VERSION ""

NS_ :

BS_:

BU_: TCM HCM IPMA_ADAS PSCM ABS_ESC TCCM TCM_DSL PCM_HEV PCM ECM_HEVDSL ECM_HEV ECM_Diesel ECM SIMA_DLCS BCMD_IPDB VDM CMR_DSMC SOBDMC_HPCM_FD1 CHCM GWM _delete AWD_DLCM GENERIC TSTR

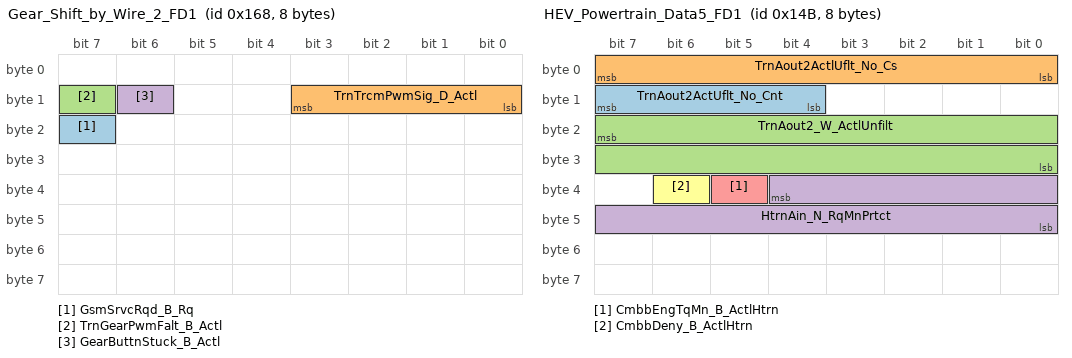
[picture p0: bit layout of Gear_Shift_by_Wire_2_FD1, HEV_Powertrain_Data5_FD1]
BO_ 360 Gear_Shift_by_Wire_2_FD1: 8 GWM
 SG_ GsmSrvcRqd_B_Rq : 23|1@0+ (1,0) [0|1] "SED"  TCM,SOBDMC_HPCM_FD1,TCM_DSL
 SG_ TrnTrcmPwmSig_D_Actl : 11|4@0+ (1,0) [0|15] "SED"  TCM,SOBDMC_HPCM_FD1,ECM_HEV,PCM,PCM_HEV,TCM_DSL
 SG_ TrnGearPwmFalt_B_Actl : 15|1@0+ (1,0) [0|1] "SED"  TCM,SOBDMC_HPCM_FD1,ECM_HEV,PCM,PCM_HEV,TCM_DSL
 SG_ GearButtnStuck_B_Actl : 14|1@0+ (1,0) [0|1] "SED"  TCM,SOBDMC_HPCM_FD1,ECM_HEV,PCM,PCM_HEV,TCM_DSL

BO_ 331 HEV_Powertrain_Data5_FD1: 8 GWM
 SG_ TrnAout2ActUflt_No_Cnt : 15|4@0+ (1,0) [0|15] "Unitless"  GWM,ECM_HEV
 SG_ TrnAout2ActlUflt_No_Cs : 7|8@0+ (1,0) [0|255] "Unitless"  GWM,ECM_HEV
 SG_ TrnAout2_W_ActlUnfilt : 23|16@0+ (0.1,-3276.5) [-3276.5|3276.8] "rad/s"  GWM,ABS_ESC,ECM_HEV
 SG_ HtrnAin_N_RqMnPrtct : 36|13@0+ (2,0) [0|16382] "RPM"  GWM,ECM_HEV
 SG_ CmbbEngTqMn_B_ActlHtrn : 37|1@0+ (1,0) [0|1] "SED"  GWM,ECM_HEV
 SG_ CmbbDeny_B_ActlHtrn : 38|1@0+ (1,0) [0|1] "SED"  GWM,ECM_HEV

BO_ 140 CruiseCtrl_StrgData2_FD1: 8 GWM
 SG_ CcAslButtnIndxIncPress2 : 18|1@0+ (1,0) [0|1] "SED"  ECM,ECM_HEVDSL,PCM
 SG_ SteWhlSwtchMde_D_Stat : 23|2@0+ (1,0) [0|3] "SED"  GENERIC
 SG_ CcAslButtnIndxDecPress2 : 19|1@0+ (1,0) [0|1] "SED"  ECM,ECM_HEVDSL,PCM
 SG_ CcAslButtnResIncPress3 : 29|1@0+ (1,0) [0|1] "SED"  PCM,ECM_HEVDSL,ECM
 SG_ CcButtnOnPress3 : 37|1@0+ (1,0) [0|1] "SED"  PCM,ECM_HEVDSL,ECM
 SG_ CcButtnOnOffPress3 : 38|1@0+ (1,0) [0|1] "SED"  PCM,ECM_HEVDSL,ECM
 SG_ CcButtnOnOffCnclPress3 : 39|1@0+ (1,0) [0|1] "SED"  PCM,ECM_HEVDSL,ECM
 SG_ CcButtnOffPress3 : 24|1@0+ (1,0) [0|1] "SED"  PCM,ECM_HEVDSL,ECM
 SG_ CcAsllButtnResPress3 : 25|1@0+ (1,0) [0|1] "SED"  PCM,ECM_HEVDSL,ECM
 SG_ CcAslButtnSetPress3 : 26|1@0+ (1,0) [0|1] "SED"  PCM,ECM_HEVDSL,ECM
 SG_ CcAslButtnSetIncPress3 : 27|1@0+ (1,0) [0|1] "SED"  PCM,ECM_HEVDSL,ECM
 SG_ CcAslButtnSetDecPress3 : 28|1@0+ (1,0) [0|1] "SED"  PCM,ECM_HEVDSL,ECM
 SG_ CcAslButtnResDecPress3 : 30|1@0+ (1,0) [0|1] "SED"  PCM,ECM_HEVDSL,ECM
 SG_ CcAslButtnOnPress3 : 31|1@0+ (1,0) [0|1] "SED"  PCM,ECM_HEVDSL,ECM
 SG_ CcAslButtnOnOffCncl3 : 16|1@0+ (1,0) [0|1] "SED"  PCM,ECM_HEVDSL,ECM
 SG_ CcAslButtnDeny_B_Actl3 : 20|1@0+ (1,0) [0|1] "SED"  PCM,ECM_HEVDSL,ECM
 SG_ CcAslButtnCnclPress3 : 8|1@0+ (1,0) [0|1] "SED"  PCM,ECM_HEVDSL,ECM
 SG_ AslButtnOnOffPress3 : 9|1@0+ (1,0) [0|1] "SED"  PCM,ECM_HEVDSL,ECM
 SG_ AslButtnOnOffCnclPress2 : 10|1@0+ (1,0) [0|1] "SED"  PCM,ECM_HEVDSL,ECM
 SG_ CcAslButtnOffCnclPress2 : 17|1@0+ (1,0) [0|1] "SED"  ECM_HEVDSL,PCM,ECM
 SG_ CcAslButtnCnclResPress2 : 21|1@0+ (1,0) [0|1] "SED"  ECM,ECM_HEVDSL,PCM

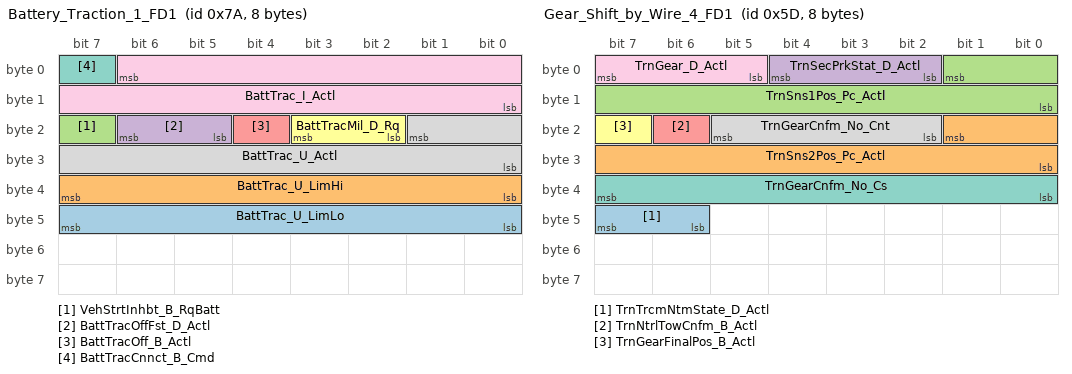
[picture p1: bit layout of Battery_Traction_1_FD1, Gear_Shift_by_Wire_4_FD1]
BO_ 122 Battery_Traction_1_FD1: 8 GWM
 SG_ BattTrac_U_LimLo : 47|8@0+ (2,0) [0|510] "volt"  SOBDMC_HPCM_FD1,PCM_HEV
 SG_ BattTrac_U_LimHi : 39|8@0+ (2,0) [0|510] "volt"  SOBDMC_HPCM_FD1,PCM_HEV
 SG_ VehStrtInhbt_B_RqBatt : 23|1@0+ (1,0) [0|1] "SED"  SOBDMC_HPCM_FD1,PCM_HEV,ECM_HEVDSL
 SG_ BattTracOffFst_D_Actl : 22|2@0+ (1,0) [0|3] "SED"  SOBDMC_HPCM_FD1,ECM_HEV,ECM_HEVDSL,PCM_HEV
 SG_ BattTracOff_B_Actl : 20|1@0+ (1,0) [0|1] "SED"  SOBDMC_HPCM_FD1,PCM_HEV
 SG_ BattTracMil_D_Rq : 19|2@0+ (1,0) [0|3] "SED"  PCM_HEV,ECM_HEV
 SG_ BattTracCnnct_B_Cmd : 7|1@0+ (1,0) [0|1] "SED"  SOBDMC_HPCM_FD1,ECM_HEV,ECM_HEVDSL,PCM_HEV
 SG_ BattTrac_U_Actl : 17|10@0+ (0.5,0) [0|510.5] "Volts"  SOBDMC_HPCM_FD1,ECM_HEV,ECM_HEVDSL,PCM_HEV
 SG_ BattTrac_I_Actl : 6|15@0+ (0.05,-750) [-750|888.25] "Amps"  SOBDMC_HPCM_FD1,ECM_HEV,ECM_HEVDSL,PCM_HEV

BO_ 93 Gear_Shift_by_Wire_4_FD1: 8 GWM
 SG_ TrnTrcmNtmState_D_Actl : 47|2@0+ (1,0) [0|3] "SED"  TCM,ECM_HEV,PCM,PCM_HEV,TCM_DSL
 SG_ TrnSns2Pos_Pc_Actl : 17|10@0+ (0.1,0) [0|102.2] "percent duty cycle"  ECM_HEV,PCM,PCM_HEV
 SG_ TrnSns1Pos_Pc_Actl : 1|10@0+ (0.1,0) [0|102.2] "percent duty cycle"  ECM_HEV,PCM,PCM_HEV
 SG_ TrnSecPrkStat_D_Actl : 4|3@0+ (1,0) [0|7] "SED"  ECM_HEV,PCM,PCM_HEV
 SG_ TrnNtrlTowCnfm_B_Actl : 22|1@0+ (1,0) [0|1] "SED"  ECM_HEV,PCM,PCM_HEV
 SG_ TrnGearFinalPos_B_Actl : 23|1@0+ (1,0) [0|1] "SED"  ECM_HEV,PCM,PCM_HEV
 SG_ TrnGearCnfm_No_Cs : 39|8@0+ (1,0) [0|255] "Unitless"  ECM_HEV,PCM,PCM_HEV
 SG_ TrnGearCnfm_No_Cnt : 21|4@0+ (1,0) [0|15] "Unitless"  ECM_HEV,PCM,PCM_HEV
 SG_ TrnGear_D_Actl : 7|3@0+ (1,0) [0|7] "SED"  ECM_HEV,PCM,PCM_HEV

BO_ 90 Gear_Shift_by_Wire_FD1: 8 GWM
 SG_ TrnGsmNtmState_D_Actl : 55|2@0+ (1,0) [0|3] "SED"  TCM,SOBDMC_HPCM_FD1,ABS_ESC,ECM_HEV,PCM,PCM_HEV,TCM_DSL
 SG_ DrQltyDrv_D_StatGsm : 42|3@0+ (1,0) [0|7] "SED"  TCM,SOBDMC_HPCM_FD1,ABS_ESC,ECM,ECM_HEV,ECM_HEVDSL,PCM,PCM_HEV,TCM_DSL,IPMA_ADAS
 SG_ TrnBtsiOvrrd_B_Stat : 43|1@0+ (1,0) [0|1] "SED"  ABS_ESC,TCM,SOBDMC_HPCM_FD1,ECM,ECM_HEV,ECM_HEVDSL,PCM,PCM_HEV,TCM_DSL
 SG_ GsmGearMsgTxt_D_Rq : 63|2@0+ (1,0) [0|3] "SED"  SOBDMC_HPCM_FD1,GENERIC
 SG_ TrnRng_D_RqGsm : 51|4@0+ (1,0) [0|15] "SED"  TCM,SOBDMC_HPCM_FD1,ECM,ECM_HEV,ECM_HEVDSL,PCM,TCM_DSL
 SG_ PrkBrkActv_D_RqGsmGear : 53|2@0+ (1,0) [0|3] "SED"  SOBDMC_HPCM_FD1,ABS_ESC
 SG_ TrnValidGearRq_D_Stat : 25|2@0+ (1,0) [0|3] "SED"  ABS_ESC,TCM,SOBDMC_HPCM_FD1,ECM_HEV,PCM,PCM_HEV,TCM_DSL
 SG_ TrnGearRqCnt_B_Actl : 26|1@0+ (1,0) [0|1] "unitless"  ABS_ESC,TCM,SOBDMC_HPCM_FD1,ECM_HEV,PCM,PCM_HEV,TCM_DSL
 SG_ TrnGearButtn_U_Actl : 23|8@0+ (0.05,0) [0|12.7] "VOLT"  TCM,SOBDMC_HPCM_FD1,ECM_HEV,PCM,PCM_HEV,TCM_DSL
 SG_ TrnGearButtn_B_ActlR2 : 8|1@0+ (1,0) [0|1] "SED"  TCM,SOBDMC_HPCM_FD1,ECM_HEV,PCM,PCM_HEV,TCM_DSL
 SG_ TrnGearButtn_B_ActlR1 : 9|1@0+ (1,0) [0|1] "SED"  TCM,SOBDMC_HPCM_FD1,ECM_HEV,PCM,PCM_HEV,TCM_DSL
 SG_ TrnGearButtn_B_ActlR0 : 10|1@0+ (1,0) [0|1] "SED"  TCM,SOBDMC_HPCM_FD1,ECM_HEV,PCM,PCM_HEV,TCM_DSL
 SG_ TrnGearButtn_B_ActlP2 : 11|1@0+ (1,0) [0|1] "SED"  TCM,SOBDMC_HPCM_FD1,TCM_DSL,ECM_HEV,PCM,PCM_HEV
 SG_ TrnGearButtn_B_ActlP1 : 12|1@0+ (1,0) [0|1] "SED"  TCM,SOBDMC_HPCM_FD1,ECM_HEV,PCM,PCM_HEV,TCM_DSL
 SG_ TrnGearButtn_B_ActlP0 : 13|1@0+ (1,0) [0|1] "SED"  TCM,SOBDMC_HPCM_FD1,ECM_HEV,PCM,PCM_HEV,TCM_DSL
 SG_ TrnGearButtn_B_ActlN2 : 14|1@0+ (1,0) [0|1] "SED"  TCM,SOBDMC_HPCM_FD1,ECM_HEV,PCM,PCM_HEV,TCM_DSL
 SG_ TrnGearButtn_B_ActlN1 : 15|1@0+ (1,0) [0|1] "SED"  TCM,SOBDMC_HPCM_FD1,ECM_HEV,PCM,PCM_HEV,TCM_DSL
 SG_ TrnGearButtn_B_ActlN0 : 0|1@0+ (1,0) [0|1] "SED"  TCM,SOBDMC_HPCM_FD1,ECM_HEV,PCM,PCM_HEV,TCM_DSL
 SG_ TrnGearButtn_B_ActlM2 : 1|1@0+ (1,0) [0|1] "SED"  TCM,SOBDMC_HPCM_FD1,ECM_HEV,PCM,PCM_HEV,TCM_DSL
 SG_ TrnGearButtn_B_ActlM1 : 2|1@0+ (1,0) [0|1] "SED"  TCM,SOBDMC_HPCM_FD1,ECM_HEV,PCM,PCM_HEV,TCM_DSL
 SG_ TrnGearButtn_B_ActlM0 : 3|1@0+ (1,0) [0|1] "SED"  TCM,SOBDMC_HPCM_FD1,ECM_HEV,PCM,PCM_HEV,TCM_DSL
 SG_ TrnGearButtn_B_ActlD2 : 4|1@0+ (1,0) [0|1] "SED"  TCM,SOBDMC_HPCM_FD1,ECM_HEV,PCM,PCM_HEV,TCM_DSL
 SG_ TrnGearButtn_B_ActlD1 : 5|1@0+ (1,0) [0|1] "SED"  TCM,SOBDMC_HPCM_FD1,ECM_HEV,PCM,PCM_HEV,TCM_DSL
 SG_ TrnGearButtn_B_ActlD0 : 6|1@0+ (1,0) [0|1] "SED"  TCM,SOBDMC_HPCM_FD1,ECM_HEV,PCM,PCM_HEV,TCM_DSL
 SG_ TrnGear_No_Cs : 39|8@0+ (1,0) [0|255] "Unitless"  ABS_ESC,TCM,SOBDMC_HPCM_FD1,ECM_HEV,PCM,PCM_HEV,TCM_DSL
 SG_ TrnGear_No_Cnt : 47|4@0+ (1,0) [0|15] "Unitless"  ABS_ESC,TCM,SOBDMC_HPCM_FD1,ECM_HEV,PCM,PCM_HEV,TCM_DSL
 SG_ TrnGear_D_RqDrv : 31|5@0+ (1,0) [0|31] "SED"  ABS_ESC,TCM,SOBDMC_HPCM_FD1,ECM_HEV,PCM,PCM_HEV,TCM_DSL
 SG_ BrkSwtchPos_B_ActlGsm : 7|1@0+ (1,0) [0|1] "SED"  ABS_ESC,TCM,SOBDMC_HPCM_FD1,ECM_HEV,PCM,PCM_HEV,TCM_DSL

BO_ 1114 TrailerAid_Data_FD1: 8 GWM
 SG_ TrailCtlSwtch_B_Stat2 : 16|1@0+ (1,0) [0|1] "SED"  ABS_ESC
 SG_ TrlBrkInitOut_D_Rq : 60|2@0+ (1,0) [0|3] "SED"  GENERIC

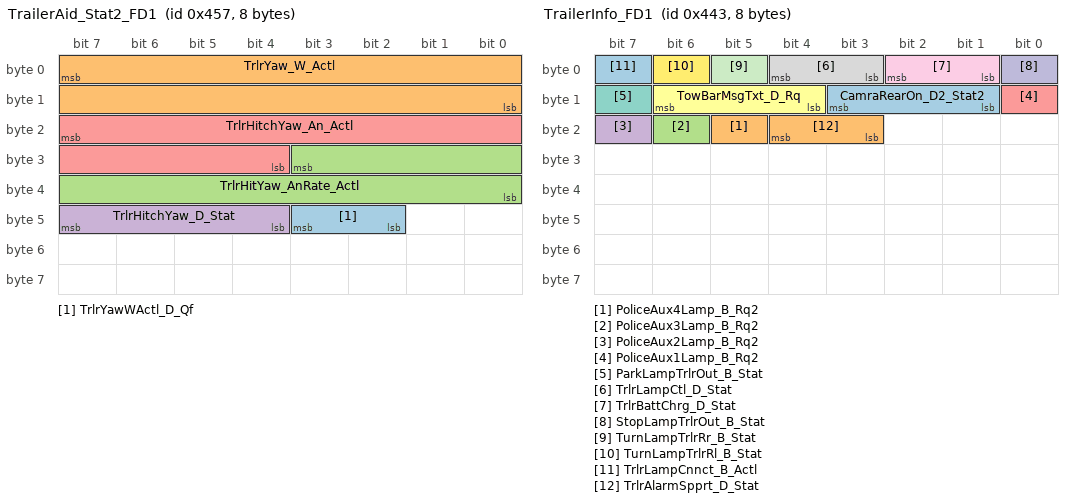
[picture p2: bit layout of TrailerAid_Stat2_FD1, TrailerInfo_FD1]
BO_ 1111 TrailerAid_Stat2_FD1: 8 GWM
 SG_ TrlrYawWActl_D_Qf : 43|2@0+ (1,0) [0|3] "SED"  IPMA_ADAS,PSCM
 SG_ TrlrYaw_W_Actl : 7|16@0+ (0.0002,-6.5) [-6.5|6.6066] "radians/second"  IPMA_ADAS,PSCM
 SG_ TrlrHitYaw_AnRate_Actl : 27|12@0+ (0.1,-50) [-50|359.3] "degrees/second"  IPMA_ADAS,PSCM
 SG_ TrlrHitchYaw_D_Stat : 47|4@0+ (1,0) [0|15] "SED"  IPMA_ADAS,PSCM
 SG_ TrlrHitchYaw_An_Actl : 23|12@0+ (0.1,-90) [-90|319.3] "degrees"  IPMA_ADAS,PSCM

BO_ 1106 TrailerAid_Stat1_FD1: 8 GWM
 SG_ TrlrSnsId_No_Actl : 7|48@0+ (1,0) [0|281474976710653] "unitless"  PSCM,IPMA_ADAS

BO_ 1091 TrailerInfo_FD1: 8 GWM
 SG_ CamraRearOn_D2_Stat2 : 11|3@0+ (1,0) [0|7] "SED"  GENERIC
 SG_ PoliceAux4Lamp_B_Rq2 : 21|1@0+ (1,0) [0|1] "SED"  GENERIC
 SG_ PoliceAux3Lamp_B_Rq2 : 22|1@0+ (1,0) [0|1] "SED"  GENERIC
 SG_ PoliceAux2Lamp_B_Rq2 : 23|1@0+ (1,0) [0|1] "SED"  GENERIC
 SG_ PoliceAux1Lamp_B_Rq2 : 8|1@0+ (1,0) [0|1] "SED"  GENERIC
 SG_ TowBarMsgTxt_D_Rq : 14|3@0+ (1,0) [0|7] "SED"  GENERIC
 SG_ ParkLampTrlrOut_B_Stat : 15|1@0+ (1,0) [0|1] "SED"  GENERIC
 SG_ TrlrLampCtl_D_Stat : 4|2@0+ (1,0) [0|3] "SED"  GENERIC
 SG_ TrlrBattChrg_D_Stat : 2|2@0+ (1,0) [0|3] "SED"  GENERIC
 SG_ StopLampTrlrOut_B_Stat : 0|1@0+ (1,0) [0|1] "SED"  GENERIC
 SG_ TurnLampTrlrRr_B_Stat : 5|1@0+ (1,0) [0|1] "SED"  GENERIC
 SG_ TurnLampTrlrRl_B_Stat : 6|1@0+ (1,0) [0|1] "SED"  GENERIC
 SG_ TrlrLampCnnct_B_Actl : 7|1@0+ (1,0) [0|1] "SED"  TCM,VDM,ECM,ECM_Diesel,ECM_HEV,ECM_HEVDSL,PCM,PCM_HEV,TCM_DSL,ABS_ESC,IPMA_ADAS,PSCM,AWD_DLCM
 SG_ TrlrAlarmSpprt_D_Stat : 20|2@0+ (1,0) [0|3] "SED"  GENERIC

BO_ 138 ActiveFrontStrg_Stat2_FD1: 8 GWM
 SG_ SteWhlRelCalib_T_Actl : 7|8@0+ (1,0) [0|255] "ms"  ABS_ESC
 SG_ SteWhlRelCalib_An_Sns : 15|15@0+ (0.1,-1600) [-1600|1676.5] "deg"  CMR_DSMC,ABS_ESC,PSCM,TCCM

BO_ 131 Steering_Data_FD1: 8 GWM
 SG_ HeadLghtHiCtrl_D_RqAhb : 43|3@0+ (1,0) [0|7] "SED"  HCM,GENERIC
 SG_ AhbStat_B_Dsply : 33|1@0+ (1,0) [0|1] "SED"  GENERIC
 SG_ WiprFrontSwtch_D_Stat : 47|4@0+ (1,0) [0|15] "SED"  GENERIC
 SG_ HeadLghtHiOn_B_StatAhb : 34|1@0+ (1,0) [0|1] "SED"  IPMA_ADAS
 SG_ HeadLghtHiFlash_D_Actl : 36|2@0+ (1,0) [0|3] "SED"  HCM,IPMA_ADAS
 SG_ TjaButtnOnOffPress : 40|1@0+ (1,0) [0|1] "SED"  ECM,ECM_Diesel,ECM_HEVDSL,IPMA_ADAS,PCM,PCM_HEV
 SG_ AccButtnGapTogglePress : 32|1@0+ (1,0) [0|1] "SED"  IPMA_ADAS
 SG_ WiprFront_D_Stat : 3|4@0+ (1,0) [0|15] "SED"  HCM,ABS_ESC,ECM,ECM_Diesel,ECM_HEV,ECM_HEVDSL,IPMA_ADAS,PCM,PCM_HEV,AWD_DLCM
 SG_ TurnLghtSwtch_D_Stat : 5|2@0+ (1,0) [0|3] "SED"  HCM,IPMA_ADAS,PSCM
 SG_ LghtAmb_D_Sns : 15|3@0+ (1,0) [0|7] "SED"  HCM,IPMA_ADAS
 SG_ AccButtnGapIncPress : 11|1@0+ (1,0) [0|1] "SED"  IPMA_ADAS
 SG_ AccButtnGapDecPress : 12|1@0+ (1,0) [0|1] "SED"  IPMA_ADAS
 SG_ AslButtnOnOffPress : 9|1@0+ (1,0) [0|1] "SED"  ECM,ECM_Diesel,ECM_HEV,ECM_HEVDSL,PCM,PCM_HEV
 SG_ AslButtnOnOffCnclPress : 10|1@0+ (1,0) [0|1] "SED"  ECM,ECM_Diesel,ECM_HEV,ECM_HEVDSL,PCM,PCM_HEV
 SG_ CcButtnOnPress : 37|1@0+ (1,0) [0|1] "SED"  ECM,ECM_Diesel,ECM_HEV,ECM_HEVDSL,IPMA_ADAS,PCM,PCM_HEV
 SG_ CcButtnOnOffPress : 38|1@0+ (1,0) [0|1] "SED"  ECM,ECM_Diesel,ECM_HEV,ECM_HEVDSL,IPMA_ADAS,PCM,PCM_HEV
 SG_ CcButtnOnOffCnclPress : 39|1@0+ (1,0) [0|1] "SED"  ECM,ECM_Diesel,ECM_HEV,ECM_HEVDSL,IPMA_ADAS,PCM,PCM_HEV
 SG_ CcButtnOffPress : 24|1@0+ (1,0) [0|1] "SED"  ECM,ECM_Diesel,ECM_HEV,ECM_HEVDSL,IPMA_ADAS,PCM,PCM_HEV
 SG_ CcAsllButtnResPress : 25|1@0+ (1,0) [0|1] "SED"  ECM,ECM_Diesel,ECM_HEV,ECM_HEVDSL,IPMA_ADAS,PCM,PCM_HEV
 SG_ CcAslButtnSetPress : 26|1@0+ (1,0) [0|1] "SED"  ECM,ECM_Diesel,ECM_HEV,ECM_HEVDSL,PCM,PCM_HEV
 SG_ CcAslButtnSetIncPress : 27|1@0+ (1,0) [0|1] "SED"  ABS_ESC,ECM,ECM_Diesel,ECM_HEV,ECM_HEVDSL,IPMA_ADAS,PCM,PCM_HEV
 SG_ CcAslButtnSetDecPress : 28|1@0+ (1,0) [0|1] "SED"  ABS_ESC,ECM,ECM_Diesel,ECM_HEV,ECM_HEVDSL,IPMA_ADAS,PCM,PCM_HEV
 SG_ CcAslButtnResIncPress : 29|1@0+ (1,0) [0|1] "SED"  ABS_ESC,ECM,ECM_Diesel,ECM_HEV,ECM_HEVDSL,IPMA_ADAS,PCM,PCM_HEV
 SG_ CcAslButtnResDecPress : 30|1@0+ (1,0) [0|1] "SED"  ECM,ECM_Diesel,ECM_HEV,ECM_HEVDSL,PCM,PCM_HEV
 SG_ CcAslButtnOnPress : 31|1@0+ (1,0) [0|1] "SED"  ECM,ECM_Diesel,ECM_HEV,ECM_HEVDSL,IPMA_ADAS,PCM,PCM_HEV
 SG_ CcAslButtnOnOffCncl : 16|1@0+ (1,0) [0|1] "SED"  ECM,ECM_Diesel,ECM_HEV,ECM_HEVDSL,PCM,PCM_HEV
 SG_ CcAslButtnOffCnclPress : 17|1@0+ (1,0) [0|1] "SED"  ECM,ECM_Diesel,ECM_HEV,ECM_HEVDSL,PCM,PCM_HEV
 SG_ CcAslButtnIndxIncPress : 18|1@0+ (1,0) [0|1] "SED"  ECM,ECM_Diesel,ECM_HEV,ECM_HEVDSL,PCM,PCM_HEV
 SG_ CcAslButtnIndxDecPress : 19|1@0+ (1,0) [0|1] "SED"  ECM,ECM_Diesel,ECM_HEV,ECM_HEVDSL,PCM,PCM_HEV
 SG_ CcAslButtnDeny_B_Actl : 20|1@0+ (1,0) [0|1] "SED"  ECM,ECM_Diesel,ECM_HEV,ECM_HEVDSL,IPMA_ADAS,PCM,PCM_HEV
 SG_ CcAslButtnCnclResPress : 21|1@0+ (1,0) [0|1] "SED"  ECM,ECM_Diesel,ECM_HEV,ECM_HEVDSL,IPMA_ADAS,PCM,PCM_HEV
 SG_ CcAslButtnCnclPress : 8|1@0+ (1,0) [0|1] "SED"  ECM,ECM_Diesel,ECM_HEV,ECM_HEVDSL,IPMA_ADAS,PCM,PCM_HEV
 SG_ LaSwtchPos_D_Stat : 23|2@0+ (1,0) [0|3] "SED"  IPMA_ADAS
 SG_ HeadLghtHiFlash_D_Stat : 7|2@0+ (1,0) [0|3] "SED"  HCM,GENERIC

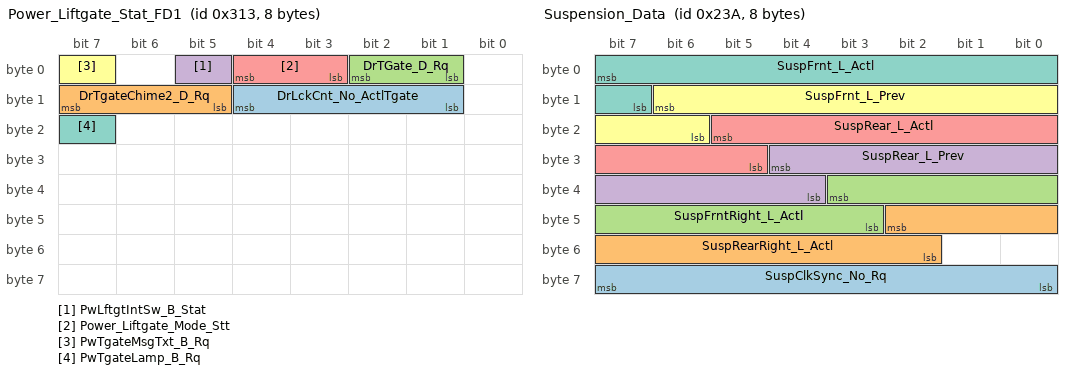
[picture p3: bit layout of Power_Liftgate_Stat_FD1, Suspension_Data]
BO_ 787 Power_Liftgate_Stat_FD1: 8 GWM
 SG_ DrLckCnt_No_ActlTgate : 12|4@0+ (1,0) [0|15] "unitless"  GENERIC
 SG_ DrTgateChime2_D_Rq : 15|3@0+ (1,0) [0|7] "SED"  GENERIC
 SG_ DrTGate_D_Rq : 2|2@0+ (1,0) [0|3] "SED"  ECM,ECM_Diesel,ECM_HEVDSL,PCM,PCM_HEV
 SG_ PwLftgtIntSw_B_Stat : 5|1@0+ (1,0) [0|1] "SED"  GENERIC
 SG_ Power_Liftgate_Mode_Stt : 4|2@0+ (1,0) [0|3] "SED"  GENERIC
 SG_ PwTgateMsgTxt_B_Rq : 7|1@0+ (1,0) [0|1] "SED"  GENERIC
 SG_ PwTgateLamp_B_Rq : 23|1@0+ (1,0) [0|1] "SED"  GENERIC

BO_ 570 Suspension_Data: 8 VDM
 SG_ SuspClkSync_No_Rq : 63|8@0+ (1,0) [0|253] "unitless"  GWM,IPMA_ADAS
 SG_ SuspRearRight_L_Actl : 42|9@0+ (0.782779,-200) [-200|199.21729] "millimeter"  HCM,GWM,ABS_ESC,PSCM,IPMA_ADAS
 SG_ SuspFrntRight_L_Actl : 35|9@0+ (0.782779,-200) [-200|199.21729] "millimeter"  HCM,ABS_ESC,PSCM,GWM,IPMA_ADAS
 SG_ SuspRear_L_Prev : 28|9@0+ (0.782779,-200) [-200|199.21729] "millimeter"  HCM,ABS_ESC,GWM
 SG_ SuspRear_L_Actl : 21|9@0+ (0.782779,-200) [-200|199.21729] "millimeter"  HCM,ABS_ESC,PSCM,GWM,IPMA_ADAS
 SG_ SuspFrnt_L_Prev : 14|9@0+ (0.782779,-200) [-200|199.21729] "millimeter"  HCM,ABS_ESC,GWM
 SG_ SuspFrnt_L_Actl : 7|9@0+ (0.782779,-200) [-200|199.21729] "millimeter"  HCM,PSCM,ABS_ESC,GWM,IPMA_ADAS

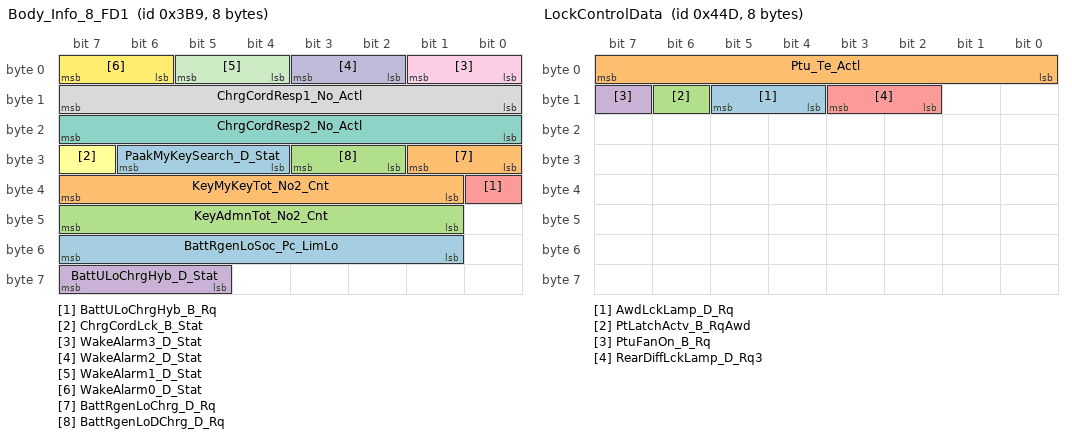
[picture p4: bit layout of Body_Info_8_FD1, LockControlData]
BO_ 953 Body_Info_8_FD1: 8 GWM
 SG_ PaakMyKeySearch_D_Stat : 30|3@0+ (1,0) [0|7] "SED"  GENERIC
 SG_ KeyMyKeyTot_No2_Cnt : 39|7@0+ (1,0) [0|127] "unitless"  GENERIC
 SG_ KeyAdmnTot_No2_Cnt : 47|7@0+ (1,0) [0|127] "unitless"  GENERIC
 SG_ BattULoChrgHyb_D_Stat : 63|3@0+ (1,0) [0|7] "SED"  GENERIC
 SG_ BattULoChrgHyb_B_Rq : 32|1@0+ (1,0) [0|1] "SED"  SOBDMC_HPCM_FD1
 SG_ ChrgCordLck_B_Stat : 31|1@0+ (1,0) [0|1] "SED"  GENERIC
 SG_ ChrgCordResp2_No_Actl : 23|8@0+ (1,0) [0|255] "unitless"  GENERIC
 SG_ ChrgCordResp1_No_Actl : 15|8@0+ (1,0) [0|255] "unitless"  GENERIC
 SG_ WakeAlarm3_D_Stat : 1|2@0+ (1,0) [0|3] "SED"  GENERIC
 SG_ WakeAlarm2_D_Stat : 3|2@0+ (1,0) [0|3] "SED"  GENERIC
 SG_ WakeAlarm1_D_Stat : 5|2@0+ (1,0) [0|3] "SED"  ECM_Diesel,ECM_HEV,ECM_HEVDSL,PCM,PCM_HEV,ECM
 SG_ WakeAlarm0_D_Stat : 7|2@0+ (1,0) [0|3] "SED"  SOBDMC_HPCM_FD1,GENERIC
 SG_ BattRgenLoSoc_Pc_LimLo : 55|7@0+ (1,0) [0|100] "percent"  GENERIC
 SG_ BattRgenLoChrg_D_Rq : 25|2@0+ (1,0) [0|3] "SED"  PCM,PCM_HEV
 SG_ BattRgenLoDChrg_D_Rq : 27|2@0+ (1,0) [0|3] "SED"  PCM,PCM_HEV

BO_ 1101 LockControlData: 8 AWD_DLCM
 SG_ AwdLckLamp_D_Rq : 13|2@0+ (1,0) [0|3] "SED"  GWM
 SG_ Ptu_Te_Actl : 7|8@0+ (1,-50) [-50|205] "degC"  ECM,ECM_Diesel,ECM_HEVDSL,PCM,GWM
 SG_ PtLatchActv_B_RqAwd : 14|1@0+ (1,0) [0|1] "SED"  ECM,ECM_Diesel,ECM_HEV,ECM_HEVDSL,PCM,PCM_HEV,GWM
 SG_ PtuFanOn_B_Rq : 15|1@0+ (1,0) [0|1] "SED"  ECM,ECM_Diesel,ECM_HEV,ECM_HEVDSL,PCM,PCM_HEV,GWM
 SG_ RearDiffLckLamp_D_Rq3 : 11|2@0+ (1,0) [0|3] "SED"  GWM

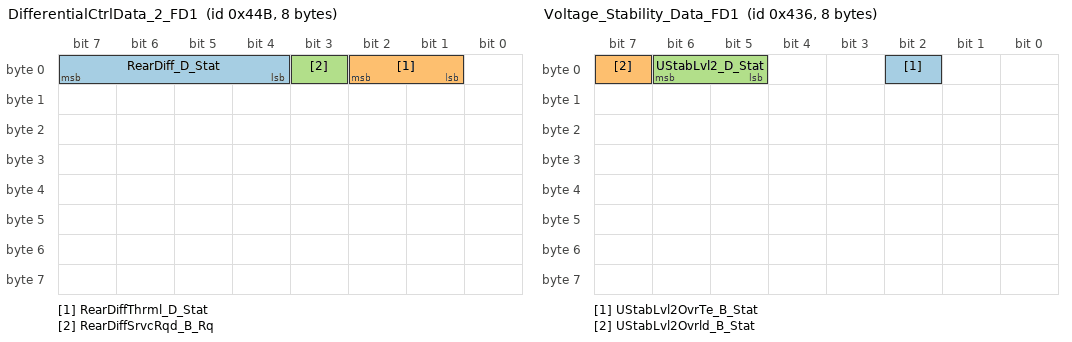
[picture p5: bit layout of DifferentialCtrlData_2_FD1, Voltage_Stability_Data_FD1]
BO_ 1099 DifferentialCtrlData_2_FD1: 8 GWM
 SG_ RearDiff_D_Stat : 7|4@0+ (1,0) [0|15] "SED"  ABS_ESC,PCM
 SG_ RearDiffThrml_D_Stat : 2|2@0+ (1,0) [0|3] "SED"  ECM,ABS_ESC,PCM
 SG_ RearDiffSrvcRqd_B_Rq : 3|1@0+ (1,0) [0|1] "SED"  ABS_ESC

BO_ 1078 Voltage_Stability_Data_FD1: 8 GWM
 SG_ UStabLvl2OvrTe_B_Stat : 2|1@0+ (1,0) [0|1] "SED"  ECM,ECM_Diesel,ECM_HEVDSL,PCM,PCM_HEV
 SG_ UStabLvl2Ovrld_B_Stat : 7|1@0+ (1,0) [0|1] "SED"  ECM,ECM_Diesel,ECM_HEVDSL,PCM,PCM_HEV
 SG_ UStabLvl2_D_Stat : 6|2@0+ (1,0) [0|3] "SED"  ECM,ECM_Diesel,ECM_HEVDSL,PCM,PCM_HEV

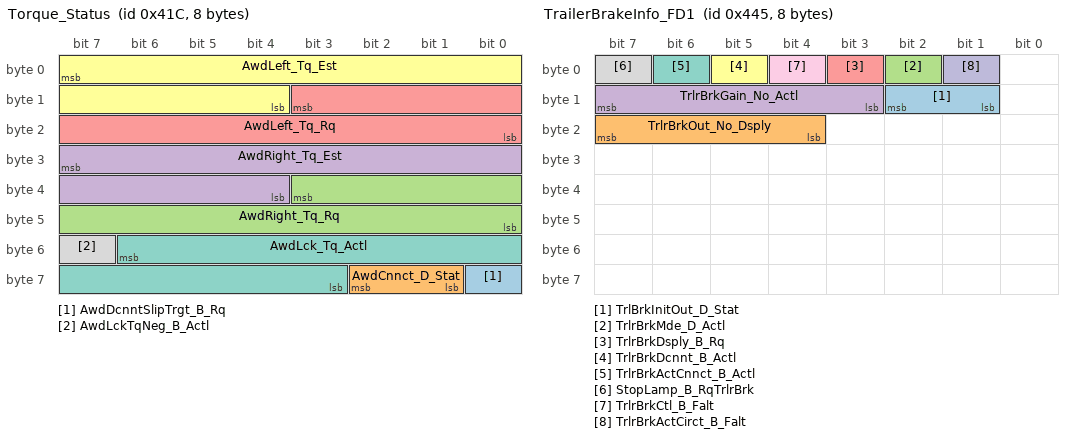
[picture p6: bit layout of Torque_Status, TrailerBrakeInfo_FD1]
BO_ 1052 Torque_Status: 8 AWD_DLCM
 SG_ AwdDcnntSlipTrgt_B_Rq : 56|1@0+ (1,0) [0|1] "SED"  ABS_ESC,GWM
 SG_ AwdCnnct_D_Stat : 58|2@0+ (1,0) [0|3] "SED"  ABS_ESC,GWM
 SG_ AwdRight_Tq_Rq : 35|12@0+ (1,0) [0|4093] "Nm"  ABS_ESC,GWM
 SG_ AwdRight_Tq_Est : 31|12@0+ (1,0) [0|4093] "Nm"  ABS_ESC,PCM,PCM_HEV,GWM
 SG_ AwdLeft_Tq_Rq : 11|12@0+ (1,0) [0|4093] "Nm"  ABS_ESC,GWM
 SG_ AwdLeft_Tq_Est : 7|12@0+ (1,0) [0|4093] "Nm"  ABS_ESC,PCM,PCM_HEV,GWM
 SG_ AwdLck_Tq_Actl : 54|12@0+ (1,0) [0|4093] "Nm"  SOBDMC_HPCM_FD1,ABS_ESC,PCM,PCM_HEV,PSCM,TCM,TCM_DSL,GWM
 SG_ AwdLckTqNeg_B_Actl : 55|1@0+ (1,0) [0|1] "SED"  ABS_ESC,PSCM,GWM,TCM,TCM_DSL

BO_ 1093 TrailerBrakeInfo_FD1: 8 GWM
 SG_ TrlBrkInitOut_D_Stat : 10|2@0+ (1,0) [0|3] "SED"  GENERIC
 SG_ TrlrBrkOut_No_Dsply : 23|4@0+ (1,0) [0|15] "unitless"  GENERIC
 SG_ TrlrBrkMde_D_Actl : 2|1@0+ (1,0) [0|1] "SED"  TCCM
 SG_ TrlrBrkGain_No_Actl : 15|5@0+ (0.5,0) [0|15.5] "unitless"  GENERIC
 SG_ TrlrBrkDsply_B_Rq : 3|1@0+ (1,0) [0|1] "SED"  GENERIC
 SG_ TrlrBrkDcnnt_B_Actl : 5|1@0+ (1,0) [0|1] "SED"  VDM,GENERIC
 SG_ TrlrBrkActCnnct_B_Actl : 6|1@0+ (1,0) [0|1] "SED"  TCM,VDM,ECM,ECM_Diesel,ECM_HEV,ECM_HEVDSL,PCM,PCM_HEV,TCM_DSL,ABS_ESC,PSCM,TCCM,IPMA_ADAS
 SG_ StopLamp_B_RqTrlrBrk : 7|1@0+ (1,0) [0|1] "SED"  GENERIC
 SG_ TrlrBrkCtl_B_Falt : 4|1@0+ (1,0) [0|1] "SED"  IPMA_ADAS
 SG_ TrlrBrkActCirct_B_Falt : 1|1@0+ (1,0) [0|1] "SED"  IPMA_ADAS

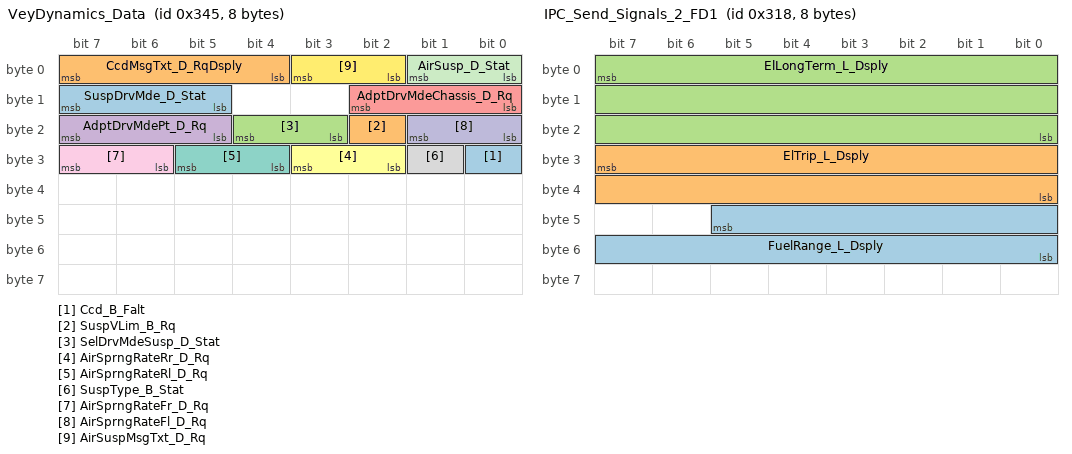
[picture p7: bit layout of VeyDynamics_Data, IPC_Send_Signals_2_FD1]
BO_ 837 VeyDynamics_Data: 8 VDM
 SG_ Ccd_B_Falt : 24|1@0+ (1,0) [0|1] "SED"  GWM,GENERIC
 SG_ SuspVLim_B_Rq : 18|1@0+ (1,0) [0|1] "SED"  GWM,ECM
 SG_ SelDrvMdeSusp_D_Stat : 20|2@0+ (1,0) [0|3] "SED"  GWM,ABS_ESC
 SG_ AdptDrvMdePt_D_Rq : 23|3@0+ (1,0) [0|7] "SED"  GWM,ABS_ESC
 SG_ AdptDrvMdeChassis_D_Rq : 10|3@0+ (1,0) [0|7] "SED"  GWM,ABS_ESC
 SG_ AirSprngRateRr_D_Rq : 27|2@0+ (1,0) [0|3] "SED"  GWM,GENERIC
 SG_ AirSprngRateRl_D_Rq : 29|2@0+ (1,0) [0|3] "SED"  GWM,GENERIC
 SG_ SuspType_B_Stat : 25|1@0+ (1,0) [0|1] "SED"  GWM,ECM,PCM
 SG_ AirSprngRateFr_D_Rq : 31|2@0+ (1,0) [0|3] "SED"  GWM,GENERIC
 SG_ AirSprngRateFl_D_Rq : 17|2@0+ (1,0) [0|3] "SED"  GWM,GENERIC
 SG_ AirSusp_D_Stat : 1|2@0+ (1,0) [0|3] "SED"  GWM,GENERIC
 SG_ AirSuspMsgTxt_D_Rq : 3|2@0+ (1,0) [0|3] "SED"  GWM,GENERIC
 SG_ SuspDrvMde_D_Stat : 15|3@0+ (1,0) [0|7] "SED"  GWM,ABS_ESC
 SG_ CcdMsgTxt_D_RqDsply : 7|4@0+ (1,0) [0|15] "SED"  GWM,ECM,ECM_Diesel,ECM_HEVDSL,PCM,PCM_HEV,ABS_ESC,PSCM,AWD_DLCM

BO_ 792 IPC_Send_Signals_2_FD1: 8 GWM
 SG_ FuelRange_L_Dsply : 45|14@0+ (0.1,0) [0|1638.3] "km"  ECM_Diesel,ECM_HEVDSL,ECM
 SG_ ElTrip_L_Dsply : 31|16@0+ (0.1,0) [0|6553.3] "unitless"  GENERIC
 SG_ ElLongTerm_L_Dsply : 7|24@0+ (0.1,0) [0|1677721.3] "unitless"  GENERIC

BO_ 968 Cluster_Lighting_Rq_FD1: 8 GWM
 SG_ RvltnMatchAllw_D_Rq : 58|2@0+ (1,0) [0|3] "SED"  ECM,PCM
 SG_ BrkDrvMde_D_Rq : 18|3@0+ (1,0) [0|7] "SED"  ABS_ESC
 SG_ LnchCtl_N_Rq : 55|8@0+ (50,0) [0|12750] "rpm"  ABS_ESC,PCM,PCM_HEV
 SG_ LnchCtl_D_Rq : 63|2@0+ (1,0) [0|3] "SED"  ABS_ESC,PCM,PCM_HEV
 SG_ CurrentColor_CmdGage : 43|4@0+ (1,0) [0|15] "SED"  GENERIC
 SG_ BlendedColor_CmdGage : 25|2@0+ (1,0) [0|3] "SED"  GENERIC
 SG_ BlendColorRed_CmdGage : 47|4@0+ (1,0) [0|15] "SED"  GENERIC
 SG_ BlendColorGrn_CmdGage : 35|4@0+ (1,0) [0|15] "SED"  GENERIC
 SG_ BlendColorBlue_CmdGage : 39|4@0+ (1,0) [0|15] "SED"  GENERIC
 SG_ Dimming_Level_Cmd : 1|2@0+ (1,0) [0|3] "SED"  GENERIC
 SG_ Current_Color_Cmd : 23|4@0+ (1,0) [0|15] "SED"  GENERIC
 SG_ BlendedColorRed_Cmd : 11|4@0+ (1,0) [0|15] "SED"  GENERIC
 SG_ BlendedColorGreen_Cmd : 15|4@0+ (1,0) [0|15] "SED"  GENERIC
 SG_ BlendedColorBlue_Cmd : 5|4@0+ (1,0) [0|15] "SED"  GENERIC
 SG_ BlendedColor_Cmd : 7|2@0+ (1,0) [0|3] "SED"  GENERIC
 SG_ SuspDrvMde_D_Rq : 61|3@0+ (1,0) [0|7] "SED"  VDM,GENERIC
 SG_ SlMde_D_Rq : 27|2@0+ (1,0) [0|3] "SED"  ECM_HEV,ECM,ECM_Diesel,ECM_HEVDSL,PCM,PCM_HEV
 SG_ IsaOffst_D_Rq : 31|4@0+ (1,0) [0|15] "SED"  ECM_HEV,ECM,ECM_Diesel,ECM_HEVDSL,PCM,PCM_HEV

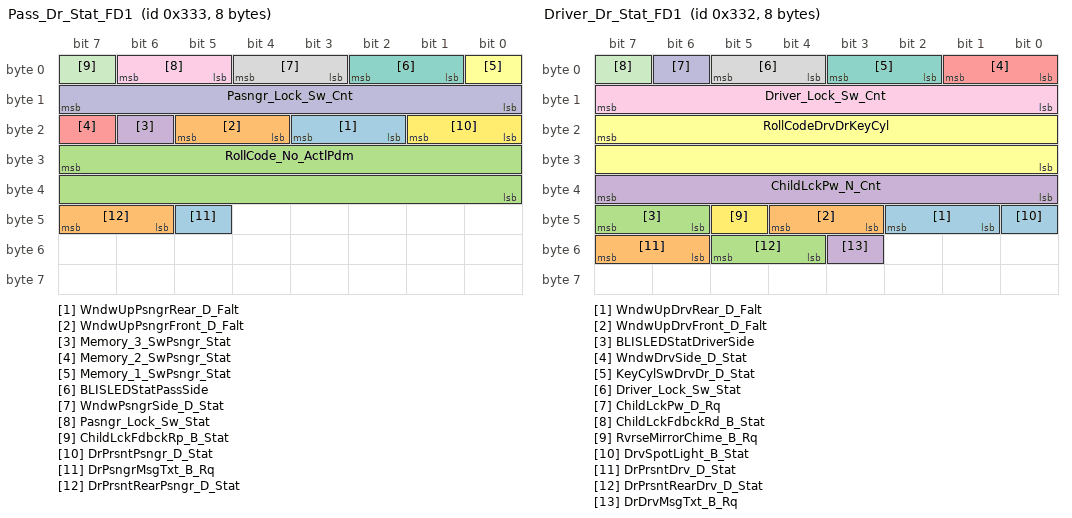
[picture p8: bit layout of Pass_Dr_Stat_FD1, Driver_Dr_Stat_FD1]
BO_ 819 Pass_Dr_Stat_FD1: 8 GWM
 SG_ WndwUpPsngrRear_D_Falt : 19|2@0+ (1,0) [0|3] "SED"  IPMA_ADAS
 SG_ WndwUpPsngrFront_D_Falt : 21|2@0+ (1,0) [0|3] "SED"  IPMA_ADAS
 SG_ RollCode_No_ActlPdm : 31|16@0+ (1,0) [0|65535] "Unitless"  GENERIC
 SG_ Memory_3_SwPsngr_Stat : 22|1@0+ (1,0) [0|1] "SED"  GENERIC
 SG_ Memory_2_SwPsngr_Stat : 23|1@0+ (1,0) [0|1] "SED"  GENERIC
 SG_ Memory_1_SwPsngr_Stat : 0|1@0+ (1,0) [0|1] "SED"  GENERIC
 SG_ BLISLEDStatPassSide : 2|2@0+ (1,0) [0|3] "SED"  IPMA_ADAS
 SG_ WndwPsngrSide_D_Stat : 4|2@0+ (1,0) [0|3] "SED"  ECM,ECM_Diesel,ECM_HEV,ECM_HEVDSL,PCM
 SG_ Pasngr_Lock_Sw_Stat : 6|2@0+ (1,0) [0|3] "SED"  GENERIC
 SG_ Pasngr_Lock_Sw_Cnt : 15|8@0+ (1,0) [0|255] "Cnt"  GENERIC
 SG_ ChildLckFdbckRp_B_Stat : 7|1@0+ (1,0) [0|1] "SED"  GENERIC
 SG_ DrPrsntPsngr_D_Stat : 17|2@0+ (1,0) [0|3] "SED"  GENERIC
 SG_ DrPsngrMsgTxt_B_Rq : 45|1@0+ (1,0) [0|1] "SED"  GENERIC
 SG_ DrPrsntRearPsngr_D_Stat : 47|2@0+ (1,0) [0|3] "SED"  GENERIC

BO_ 818 Driver_Dr_Stat_FD1: 8 GWM
 SG_ WndwUpDrvRear_D_Falt : 42|2@0+ (1,0) [0|3] "SED"  IPMA_ADAS
 SG_ WndwUpDrvFront_D_Falt : 44|2@0+ (1,0) [0|3] "SED"  IPMA_ADAS
 SG_ BLISLEDStatDriverSide : 47|2@0+ (1,0) [0|3] "SED"  IPMA_ADAS
 SG_ ChildLckPw_N_Cnt : 39|8@0+ (1,0) [0|255] "unitless"  GENERIC
 SG_ WndwDrvSide_D_Stat : 1|2@0+ (1,0) [0|3] "SED"  ECM,ECM_Diesel,ECM_HEVDSL,PCM
 SG_ RollCodeDrvDrKeyCyl : 23|16@0+ (1,0) [0|65535] "Unitless"  GENERIC
 SG_ KeyCylSwDrvDr_D_Stat : 3|2@0+ (1,0) [0|3] "SED"  GENERIC
 SG_ Driver_Lock_Sw_Stat : 5|2@0+ (1,0) [0|3] "SED"  GENERIC
 SG_ Driver_Lock_Sw_Cnt : 15|8@0+ (1,0) [0|255] "Cnt"  GENERIC
 SG_ ChildLckPw_D_Rq : 6|1@0+ (1,0) [0|1] "SED"  GENERIC
 SG_ ChildLckFdbckRd_B_Stat : 7|1@0+ (1,0) [0|1] "SED"  GENERIC
 SG_ RvrseMirrorChime_B_Rq : 45|1@0+ (1,0) [0|1] "SED"  GENERIC
 SG_ DrvSpotLight_B_Stat : 40|1@0+ (1,0) [0|1] "SED"  GENERIC
 SG_ DrPrsntDrv_D_Stat : 55|2@0+ (1,0) [0|3] "SED"  PCM,PCM_HEV,ABS_ESC
 SG_ DrPrsntRearDrv_D_Stat : 53|2@0+ (1,0) [0|3] "SED"  GENERIC
 SG_ DrDrvMsgTxt_B_Rq : 51|1@0+ (1,0) [0|1] "SED"  GENERIC

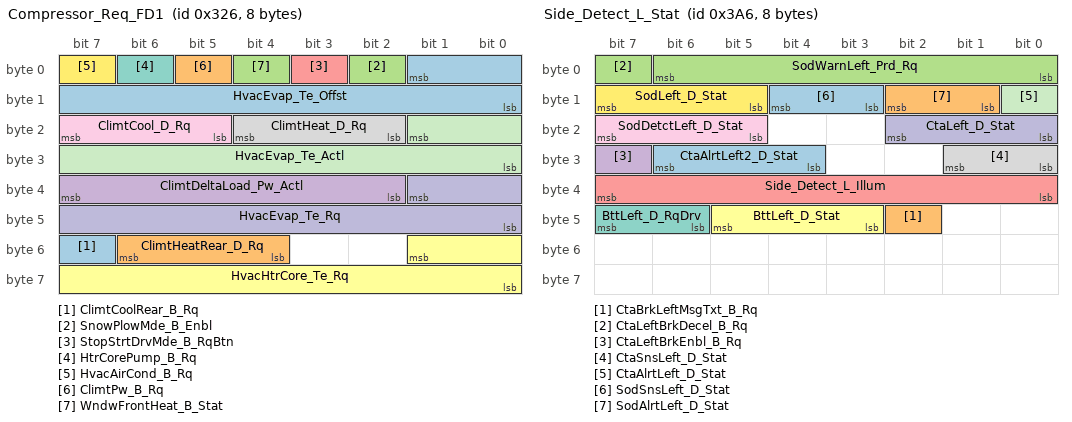
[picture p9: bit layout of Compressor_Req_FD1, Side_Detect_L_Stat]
BO_ 806 Compressor_Req_FD1: 8 GWM
 SG_ ClimtCoolRear_B_Rq : 55|1@0+ (1,0) [0|1] "SED"  SOBDMC_HPCM_FD1,GENERIC
 SG_ ClimtHeatRear_D_Rq : 54|3@0+ (1,0) [0|7] "SED"  SOBDMC_HPCM_FD1,GENERIC
 SG_ SnowPlowMde_B_Enbl : 2|1@0+ (1,0) [0|1] "SED"  GENERIC
 SG_ ClimtDeltaLoad_Pw_Actl : 39|6@0+ (50,-1600) [-1600|1450] "watts"  ECM,ECM_Diesel,ECM_HEV,ECM_HEVDSL,PCM,PCM_HEV
 SG_ StopStrtDrvMde_B_RqBtn : 3|1@0+ (1,0) [0|1] "SED"  ECM,ECM_Diesel,ECM_HEVDSL,PCM,PCM_HEV
 SG_ HvacHtrCore_Te_Rq : 49|10@0+ (0.25,-50) [-50|205.75] "degC"  SOBDMC_HPCM_FD1,ECM,ECM_Diesel,ECM_HEV,ECM_HEVDSL,PCM_HEV
 SG_ HtrCorePump_B_Rq : 6|1@0+ (1,0) [0|1] "SED"  ECM,ECM_Diesel,ECM_HEV,ECM_HEVDSL,PCM,PCM_HEV
 SG_ ClimtHeat_D_Rq : 20|3@0+ (1,0) [0|7] "SED"  SOBDMC_HPCM_FD1,ECM,ECM_Diesel,ECM_HEV,ECM_HEVDSL,PCM,PCM_HEV
 SG_ ClimtCool_D_Rq : 23|3@0+ (1,0) [0|7] "SED"  SOBDMC_HPCM_FD1,ECM,ECM_Diesel,ECM_HEV,ECM_HEVDSL,PCM,PCM_HEV
 SG_ HvacEvap_Te_Rq : 33|10@0+ (0.125,-50) [-50|77.875] "Degrees C"  SOBDMC_HPCM_FD1,ECM,ECM_Diesel,ECM_HEVDSL,PCM,PCM_HEV
 SG_ HvacEvap_Te_Actl : 17|10@0+ (0.125,-50) [-50|77.75] "Degrees C"  SOBDMC_HPCM_FD1,ECM,ECM_Diesel,ECM_HEVDSL,PCM,PCM_HEV
 SG_ HvacAirCond_B_Rq : 7|1@0+ (1,0) [0|1] "SED"  ECM,ECM_Diesel,ECM_HEVDSL,PCM,PCM_HEV
 SG_ HvacEvap_Te_Offst : 1|10@0+ (0.125,-50) [-50|77.875] "Degrees C"  ECM,ECM_Diesel,ECM_HEVDSL,PCM,PCM_HEV
 SG_ ClimtPw_B_Rq : 5|1@0+ (1,0) [0|1] "SED"  ECM,ECM_Diesel,ECM_HEVDSL,PCM,PCM_HEV
 SG_ WndwFrontHeat_B_Stat : 4|1@0+ (1,0) [0|1] "SED"  GENERIC

BO_ 765 Mc_Send_Signals_2_FD1: 8 GWM
 SG_ BalrSwtch_D_Stat : 57|2@0+ (1,0) [0|3] "SED"  IPMA_ADAS
 SG_ BalrMde_D_Rq : 59|2@0+ (1,0) [0|3] "SED"  IPMA_ADAS
 SG_ RstrnOnPsngr_D_RqMnu : 63|4@0+ (1,0) [0|15] "SED"  GENERIC
 SG_ WaitToStartLamp_D_Falt : 50|2@0+ (1,0) [0|3] "SED"  ECM,ECM_Diesel,ECM_HEVDSL
 SG_ EsaOn_B_Rq : 15|1@0+ (1,0) [0|1] "SED"  PSCM
 SG_ BttOn_B_Rq : 26|1@0+ (1,0) [0|1] "SED"  IPMA_ADAS
 SG_ Btt_L_Actl : 39|7@0+ (0.1,0) [0|12.5] "meter"  IPMA_ADAS
 SG_ RearDiffLck_D_RqArb : 25|2@0+ (1,0) [0|3] "SED"  TCCM
 SG_ AwdMde_D_RqArb : 47|3@0+ (1,0) [0|7] "SED"  TCCM
 SG_ SelDrvMdeTxtReset_B_Rq : 40|1@0+ (1,0) [0|1] "SED"  ABS_ESC
 SG_ AutoTowAllw_D_RqMnu : 52|2@0+ (1,0) [0|3] "SED"  PCM_HEV,ECM,ECM_Diesel,ECM_HEVDSL,PCM
 SG_ DrvInputRequired_B_Rq : 32|1@0+ (1,0) [0|1] "SED"  GENERIC
 SG_ SelDrvMdeDsply_B_Avail : 41|1@0+ (1,0) [0|1] "SED"  ABS_ESC
 SG_ EngExhMdeQuiet_D_Rq : 17|2@0+ (1,0) [0|3] "SED"  GENERIC
 SG_ AirSusp_D_RqDrv : 31|2@0+ (1,0) [0|3] "SED"  VDM,GENERIC
 SG_ Mc_VehUntTrpCoUsrSel_St : 23|1@0+ (1,0) [0|1] "SED"  GENERIC
 SG_ Mc_VehUnitTempUsrSel_St : 22|1@0+ (1,0) [0|1] "SED"  GENERIC
 SG_ Mc_VehDayNightUsrSel_St : 14|3@0+ (1,0) [0|7] "SED"  GENERIC
 SG_ Mc_VehTimeFrmtUsrSel_St : 1|2@0+ (1,0) [0|3] "SED"  GENERIC
 SG_ Mc_VehThemeUsrSel_St : 11|4@0+ (1,0) [0|15] "SED"  GENERIC
 SG_ Mc_VehLangUsrSel_St : 7|6@0+ (1,0) [0|63] "SED"  GENERIC
 SG_ AwdRnge_D_ActlIpc : 29|3@0+ (1,0) [0|7] "SED"  TCM,ABS_ESC,ECM,ECM_Diesel,ECM_HEVDSL,PCM,PCM_HEV,TCCM,TCM_DSL
 SG_ AwdDrvMde_D_Rq : 44|3@0+ (1,0) [0|7] "SED"  TCCM
 SG_ EngExhMdeQuiet_D2_Rq : 55|3@0+ (1,0) [0|7] "SED"  ECM
 SG_ BrkLineLck_D_Rq : 19|2@0+ (1,0) [0|3] "SED"  ABS_ESC
 SG_ EdmSailMde_B_RqDrv : 48|1@0+ (1,0) [0|1] "SED"  ECM,ECM_Diesel,ECM_HEV,ECM_HEVDSL,PCM,PCM_HEV
 SG_ Running_Board_Cmd : 21|2@0+ (1,0) [0|3] "SED"  GENERIC

BO_ 518 DifferentialCtrlData_1_FD1: 8 GWM
 SG_ RearDiffLck_Tq_Actl2 : 7|14@0+ (1,0) [0|16381] "Nm"  TCCM,ABS_ESC,ECM,ECM_HEVDSL,PCM

BO_ 559 ElecHorizon_Data2_FD1: 8 GWM
 SG_ EhData2_No_Actl : 7|64@0+ (1,0) [0|1.84467440737096E+019] "unitless"  IPMA_ADAS,ECM,ECM_Diesel,ECM_HEV,ECM_HEVDSL,PCM,PCM_HEV,HCM

BO_ 558 ElecHorizon_Data1_FD1: 8 GWM
 SG_ EhData1_No_Actl : 7|64@0+ (1,0) [0|1.84467440737096E+019] "unitless"  IPMA_ADAS,ECM,ECM_Diesel,ECM_HEV,ECM_HEVDSL,PCM,PCM_HEV,HCM

BO_ 934 Side_Detect_L_Stat: 8 IPMA_ADAS
 SG_ CtaAlrtLeft2_D_Stat : 30|3@0+ (1,0) [0|7] "SED"  GENERIC
 SG_ CtaBrkLeftMsgTxt_B_Rq : 42|1@0+ (1,0) [0|1] "SED"  GENERIC
 SG_ CtaLeftBrkDecel_B_Rq : 7|1@0+ (1,0) [0|1] "SED"  ABS_ESC
 SG_ CtaLeftBrkEnbl_B_Rq : 31|1@0+ (1,0) [0|1] "SED"  ABS_ESC
 SG_ Side_Detect_L_Illum : 39|8@0+ (1,0) [0|255] "Percent"  GENERIC
 SG_ BttLeft_D_Stat : 45|3@0+ (1,0) [0|7] "SED"  GENERIC
 SG_ BttLeft_D_RqDrv : 47|2@0+ (1,0) [0|3] "SED"  GENERIC
 SG_ CtaSnsLeft_D_Stat : 25|2@0+ (1,0) [0|3] "SED"  GENERIC
 SG_ SodDetctLeft_D_Stat : 23|3@0+ (1,0) [0|7] "SED"  GENERIC
 SG_ CtaLeft_D_Stat : 18|3@0+ (1,0) [0|7] "SED"  GENERIC
 SG_ CtaAlrtLeft_D_Stat : 8|1@0+ (1,0) [0|1] "SED"  GENERIC
 SG_ SodLeft_D_Stat : 15|3@0+ (1,0) [0|7] "SED"  GENERIC
 SG_ SodSnsLeft_D_Stat : 12|2@0+ (1,0) [0|3] "SED"  GENERIC
 SG_ SodAlrtLeft_D_Stat : 10|2@0+ (1,0) [0|3] "SED"  GENERIC
 SG_ SodWarnLeft_Prd_Rq : 6|7@0+ (1,0) [0|127] "millisecond"  GENERIC

BO_ 825 Front_Distance_Req_FD1: 8 GWM
 SG_ WndwFrontHeat_B_Rq : 43|1@0+ (1,0) [0|1] "SED"  GENERIC
 SG_ FdsmTrgRight_B_Actl : 5|1@0+ (1,0) [0|1] "SED"  GENERIC
 SG_ FdsmTrgLeft_B_Actl : 6|1@0+ (1,0) [0|1] "SED"  GENERIC
 SG_ FdsmTrgDist_L_Actl : 1|10@0+ (0.0156,0) [0|15.9588] "meter"  GENERIC
 SG_ FdsmTrgCntr_B_Actl : 7|1@0+ (1,0) [0|1] "SED"  GENERIC
 SG_ LscmbbSrvcRqd_B_Rq : 44|1@0+ (1,0) [0|1] "SED"  GENERIC
 SG_ LscmbbPostEvnt_B_Dsply : 45|1@0+ (1,0) [0|1] "SED"  GENERIC
 SG_ LscmbbEngTqMn_B_Rq : 47|1@0+ (1,0) [0|1] "SED"  SOBDMC_HPCM_FD1,ABS_ESC,ECM,ECM_Diesel,ECM_HEVDSL,PCM,PCM_HEV
 SG_ LscmbbMsgTxt_D_Rq : 46|1@0+ (1,0) [0|1] "SED"  GENERIC
 SG_ LscmbbDeny_B_Actl : 24|1@0+ (1,0) [0|1] "SED"  ABS_ESC
 SG_ LscmbbBrkPrchg_D_Rq : 26|2@0+ (1,0) [0|3] "SED"  ABS_ESC
 SG_ LscmbbBrkDecel_No_Cs : 39|8@0+ (1,0) [0|255] "Unitless"  ABS_ESC
 SG_ LscmbbBrkDecel_No_Cnt : 30|4@0+ (1,0) [0|15] "Unitless"  ABS_ESC
 SG_ LscmbbBrkDecel_B_Enbl : 31|1@0+ (1,0) [0|1] "SED"  ABS_ESC
 SG_ LscmbbBrkDecel_A_Rq : 23|8@0+ (0.05,-12.75) [-12.75|12.75] "m/s^2"  ABS_ESC
 SG_ LscmbbBlck_B_Actl : 2|1@0+ (1,0) [0|1] "SED"  GENERIC
 SG_ LscmbbBaSens_D_Rq : 4|2@0+ (1,0) [0|3] "SED"  ABS_ESC

BO_ 1072 Cluster_Info1_FD1: 8 GWM
 SG_ PtDrvMde_D_Rq : 61|4@0+ (1,0) [0|15] "SED"  ECM,ECM_Diesel,ECM_HEVDSL,PCM,PCM_HEV
 SG_ DrvSlipCtlMde_D_Rq : 33|2@0+ (1,0) [0|3] "SED"  ABS_ESC
 SG_ EngIdlShutDown_B_RqDrv : 3|1@0+ (1,0) [0|1] "SED"  ECM,ECM_Diesel,ECM_HEV,ECM_HEVDSL,PCM,PCM_HEV
 SG_ DrvPerfMde_D_Rq : 49|2@0+ (1,0) [0|3] "SED"  PCM,PCM_HEV,ECM_HEV
 SG_ HsaMde_D_Rq : 54|2@0+ (1,0) [0|3] "SED"  ABS_ESC
 SG_ StopStrtDrvMde_D_RqMnu : 47|2@0+ (1,0) [0|3] "SED"  ECM,ECM_Diesel,ECM_HEVDSL,PCM,PCM_HEV
 SG_ NtrlTowMdeEnbl_B_RqDrv : 1|1@0+ (1,0) [0|1] "SED"  TCM,SOBDMC_HPCM_FD1,TCCM,TCM_DSL,PCM_HEV,PCM,ECM_HEV,AWD_DLCM
 SG_ LscmbbStat_B_Actl : 2|1@0+ (1,0) [0|1] "SED"  GENERIC
 SG_ BulbChkActv_B_Stat : 55|1@0+ (1,0) [0|1] "SED"  GENERIC
 SG_ ParkDetect_Stat : 52|1@0+ (1,0) [0|1] "SED"  TCM_DSL,TCM,PCM_HEV,PCM
 SG_ ReducedGuard_D_Rq : 51|2@0+ (1,0) [0|3] "SED"  GENERIC
 SG_ FrostWarn_D_Stat : 45|2@0+ (1,0) [0|3] "SED"  ECM,ECM_Diesel,ECM_HEV,ECM_HEVDSL,PCM,PCM_HEV
 SG_ TrlrBrkMde_D_Rq : 57|1@0+ (1,0) [0|1] "SED"  GENERIC
 SG_ TRLR_SWAY_CONFIG_CMD : 56|1@0+ (1,0) [0|1] "SED"  ABS_ESC
 SG_ TRAILER_BRAKE_CONFIG : 37|1@0+ (1,0) [0|1] "SED"  GENERIC
 SG_ Power_Liftgate_Mode_Cmd : 39|1@0+ (1,0) [0|1] "SED"  GENERIC
 SG_ AccEnbl_B_RqDrv : 35|1@0+ (1,0) [0|1] "SED"  IPMA_ADAS
 SG_ OdometerMasterValue : 15|24@0+ (1,0) [0|16777214] "km"  CMR_DSMC,TCM,SOBDMC_HPCM_FD1,ABS_ESC,ECM,ECM_Diesel,ECM_HEV,ECM_HEVDSL,IPMA_ADAS,PCM,PCM_HEV,PSCM,TCM_DSL,VDM,TCCM,AWD_DLCM
 SG_ EngOilLife_B_RqReset : 43|1@0+ (1,0) [0|1] "SED"  ECM,ECM_Diesel,ECM_HEV,ECM_HEVDSL,PCM,PCM_HEV
 SG_ MetricActvTe_B_Actl : 38|1@0+ (1,0) [0|1] "SED"  GENERIC
 SG_ AccDeny_B_RqIpc : 7|1@0+ (1,0) [0|1] "SED"  IPMA_ADAS
 SG_ ePRNDL_MODE : 0|1@0+ (1,0) [0|1] "SED"  SOBDMC_HPCM_FD1,TCM,ECM,ECM_Diesel,ECM_HEV,ECM_HEVDSL,PCM,PCM_HEV,TCM_DSL
 SG_ PrkLckCtlEnbl_D_RqIpc : 63|2@0+ (1,0) [0|3] "SED"  GENERIC
 SG_ DrvSlipCtlMde_B_Rq2 : 34|1@0+ (1,0) [0|1] "SED"  ABS_ESC
 SG_ MetricActv_B_Actl : 6|1@0+ (1,0) [0|1] "SED"  ECM,ECM_Diesel,ECM_HEV,ECM_HEVDSL,IPMA_ADAS,PCM,PCM_HEV
 SG_ KeyTypeChngMykey_D_Rq : 41|2@0+ (1,0) [0|3] "SED"  GENERIC
 SG_ ManRgen_D_Rq : 5|2@0+ (1,0) [0|3] "SED"  ECM,ECM_Diesel,ECM_HEVDSL
 SG_ Fda_B_Stat : 36|1@0+ (1,0) [0|1] "SED"  GENERIC
 SG_ HaDsplyCpblty_B_Stat : 42|1@0+ (1,0) [0|1] "SED"  IPMA_ADAS

BO_ 909 Body_Info_6_FD1: 8 GWM
 SG_ IgnPsswrdDsply_B_Rq : 57|1@0+ (1,0) [0|1] "SED"  GENERIC
 SG_ ElPwPoint_D_Rq : 59|2@0+ (1,0) [0|3] "SED"  GENERIC
 SG_ PoliceIdlMde_D_Stat : 55|4@0+ (1,0) [0|15] "SED"  GENERIC
 SG_ DrLatchMsgTxt_D_Rq : 43|3@0+ (1,0) [0|7] "SED"  GENERIC
 SG_ WiprFront_D_Stat2 : 63|4@0+ (1,0) [0|15] "SED"  ECM_HEVDSL,PCM,PCM_HEV,ECM,AWD_DLCM
 SG_ SecurityMsgTxt_D_Rq : 47|2@0+ (1,0) [0|3] "SED"  GENERIC
 SG_ PrmtrAlrmEvnt_D_Stat : 35|4@0+ (1,0) [0|15] "SED"  GENERIC
 SG_ TurnLghtSwtch_D_Stat2 : 49|2@0+ (1,0) [0|3] "SED"  PSCM
 SG_ HeadLghtHiPrmsn_D_Stat : 51|2@0+ (1,0) [0|3] "SED"  HCM,IPMA_ADAS
 SG_ SteWhlLckMsgTxt_D_Rq : 25|2@0+ (1,0) [0|3] "SED"  GENERIC
 SG_ immoMsgTxt_D_Rq : 39|4@0+ (1,0) [0|15] "SED"  GENERIC
 SG_ PrsnlDevcChrgEnbl_B_Rq : 40|1@0+ (1,0) [0|1] "SED"  GENERIC
 SG_ TracKeyMde_D_Stat : 45|2@0+ (1,0) [0|3] "SED"  PCM,PCM_HEV
 SG_ PEBackupSlot_Stats : 27|2@0+ (1,0) [0|3] "SED"  GENERIC
 SG_ KeyMykeyTot_No_Cnt : 3|4@0+ (1,0) [0|15] "Counts"  GENERIC
 SG_ Keycode_Status : 15|20@0+ (1,0) [0|1048575] "unitless"  GENERIC
 SG_ KeyAdmnTot_No_Cnt : 7|4@0+ (1,0) [0|15] "Counts"  GENERIC
 SG_ HazrdLght_B_Stat : 56|1@0+ (1,0) [0|1] "SED"  GENERIC

BO_ 963 BCM_Lamp_Stat_FD1: 8 GWM
 SG_ Illuminated_Entry_Stat : 63|2@0+ (1,0) [0|3] "SED"  GENERIC
 SG_ Dr_Courtesy_Light_Stat : 49|2@0+ (1,0) [0|3] "SED"  GENERIC
 SG_ Courtesy_Delay_Status : 51|2@0+ (1,0) [0|3] "SED"  GENERIC
 SG_ ImpactEvntFdbck_D_Stat : 53|2@0+ (1,0) [0|3] "SED"  CMR_DSMC
 SG_ WrlssAcsyChrgInhbt_B_Rq : 40|1@0+ (1,0) [0|1] "SED"  GENERIC
 SG_ PudLampPsngr_D_Rq : 57|2@0+ (1,0) [0|3] "SED"  GENERIC
 SG_ HeadLampLoOut_B_Stat : 32|1@0+ (1,0) [0|1] "SED"  GENERIC
 SG_ CrnrLghtRight_Pc_Rq : 47|7@0+ (1,0) [0|100] "percent"  HCM,GENERIC
 SG_ CrnrLghtLeft_Pc_Rq : 39|7@0+ (1,0) [0|100] "percent"  HCM,GENERIC
 SG_ HeadLghtHiFdbck_D_Stat : 55|2@0+ (1,0) [0|3] "SED"  GENERIC
 SG_ PudLampDrv_D_Rq : 59|2@0+ (1,0) [0|3] "SED"  GENERIC
 SG_ TrnNotInPrkChime_B_Rq : 24|1@0+ (1,0) [0|1] "SED"  GENERIC
 SG_ PrkLightChime_B_Rq : 25|1@0+ (1,0) [0|1] "SED"  GENERIC
 SG_ KeyInIgnWarn_B_Cmd : 27|1@0+ (1,0) [0|1] "SED"  GENERIC
 SG_ HomeSafeLtChime_B_Rq : 28|1@0+ (1,0) [0|1] "SED"  GENERIC
 SG_ StopLghtOn_B_Stat : 8|1@0+ (1,0) [0|1] "SED"  HCM,ABS_ESC
 SG_ RvrseLghtOn_B_Stat : 9|1@0+ (1,0) [0|1] "SED"  GENERIC
 SG_ PrkLght_D_Stat : 13|2@0+ (1,0) [0|3] "SED"  GENERIC
 SG_ HeadLghtSwtch_D_Stat : 15|2@0+ (1,0) [0|3] "SED"  HCM,IPMA_ADAS
 SG_ HeadLampLoFrOn_B_Stat : 2|1@0+ (1,0) [0|1] "SED"  HCM,IPMA_ADAS
 SG_ HeadLampLoFlOn_B_Stat : 3|1@0+ (1,0) [0|1] "SED"  HCM,IPMA_ADAS
 SG_ HeadLampLoActv_B_Stat : 4|1@0+ (1,0) [0|1] "SED"  HCM,IPMA_ADAS,PCM_HEV,PCM,ECM_HEVDSL,ECM_Diesel,ECM
 SG_ Headlamp_On_Wrning_Cmd : 29|1@0+ (1,0) [0|1] "SED"  GENERIC
 SG_ Park_Brake_Chime_Rqst : 26|1@0+ (1,0) [0|1] "SED"  GENERIC
 SG_ HeadLghtHiOn_B_Stat : 1|1@0+ (1,0) [0|1] "SED"  HCM,ECM,ECM_Diesel,ECM_HEVDSL,IPMA_ADAS,PCM,PCM_HEV
 SG_ BrkWarnInd_B_Rq : 20|1@0+ (1,0) [0|1] "SED"  GENERIC
 SG_ Brk_Fluid_Lvl_Low : 31|2@0+ (1,0) [0|3] "SED"  GENERIC
 SG_ ReducedGuard_D_Stat : 19|2@0+ (1,0) [0|3] "SED"  GENERIC
 SG_ Perimeter_Alarm_Status : 17|2@0+ (1,0) [0|3] "SED"  ABS_ESC
 SG_ Courtesy_BSave_Stat : 7|2@0+ (1,0) [0|3] "SED"  GENERIC
 SG_ DrTgateLck_D_Stat : 61|2@0+ (1,0) [0|3] "SED"  GENERIC
 SG_ WndwGlbl_D_Cmd : 23|3@0+ (1,0) [0|7] "SED"  GENERIC
 SG_ PudLamp_D_Rq : 11|2@0+ (1,0) [0|3] "SED"  GENERIC
 SG_ PerimeterAlarmChimeRq : 0|1@0+ (1,0) [0|1] "SED"  GENERIC
 SG_ DayRnngLampOn_B_Stat : 5|1@0+ (1,0) [0|1] "SED"  HCM

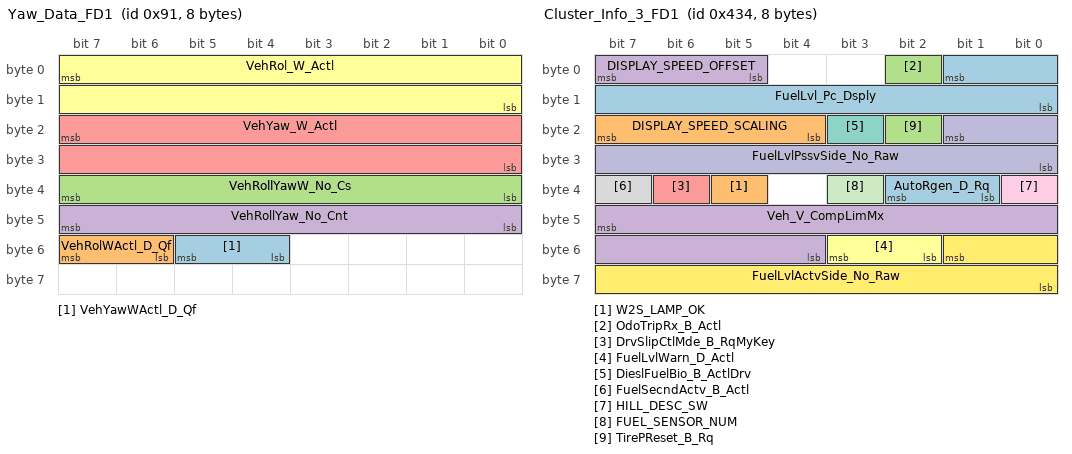
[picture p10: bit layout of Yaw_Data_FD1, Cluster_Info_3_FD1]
BO_ 145 Yaw_Data_FD1: 8 GWM
 SG_ VehYawWActl_D_Qf : 53|2@0+ (1,0) [0|3] "SED"  VDM,HCM,IPMA_ADAS,ABS_ESC
 SG_ VehRolWActl_D_Qf : 55|2@0+ (1,0) [0|3] "SED"  VDM,ABS_ESC,IPMA_ADAS
 SG_ VehRollYawW_No_Cs : 39|8@0+ (1,0) [0|255] "Unitless"  ABS_ESC,IPMA_ADAS
 SG_ VehRollYaw_No_Cnt : 47|8@0+ (1,0) [0|255] "Unitless"  VDM,ABS_ESC,IPMA_ADAS
 SG_ VehYaw_W_Actl : 23|16@0+ (0.0002,-6.5) [-6.5|6.6066] "rad/s"  VDM,HCM,ABS_ESC,PSCM,IPMA_ADAS
 SG_ VehRol_W_Actl : 7|16@0+ (0.0002,-6.5) [-6.5|6.6066] "rad/s"  VDM,ECM,ECM_Diesel,ECM_HEVDSL,PCM,PCM_HEV,ABS_ESC,IPMA_ADAS,PSCM

BO_ 76 RCMStatusMessage2_FD1: 8 GWM
 SG_ RstrnPsngrOn_D_Stat : 39|4@0+ (1,0) [0|15] "SED"  GENERIC
 SG_ PsngrFmidDetct_D_Actl : 26|2@0+ (1,0) [0|3] "SED"  GENERIC
 SG_ FirstRowBuckleMid : 28|2@0+ (1,0) [0|3] "SED"  GENERIC,IPMA_ADAS
 SG_ ThirdRowBucklePsngr : 17|2@0+ (1,0) [0|3] "SED"  GENERIC
 SG_ ThirdRowBuckleMid : 19|2@0+ (1,0) [0|3] "SED"  GENERIC
 SG_ ThirdRowBuckleDriver : 21|2@0+ (1,0) [0|3] "SED"  GENERIC
 SG_ SecondRowBucklePsngr : 23|2@0+ (1,0) [0|3] "SED"  GENERIC
 SG_ SecondRowBuckleMid : 9|2@0+ (1,0) [0|3] "SED"  GENERIC
 SG_ SecondRowBuckleDriver : 11|2@0+ (1,0) [0|3] "SED"  GENERIC
 SG_ FirstRowBuckleDriver : 15|2@0+ (1,0) [0|3] "SED"  TCM,SOBDMC_HPCM_FD1,ABS_ESC,IPMA_ADAS,ECM,ECM_Diesel,ECM_HEV,ECM_HEVDSL,PCM,PCM_HEV,TCM_DSL,CMR_DSMC
 SG_ RILReq : 7|2@0+ (1,0) [0|3] "SED"  GENERIC
 SG_ FirstRowBucklePsngr : 13|2@0+ (1,0) [0|3] "SED"  GENERIC,IPMA_ADAS
 SG_ RstrnImpactEvntStatus : 3|3@0+ (1,0) [0|7] "SED"  TCM,SOBDMC_HPCM_FD1,ABS_ESC,IPMA_ADAS,ECM,ECM_Diesel,ECM_HEV,ECM_HEVDSL,PCM,PCM_HEV,TCM_DSL,CMR_DSMC
 SG_ PsngrFrntDetct_D_Actl : 5|2@0+ (1,0) [0|3] "SED"  GENERIC
 SG_ EDRTriggerEvntSync : 29|1@0+ (1,0) [0|1] "SED"  IPMA_ADAS
 SG_ PassRstrnInd_Req : 31|2@0+ (1,0) [0|3] "SED"  GENERIC
 SG_ FirstRowBuckle_No_Cs : 47|8@0+ (1,0) [0|255] "unitless"  IPMA_ADAS,ABS_ESC
 SG_ RCMStatusMsg2_No_Cnt : 35|4@0+ (1,0) [0|15] "Unitless"  ABS_ESC,IPMA_ADAS

BO_ 65 Global_PATS_Cntrl_Info_FD1: 8 GWM
 SG_ immoControlData_T1 : 15|40@0+ (1,0) [0|1099511627775] "Encrypted"  SOBDMC_HPCM_FD1,ECM,ECM_Diesel,ECM_HEVDSL,PCM,PCM_HEV
 SG_ immoControlCmd_T1 : 7|3@0+ (1,0) [0|7] "SED"  SOBDMC_HPCM_FD1,ECM,ECM_Diesel,ECM_HEVDSL,PCM,PCM_HEV,ECM_HEV

BO_ 1076 Cluster_Info_3_FD1: 8 GWM
 SG_ AutoRgen_D_Rq : 34|2@0+ (1,0) [0|3] "SED"  ECM_Diesel,ECM_HEVDSL,ECM
 SG_ W2S_LAMP_OK : 37|1@0+ (1,0) [0|1] "SED"  ECM,ECM_Diesel,ECM_HEVDSL
 SG_ OdoTripRx_B_Actl : 2|1@0+ (1,0) [0|1] "SED"  ECM,ECM_Diesel,ECM_HEV,ECM_HEVDSL,PCM,PCM_HEV
 SG_ Veh_V_CompLimMx : 47|12@0+ (0.1,0) [0|409.5] "km/h"  ECM,ECM_Diesel,ECM_HEV,ECM_HEVDSL,PCM,PCM_HEV
 SG_ DrvSlipCtlMde_B_RqMyKey : 38|1@0+ (1,0) [0|1] "SED"  ABS_ESC
 SG_ FuelLvlWarn_D_Actl : 51|2@0+ (1,0) [0|3] "SED"  PCM,PCM_HEV
 SG_ DieslFuelBio_B_ActlDrv : 19|1@0+ (1,0) [0|1] "SED"  ECM,ECM_Diesel,ECM_HEVDSL
 SG_ FuelSecndActv_B_Actl : 39|1@0+ (1,0) [0|1] "SED"  ECM,ECM_Diesel,ECM_HEVDSL,PCM,PCM_HEV
 SG_ HILL_DESC_SW : 32|1@0+ (1,0) [0|1] "SED"  ABS_ESC
 SG_ FuelLvlPssvSide_No_Raw : 17|10@0+ (1,0) [0|1023] "Unitless"  ECM,ECM_Diesel,ECM_HEV,ECM_HEVDSL,PCM,PCM_HEV
 SG_ FUEL_SENSOR_NUM : 35|1@0+ (1,0) [0|1] "SED"  ECM,ECM_Diesel,ECM_HEV,ECM_HEVDSL,PCM,PCM_HEV
 SG_ FuelLvlActvSide_No_Raw : 49|10@0+ (1,0) [0|1023] "Unitless"  ECM,ECM_Diesel,ECM_HEV,ECM_HEVDSL,PCM,PCM_HEV
 SG_ FuelLvl_Pc_Dsply : 1|10@0+ (0.108696,-5.217408) [-5.217408|105.9786] "Percent"  VDM,ECM,ECM_Diesel,ECM_HEVDSL
 SG_ DISPLAY_SPEED_SCALING : 23|4@0+ (0.5,100) [100|107.5] "%"  IPMA_ADAS,ECM,ECM_Diesel,ECM_HEV,ECM_HEVDSL,PCM,PCM_HEV
 SG_ TirePReset_B_Rq : 18|1@0+ (1,0) [0|1] "SED"  GENERIC
 SG_ DISPLAY_SPEED_OFFSET : 7|3@0+ (0.5,0) [0|3.5] "kph"  IPMA_ADAS,ECM,ECM_Diesel,ECM_HEV,ECM_HEVDSL,PCM,PCM_HEV

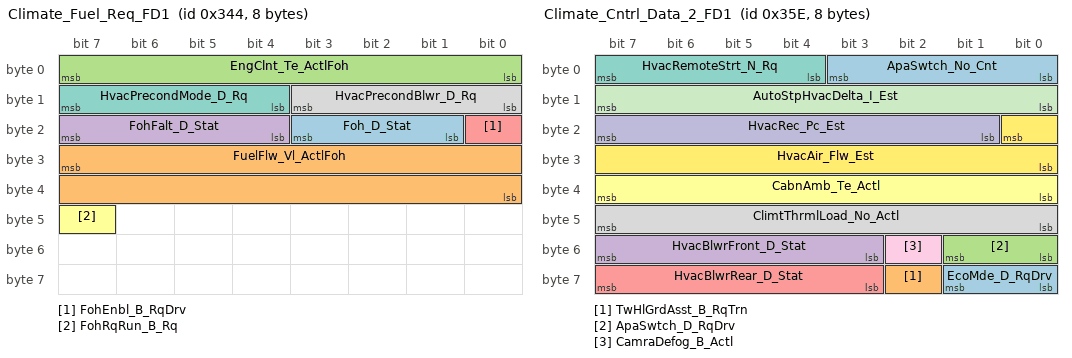
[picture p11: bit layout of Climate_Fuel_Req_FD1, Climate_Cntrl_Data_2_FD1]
BO_ 836 Climate_Fuel_Req_FD1: 8 GWM
 SG_ Foh_D_Stat : 19|3@0+ (1,0) [0|7] "SED"  ECM_Diesel,ECM_HEVDSL,PCM,PCM_HEV,ECM
 SG_ FuelFlw_Vl_ActlFoh : 31|16@0+ (25,0) [0|1638375] "microlitre"  ECM_Diesel,ECM_HEVDSL,PCM,PCM_HEV,ECM
 SG_ EngClnt_Te_ActlFoh : 7|8@0+ (1,-50) [-50|204] "degC"  ECM_Diesel,ECM_HEVDSL,PCM,PCM_HEV,ECM
 SG_ FohFalt_D_Stat : 23|4@0+ (1,0) [0|15] "SED"  ECM_Diesel,ECM_HEVDSL,PCM,PCM_HEV,ECM
 SG_ FohEnbl_B_RqDrv : 16|1@0+ (1,0) [0|1] "SED"  ECM_Diesel,ECM_HEVDSL,PCM,PCM_HEV,ECM
 SG_ FohRqRun_B_Rq : 47|1@0+ (1,0) [0|1] "SED"  ECM_Diesel,ECM_HEVDSL,PCM,PCM_HEV,ECM
 SG_ HvacPrecondMode_D_Rq : 15|4@0+ (1,0) [0|15] "SED"  GENERIC
 SG_ HvacPrecondBlwr_D_Rq : 11|4@0+ (1,0) [0|15] "SED"  GENERIC

BO_ 862 Climate_Cntrl_Data_2_FD1: 8 GWM
 SG_ EcoMde_D_RqDrv : 57|2@0+ (1,0) [0|3] "SED"  SOBDMC_HPCM_FD1,GENERIC
 SG_ TwHlGrdAsst_B_RqTrn : 58|1@0+ (1,0) [0|1] "SED"  ECM_HEV,AWD_DLCM
 SG_ ApaSwtch_D_RqDrv : 49|2@0+ (1,0) [0|3] "SED"  IPMA_ADAS
 SG_ HvacBlwrFront_D_Stat : 55|5@0+ (1,0) [0|31] "SED"  ECM_Diesel,ECM_HEV,ECM_HEVDSL,PCM,PCM_HEV,ECM
 SG_ HvacBlwrRear_D_Stat : 63|5@0+ (1,0) [0|31] "SED"  SOBDMC_HPCM_FD1,ECM_Diesel,ECM_HEV,ECM_HEVDSL,PCM,PCM_HEV,ECM
 SG_ CabnAmb_Te_Actl : 39|8@0+ (0.5,-57) [-57|70] "degreesC"  SOBDMC_HPCM_FD1,PCM,PCM_HEV
 SG_ HvacRemoteStrt_N_Rq : 7|4@0+ (100,450) [450|1950] "RPM"  ECM_Diesel,ECM_HEV,ECM_HEVDSL,PCM,PCM_HEV,ECM
 SG_ ClimtThrmlLoad_No_Actl : 47|8@0+ (1,0) [0|254] "unitless"  SOBDMC_HPCM_FD1,ECM_Diesel,ECM_HEV,ECM_HEVDSL,PCM_HEV,ECM
 SG_ CamraDefog_B_Actl : 50|1@0+ (1,0) [0|1] "SED"  GENERIC
 SG_ HvacRec_Pc_Est : 23|7@0+ (1,0) [0|127] "Percent"  SOBDMC_HPCM_FD1,PCM_HEV
 SG_ AutoStpHvacDelta_I_Est : 15|8@0+ (1,-192) [-192|62] "ampere"  GENERIC
 SG_ HvacAir_Flw_Est : 16|9@0+ (0.5,0) [0|255.5] "liter/second"  SOBDMC_HPCM_FD1,GENERIC,PCM_HEV
 SG_ ApaSwtch_No_Cnt : 3|4@0+ (1,0) [0|15] "Unitless"  GENERIC

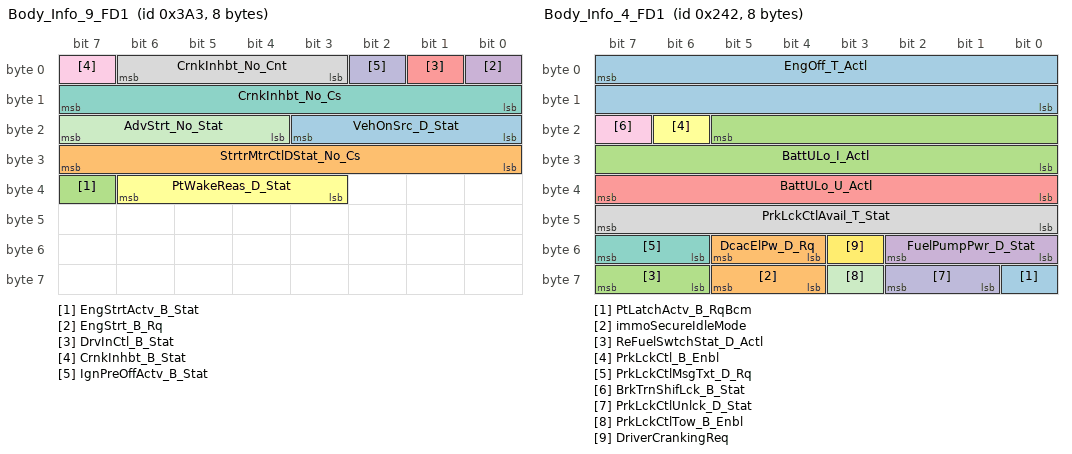
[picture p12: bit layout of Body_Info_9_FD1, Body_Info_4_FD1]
BO_ 931 Body_Info_9_FD1: 8 GWM
 SG_ VehOnSrc_D_Stat : 19|4@0+ (1,0) [0|15] "SED"  ECM,ECM_Diesel,ECM_HEV,ECM_HEVDSL,PCM,AWD_DLCM,TCM,TCM_DSL,SOBDMC_HPCM_FD1,ABS_ESC,PCM_HEV
 SG_ StrtrMtrCtlDStat_No_Cs : 31|8@0+ (1,0) [0|255] "unitless"  ECM,ECM_Diesel,ECM_HEV,ECM_HEVDSL,PCM,SOBDMC_HPCM_FD1,PCM_HEV
 SG_ EngStrtActv_B_Stat : 39|1@0+ (1,0) [0|1] "SED"  ECM,ECM_Diesel,ECM_HEV,ECM_HEVDSL,PCM,SOBDMC_HPCM_FD1,PCM_HEV
 SG_ EngStrt_B_Rq : 0|1@0+ (1,0) [0|1] "SED"  ECM,ECM_Diesel,ECM_HEV,ECM_HEVDSL,PCM,SOBDMC_HPCM_FD1,PCM_HEV
 SG_ DrvInCtl_B_Stat : 1|1@0+ (1,0) [0|1] "SED"  ECM,ECM_Diesel,ECM_HEV,ECM_HEVDSL,PCM,SOBDMC_HPCM_FD1,PCM_HEV
 SG_ PtWakeReas_D_Stat : 38|4@0+ (1,0) [0|15] "SED"  ECM_HEV,PCM_HEV
 SG_ CrnkInhbt_No_Cs : 15|8@0+ (1,0) [0|255] "Unitless"  ECM_Diesel,ECM_HEV,ECM_HEVDSL,PCM,PCM_HEV,ECM
 SG_ CrnkInhbt_No_Cnt : 6|4@0+ (1,0) [0|15] "Unitless"  SOBDMC_HPCM_FD1,ECM_Diesel,ECM_HEV,ECM_HEVDSL,PCM,PCM_HEV,ECM
 SG_ CrnkInhbt_B_Stat : 7|1@0+ (1,0) [0|1] "SED"  ECM_Diesel,ECM_HEV,ECM_HEVDSL,PCM,PCM_HEV,ECM,AWD_DLCM,TCM,TCM_DSL,SOBDMC_HPCM_FD1
 SG_ IgnPreOffActv_B_Stat : 2|1@0+ (1,0) [0|1] "SED"  TCM,PCM,PCM_HEV,TCM_DSL
 SG_ AdvStrt_No_Stat : 23|4@0+ (1,0) [0|15] "unitless"  SOBDMC_HPCM_FD1,ECM,ECM_Diesel,ECM_HEV,ECM_HEVDSL,PCM,PCM_HEV

BO_ 578 Body_Info_4_FD1: 8 GWM
 SG_ PtLatchActv_B_RqBcm : 56|1@0+ (1,0) [0|1] "SED"  TCM,SOBDMC_HPCM_FD1,ECM_Diesel,ECM_HEV,ECM_HEVDSL,PCM,PCM_HEV,TCM_DSL,ECM
 SG_ immoSecureIdleMode : 61|2@0+ (1,0) [0|3] "SED"  SOBDMC_HPCM_FD1,ECM_Diesel,ECM_HEVDSL,PCM,PCM_HEV,ECM,ECM_HEV
 SG_ ReFuelSwtchStat_D_Actl : 63|2@0+ (1,0) [0|3] "SED"  ECM_HEV
 SG_ FuelPumpPwr_D_Stat : 50|3@0+ (1,0) [0|7] "SED"  ECM_Diesel,ECM_HEV,ECM_HEVDSL,PCM,PCM_HEV,ECM
 SG_ BattULo_U_Actl : 39|8@0+ (0.0625,0) [0|15.875] "volt"  CMR_DSMC,TCM,SOBDMC_HPCM_FD1,CHCM,ABS_ESC,IPMA_ADAS,PSCM,ECM_Diesel,ECM_HEV,ECM_HEVDSL,PCM,PCM_HEV,TCM_DSL,ECM
 SG_ PrkLckCtl_B_Enbl : 22|1@0+ (1,0) [0|1] "SED"  TCM,ECM_Diesel,ECM_HEV,ECM_HEVDSL,PCM,PCM_HEV,TCM_DSL,ECM
 SG_ PrkLckCtlMsgTxt_D_Rq : 55|2@0+ (1,0) [0|3] "SED"  TCM,SOBDMC_HPCM_FD1,ECM_HEV,PCM,PCM_HEV,TCM_DSL
 SG_ PrkLckCtlAvail_T_Stat : 47|8@0+ (1,0) [0|255] "second"  GENERIC
 SG_ BrkTrnShifLck_B_Stat : 23|1@0+ (1,0) [0|1] "SED"  TCM,SOBDMC_HPCM_FD1,ECM_HEV,PCM,PCM_HEV,TCM_DSL
 SG_ PrkLckCtlUnlck_D_Stat : 58|2@0+ (1,0) [0|3] "SED"  GENERIC
 SG_ PrkLckCtlTow_B_Enbl : 59|1@0+ (1,0) [0|1] "SED"  GENERIC
 SG_ DriverCrankingReq : 51|1@0+ (1,0) [0|1] "SED"  ECM_Diesel,ECM_HEV,ECM_HEVDSL,PCM,PCM_HEV,ECM
 SG_ EngOff_T_Actl : 7|16@0+ (1,0) [0|65534] "second^0.5"  CHCM,TCM,ABS_ESC,IPMA_ADAS,TCCM,ECM_Diesel,ECM_HEV,ECM_HEVDSL,PCM,PCM_HEV,TCM_DSL,ECM,AWD_DLCM
 SG_ DcacElPw_D_Rq : 53|2@0+ (1,0) [0|3] "SED"  ECM_Diesel,ECM_HEVDSL,PCM,PCM_HEV,ECM
 SG_ BattULo_I_Actl : 21|14@0+ (0.0625,-512) [-512|511.875] "ampere"  SOBDMC_HPCM_FD1,ECM_Diesel,ECM_HEV,ECM_HEVDSL,PCM,PCM_HEV,ECM

BO_ 947 BodyInfo_3_FD1: 8 GWM
 SG_ ValetMode_D_Mem : 16|1@0+ (1,0) [0|1] "SED"  GENERIC
 SG_ DimmingLvlEvnt_No_Actl : 18|2@0+ (1,0) [0|3] "unitless"  GENERIC
 SG_ DrStatDrvErrCnt_B_Stat : 19|1@0+ (1,0) [0|1] "SED"  ECM_Diesel,ECM_HEV,ECM_HEVDSL,PCM,PCM_HEV,ECM
 SG_ TurnLghtRight_D_Rq : 63|2@0+ (1,0) [0|3] "SED"  HCM,IPMA_ADAS,CMR_DSMC
 SG_ TurnLghtRightOn_B_Stat : 35|1@0+ (1,0) [0|1] "SED"  GENERIC
 SG_ TurnLghtLeftOn_B_Stat : 54|1@0+ (1,0) [0|1] "SED"  GENERIC
 SG_ FogLghtRearOn_B_Stat : 1|1@0+ (1,0) [0|1] "SED"  HCM,IPMA_ADAS
 SG_ Backlit_LED_Status : 23|4@0+ (1,0) [0|15] "SED"  GENERIC
 SG_ TurnLghtLeft_D_Rq : 9|2@0+ (1,0) [0|3] "SED"  HCM,IPMA_ADAS,CMR_DSMC
 SG_ FogLghtFrontOn_B_Stat : 56|1@0+ (1,0) [0|1] "SED"  HCM,IPMA_ADAS
 SG_ IgnKeyType_D_Actl : 39|4@0+ (1,0) [0|15] "SED"  ABS_ESC,ECM,ECM_Diesel,ECM_HEV,ECM_HEVDSL,IPMA_ADAS,PCM,PCM_HEV
 SG_ Parklamp_Status : 3|2@0+ (1,0) [0|3] "SED"  HCM,IPMA_ADAS,SIMA_DLCS
 SG_ Litval : 47|8@0+ (1,0) [0|253] "SED"  HCM,IPMA_ADAS,SIMA_DLCS
 SG_ Key_In_Ignition_Stat : 11|1@0+ (1,0) [0|1] "SED"  ABS_ESC
 SG_ Ignition_Status : 7|4@0+ (1,0) [0|15] "SED"  TCM,SOBDMC_HPCM_FD1,HCM,ABS_ESC,ECM_Diesel,ECM_HEV,ECM_HEVDSL,IPMA_ADAS,PCM,PCM_HEV,PSCM,TCCM,TCM_DSL,ECM,VDM,CMR_DSMC,CHCM,BCMD_IPDB,SIMA_DLCS,AWD_DLCM
 SG_ Dimming_Lvl : 31|8@0+ (1,0) [0|253] "SED"  IPMA_ADAS,SIMA_DLCS
 SG_ Day_Night_Status : 15|2@0+ (1,0) [0|3] "SED"  ECM_Diesel,ECM_HEVDSL,IPMA_ADAS,PCM,PCM_HEV,ECM,CMR_DSMC
 SG_ Remote_Start_Status : 13|2@0+ (1,0) [0|3] "SED"  IPMA_ADAS,CMR_DSMC,ECM_HEV,BCMD_IPDB,TCM,TCM_DSL
 SG_ DrStatTgate_B_Actl : 0|1@0+ (1,0) [0|1] "SED"  ABS_ESC,IPMA_ADAS,VDM
 SG_ DrStatRr_B_Actl : 49|1@0+ (1,0) [0|1] "SED"  ABS_ESC,IPMA_ADAS,VDM
 SG_ DrStatRl_B_Actl : 48|1@0+ (1,0) [0|1] "SED"  ABS_ESC,IPMA_ADAS,VDM
 SG_ DrStatPsngr_B_Actl : 60|1@0+ (1,0) [0|1] "SED"  ABS_ESC,IPMA_ADAS,VDM,CMR_DSMC
 SG_ DrStatInnrTgate_B_Actl : 58|1@0+ (1,0) [0|1] "SED"  ABS_ESC,IPMA_ADAS,VDM
 SG_ DrStatHood_B_Actl : 59|1@0+ (1,0) [0|1] "SED"  ABS_ESC
 SG_ DrStatDrv_B_Actl : 61|1@0+ (1,0) [0|1] "SED"  TCM,ABS_ESC,ECM_Diesel,ECM_HEV,ECM_HEVDSL,IPMA_ADAS,PCM,PCM_HEV,TCCM,TCM_DSL,ECM,VDM,CMR_DSMC
 SG_ PrkBrkActv_B_Actl : 55|1@0+ (1,0) [0|1] "SED"  TCM,SOBDMC_HPCM_FD1,ABS_ESC,ECM_Diesel,ECM_HEV,ECM_HEVDSL,IPMA_ADAS,PCM,PCM_HEV,PSCM,TCCM,TCM_DSL,ECM,AWD_DLCM
 SG_ LifeCycMde_D_Actl : 53|4@0+ (1,0) [0|15] "SED"  TCM,SOBDMC_HPCM_FD1,HCM,ABS_ESC,ECM_Diesel,ECM_HEV,ECM_HEVDSL,IPMA_ADAS,PCM,PCM_HEV,PSCM,TCM_DSL,ECM,VDM,AWD_DLCM
 SG_ Delay_Accy : 57|1@0+ (1,0) [0|1] "SED"  BCMD_IPDB
 SG_ CrashEvnt_D_Stat : 34|2@0+ (1,0) [0|3] "SED"  GENERIC
 SG_ FuelPmpInhbt_B_Stat : 32|1@0+ (1,0) [0|1] "SED"  GENERIC
 SG_ BodySrvcRqd_B_Rq : 10|1@0+ (1,0) [0|1] "SED"  GENERIC

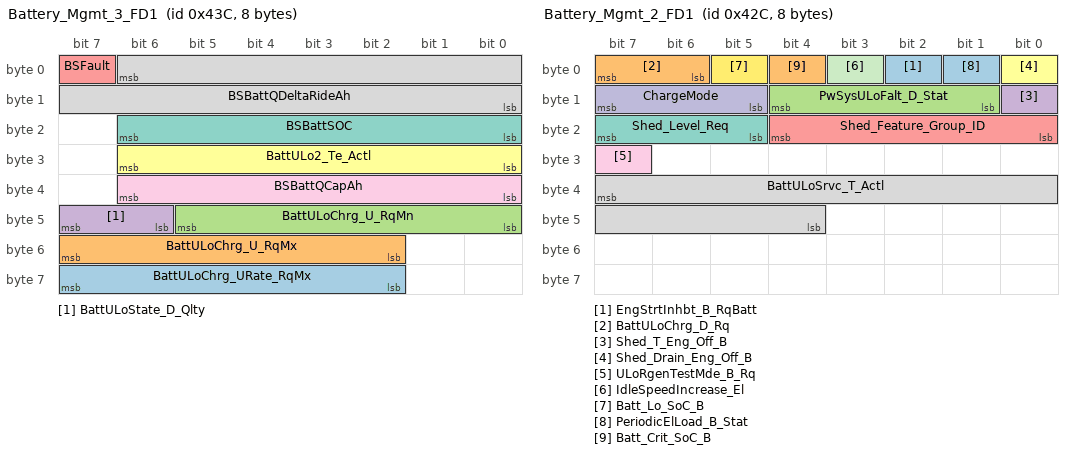
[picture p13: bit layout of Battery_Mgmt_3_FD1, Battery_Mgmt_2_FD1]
BO_ 1084 Battery_Mgmt_3_FD1: 8 GWM
 SG_ BattULoChrg_URate_RqMx : 63|6@0+ (0.1,0) [0|6.3] "volts/second"  ECM_Diesel,ECM_HEV,ECM_HEVDSL,PCM,PCM_HEV,ECM
 SG_ BattULoChrg_U_RqMx : 55|6@0+ (0.1,10.6) [10.6|16.9] "volt"  ECM_Diesel,ECM_HEV,ECM_HEVDSL,PCM,ECM,PCM_HEV
 SG_ BattULoChrg_U_RqMn : 45|6@0+ (0.1,10.6) [10.6|16.9] "volt"  ECM,ECM_Diesel,ECM_HEV,ECM_HEVDSL,PCM,PCM_HEV
 SG_ BattULoState_D_Qlty : 47|2@0+ (1,0) [0|3] "SED"  TCM,TCM_DSL,ECM_HEV,ECM,ECM_Diesel,ECM_HEVDSL,PCM,PCM_HEV
 SG_ BSFault : 7|1@0+ (1,0) [0|1] "SED"  ECM,ECM_Diesel,ECM_HEVDSL,PCM,PCM_HEV,ECM_HEV
 SG_ BattULo2_Te_Actl : 30|7@0+ (1,-40) [-40|86] "degC"  ECM,ECM_Diesel,ECM_HEV,ECM_HEVDSL,PCM,PCM_HEV,SOBDMC_HPCM_FD1
 SG_ BSBattSOC : 22|7@0+ (1,0) [0|127] "%"  TCM,TCM_DSL,ECM,ECM_Diesel,ECM_HEV,ECM_HEVDSL,PCM,PCM_HEV
 SG_ BSBattQDeltaRideAh : 6|15@0+ (0.0078125,-100) [-100|155.9921875] "ampere*hour"  ECM,ECM_Diesel,ECM_HEVDSL,PCM,PCM_HEV
 SG_ BSBattQCapAh : 38|7@0+ (1,0) [0|127] "ampere*hour"  ECM,ECM_Diesel,ECM_HEVDSL,PCM,PCM_HEV

BO_ 1068 Battery_Mgmt_2_FD1: 8 GWM
 SG_ EngStrtInhbt_B_RqBatt : 2|1@0+ (1,0) [0|1] "SED"  ECM_Diesel,ECM_HEVDSL,PCM,PCM_HEV,ECM
 SG_ BattULoChrg_D_Rq : 7|2@0+ (1,0) [0|3] "SED"  ECM_Diesel,ECM_HEVDSL,PCM,PCM_HEV,ECM
 SG_ PwSysULoFalt_D_Stat : 12|4@0+ (1,0) [0|15] "SED"  PSCM,ABS_ESC
 SG_ Shed_T_Eng_Off_B : 8|1@0+ (1,0) [0|1] "SED"  GENERIC
 SG_ Shed_Feature_Group_ID : 20|5@0+ (1,0) [0|31] "SED"  ECM_Diesel,ECM_HEV,ECM_HEVDSL,PCM,PCM_HEV,IPMA_ADAS,ECM
 SG_ Shed_Drain_Eng_Off_B : 0|1@0+ (1,0) [0|1] "SED"  GENERIC
 SG_ Shed_Level_Req : 23|3@0+ (1,0) [0|7] "SED"  ECM_Diesel,ECM_HEV,ECM_HEVDSL,PCM,PCM_HEV,ABS_ESC,IPMA_ADAS,ECM
 SG_ BattULoSrvc_T_Actl : 39|12@0+ (1,0) [0|4095] "days"  ECM_HEV
 SG_ ULoRgenTestMde_B_Rq : 31|1@0+ (1,0) [0|1] "SED"  ECM_Diesel,ECM_HEVDSL,PCM,PCM_HEV,ECM
 SG_ ChargeMode : 15|3@0+ (1,0) [0|7] "SED"  ECM_Diesel,ECM_HEVDSL,PCM,PCM_HEV,ECM
 SG_ IdleSpeedIncrease_El : 3|1@0+ (1,0) [0|1] "SED"  ECM_Diesel,ECM_HEVDSL,PCM,PCM_HEV,ECM
 SG_ Batt_Lo_SoC_B : 5|1@0+ (1,0) [0|1] "SED"  GENERIC
 SG_ PeriodicElLoad_B_Stat : 1|1@0+ (1,0) [0|1] "SED"  ECM_Diesel,ECM_HEVDSL,PCM,PCM_HEV,ECM
 SG_ Batt_Crit_SoC_B : 4|1@0+ (1,0) [0|1] "SED"  GENERIC

CM_ SG_ 360 GsmSrvcRqd_B_Rq "Signal not transmitted on vehicles that do not have shift by wire.";
CM_ SG_ 360 TrnTrcmPwmSig_D_Actl "Signal not transmitted on vehicles that do not have shift by wire.";
CM_ SG_ 360 TrnGearPwmFalt_B_Actl "Signal not transmitted on vehicles that do not have shift by wire.";
CM_ SG_ 360 GearButtnStuck_B_Actl "Signal not transmitted on vehicles that do not have shift by wire.";
CM_ SG_ 93 TrnTrcmNtmState_D_Actl "Signal not transmitted on vehicles that do not have shift by wire.";
CM_ SG_ 93 TrnSns2Pos_Pc_Actl "Signal not transmitted on vehicles that do not have shift by wire.";
CM_ SG_ 93 TrnSns1Pos_Pc_Actl "Signal not transmitted on vehicles that do not have shift by wire.";
CM_ SG_ 93 TrnSecPrkStat_D_Actl "Signal not transmitted on vehicles that do not have shift by wire.";
CM_ SG_ 93 TrnNtrlTowCnfm_B_Actl "Signal not transmitted on vehicles that do not have shift by wire.";
CM_ SG_ 93 TrnGearFinalPos_B_Actl "Signal not transmitted on vehicles that do not have shift by wire.";
CM_ SG_ 93 TrnGearCnfm_No_Cs "Signal not transmitted on vehicles that do not have shift by wire.";
CM_ SG_ 93 TrnGearCnfm_No_Cnt "Signal not transmitted on vehicles that do not have shift by wire.";
CM_ SG_ 93 TrnGear_D_Actl "Signal not transmitted on vehicles that do not have shift by wire.";
CM_ SG_ 90 TrnGsmNtmState_D_Actl "Signal not transmitted on vehicles that do not have shift by wire.";
CM_ SG_ 90 DrQltyDrv_D_StatGsm "Signal not transmitted on vehicles that do not have shift by wire.";
CM_ SG_ 90 TrnBtsiOvrrd_B_Stat "Signal not transmitted on vehicles that do not have shift by wire.";
CM_ SG_ 90 TrnValidGearRq_D_Stat "Signal not transmitted on vehicles that do not have shift by wire.";
CM_ SG_ 90 TrnGearRqCnt_B_Actl "Signal not transmitted on vehicles that do not have shift by wire.";
CM_ SG_ 90 TrnGearButtn_U_Actl "Signal not transmitted on vehicles that do not have shift by wire.";
CM_ SG_ 90 TrnGearButtn_B_ActlR2 "Signal not transmitted on vehicles that do not have shift by wire.";
CM_ SG_ 90 TrnGearButtn_B_ActlR1 "Signal not transmitted on vehicles that do not have shift by wire.";
CM_ SG_ 90 TrnGearButtn_B_ActlR0 "Signal not transmitted on vehicles that do not have shift by wire.";
CM_ SG_ 90 TrnGearButtn_B_ActlP2 "Signal not transmitted on vehicles that do not have shift by wire.";
CM_ SG_ 90 TrnGearButtn_B_ActlP1 "Signal not transmitted on vehicles that do not have shift by wire.";
CM_ SG_ 90 TrnGearButtn_B_ActlP0 "Signal not transmitted on vehicles that do not have shift by wire.";
CM_ SG_ 90 TrnGearButtn_B_ActlN2 "Signal not transmitted on vehicles that do not have shift by wire.";
CM_ SG_ 90 TrnGearButtn_B_ActlN1 "Signal not transmitted on vehicles that do not have shift by wire.";
CM_ SG_ 90 TrnGearButtn_B_ActlN0 "Signal not transmitted on vehicles that do not have shift by wire.";
CM_ SG_ 90 TrnGearButtn_B_ActlM2 "Signal not transmitted on vehicles that do not have shift by wire.";
CM_ SG_ 90 TrnGearButtn_B_ActlM1 "Signal not transmitted on vehicles that do not have shift by wire.";
CM_ SG_ 90 TrnGearButtn_B_ActlM0 "Signal not transmitted on vehicles that do not have shift by wire.";
CM_ SG_ 90 TrnGearButtn_B_ActlD2 "Signal not transmitted on vehicles that do not have shift by wire.";
CM_ SG_ 90 TrnGearButtn_B_ActlD1 "Signal not transmitted on vehicles that do not have shift by wire.";
CM_ SG_ 90 TrnGearButtn_B_ActlD0 "Signal not transmitted on vehicles that do not have shift by wire.";
CM_ SG_ 90 TrnGear_No_Cs "Signal not transmitted on vehicles that do not have shift by wire.";
CM_ SG_ 90 TrnGear_No_Cnt "Signal not transmitted on vehicles that do not have shift by wire.";
CM_ SG_ 90 TrnGear_D_RqDrv "Signal not transmitted on vehicles that do not have shift by wire.";
CM_ SG_ 90 BrkSwtchPos_B_ActlGsm "Signal not transmitted on vehicles that do not have shift by wire.";
CM_ BO_ 1111 " new RCM Serial Trailer Aid (TrailerAid_Stat1) 48 bits";
CM_ BO_ 1106 " new RCM Serial Trailer Aid (TrailerAid_Stat1) 48 bits";
CM_ SG_ 1091 PoliceAux4Lamp_B_Rq2 "Signal not transmitted on programs that do not have AWD.";
CM_ SG_ 1091 PoliceAux3Lamp_B_Rq2 "Signal not transmitted on programs that do not have AWD.";
CM_ SG_ 1091 PoliceAux2Lamp_B_Rq2 "Signal not transmitted on programs that do not have AWD.";
CM_ SG_ 1091 PoliceAux1Lamp_B_Rq2 "Signal not transmitted on programs that do not have AWD.";
CM_ SG_ 138 SteWhlRelCalib_An_Sns "Signal is not transmitted on vehicles where PSCM is transmitting the message that contains this signal.
Signal data set to 0x0 for ABS only vehicle option content";
CM_ BO_ 1078 "not supported by DCDC variants";
CM_ SG_ 1093 StopLamp_B_RqTrlrBrk "Signal not transmitted on all variants.";
CM_ SG_ 792 ElTrip_L_Dsply "Key cycle trip distance driven with the engine off (Trip EV Miles)";
CM_ SG_ 792 ElLongTerm_L_Dsply "Long term distance distance driven with the engine off since the last long term reset (Long Term EV Miles).";
CM_ SG_ 765 Mc_VehUntTrpCoUsrSel_St "Object.VehicleSettings.Disp_Miles_Kilometers.Rq";
CM_ SG_ 765 Mc_VehUnitTempUsrSel_St "Object.VehicleSettings.Disp_Temperature.Rq";
CM_ SG_ 765 Mc_VehDayNightUsrSel_St "Object.BodyInterface.Settings.VehicleDayNightUserSelection
Object.BodyInterface.Status.AMDayNightSensitivity";
CM_ SG_ 765 Mc_VehTimeFrmtUsrSel_St "Object.BodyInterface.Settings.VehicleTimeFormatUserSelection";
CM_ SG_ 765 Mc_VehThemeUsrSel_St "Object.BodyInterface.Settings.VehicleThemeUserSelection";
CM_ SG_ 765 Mc_VehLangUsrSel_St "Object.BodyInterface.Settings.VehicleLanguageUserSelection
Object Vehicle Settings.Disp_LangSel
";
CM_ BO_ 559 "APIM Tx";
CM_ BO_ 558 "APIM Tx";
CM_ SG_ 934 Side_Detect_L_Illum "DDMGenSigTimeoutTime=2000";
CM_ SG_ 934 SodLeft_D_Stat "IPCGenSigTimeoutTime=1600";
CM_ SG_ 934 SodSnsLeft_D_Stat "IPCGenSigTimeoutTime=1600";
CM_ SG_ 934 SodAlrtLeft_D_Stat "DDMGenSigTimeoutTime=2000";
CM_ SG_ 1072 MetricActv_B_Actl "0 =Inactive(English), 1=Active(Metric)";
CM_ SG_ 145 VehYaw_W_Actl "CCMGenSigTimeoutTime=1000";
CM_ BO_ 65 "Provide control function information to the target function of the Passive Anti-Theft Subsystem";
CM_ SG_ 836 Foh_D_Stat "Signal not transmitted on vehicles that do not have the Fuel operated heater feature.";
CM_ SG_ 836 FuelFlw_Vl_ActlFoh "Signal not transmitted on vehicles that do not have the Fuel operated heater feature.";
CM_ SG_ 836 EngClnt_Te_ActlFoh "Signal not transmitted on vehicles that do not have the Fuel operated heater feature.";
CM_ SG_ 836 FohFalt_D_Stat "Signal not transmitted on vehicles that do not have the Fuel operated heater feature.";
CM_ SG_ 836 FohEnbl_B_RqDrv "Signal not transmitted on vehicles that do not have the Fuel operated heater feature.";
CM_ SG_ 836 FohRqRun_B_Rq "Signal not transmitted on vehicles that do not have the Fuel operated heater feature.";
CM_ SG_ 836 HvacPrecondMode_D_Rq "Signal not transmitted on vehicles that do not have the Fuel operated heater feature.";
CM_ SG_ 836 HvacPrecondBlwr_D_Rq "Signal not transmitted on vehicles that do not have the Fuel operated heater feature.";
CM_ SG_ 931 CrnkInhbt_No_Cs "Signal not transmitted on gas and HEV variants.";
CM_ SG_ 931 CrnkInhbt_No_Cnt "Signal not transmitted on gas and HEV variants.";
CM_ SG_ 947 Dimming_Lvl "Refer to Vehicle Interior Illum Dimming Ctrl Sys Eng Spec, Table 2
";
CM_ SG_ 947 PrkBrkActv_B_Actl "Signal not transmitted on vehicles with electric park brake. ";
BA_DEF_ BO_  "VFrameFormat" ENUM  "StandardCAN","ExtendedCAN","reserved","reserved","reserved","reserved","reserved","reserved","reserved","reserved","reserved","reserved","reserved","reserved","StandardCAN_FD","ExtendedCAN_FD";
BA_DEF_ BO_  "DiagConnection" INT 0 256;
BA_DEF_ BO_  "FrameRouting" STRING ;
BA_DEF_ BO_  "FrameGatewayNetwork" STRING ;
BA_DEF_ BO_  "NetworkInitialization" ENUM  "No","Yes";
BA_DEF_ BO_  "FrameGatewayId" HEX 0 1407;
BA_DEF_ BO_  "EventRateOfChange" INT 10 10000;
BA_DEF_ BO_  "GenMsgStartDelayTime" INT 0 10000;
BA_DEF_ BO_  "GenMsgNrOfRepetition" INT 0 100;
BA_DEF_ BO_  "GenMsgDelayTime" INT 0 1000;
BA_DEF_ BO_  "GenMsgCycleTime" INT 0 100000;
BA_DEF_ BO_  "GenMsgSendType" ENUM  "FixedPeriodic","Event","EnabledPeriodic","NotUsed","NotUsed","EventPeriodic","NotUsed","NotUsed","NoMsgSendType";
BA_DEF_ SG_  "U_U55X_MY2022_Tx" ENUM  "No","Yes";
BA_DEF_ SG_  "U_CD542_MY2021_Tx" ENUM  "No","Yes";
BA_DEF_ SG_  "ECGUsedTxSignal" ENUM  "No","Yes";
BA_DEF_ SG_  "U_T6_MCA_MY2020_Tx" ENUM  "No","Yes";
BA_DEF_ SG_  "U_P702_MY2021_Tx" ENUM  "No","Yes";
BA_DEF_ SG_  "U_CX727_MY2021_Tx" ENUM  "No","Yes";
BA_DEF_ SG_  "U_U55X_MY2022_Rx" ENUM  "No","Yes";
BA_DEF_ SG_  "U_CD542_MY2021_Rx" ENUM  "No","Yes";
BA_DEF_ SG_  "ECGUsedRxSignal" ENUM  "No","Yes";
BA_DEF_ SG_  "U_T6_MCA_MY2020_Rx" ENUM  "No","Yes";
BA_DEF_ SG_  "U_P702_MY2021_Rx" ENUM  "No","Yes";
BA_DEF_ SG_  "U_CX727_MY2021_Rx" ENUM  "No","Yes";
BA_DEF_ SG_  "GenSigStartValue" HEX 0 268435455;
BA_DEF_ SG_  "MetaData" ENUM  "No","Yes";
BA_DEF_ SG_  "ContentDependant" ENUM  "No","Yes";
BA_DEF_ SG_  "GenSigStartValueInteger" INT 0 1000000000;
BA_DEF_ SG_  "UsedOnPgmDBC" ENUM  "No","Yes";
BA_DEF_ SG_  "WakeupSignal" ENUM  "No","Yes";
BA_DEF_ SG_  "GenSigInactiveValue" INT 0 100000;
BA_DEF_ SG_  "GenSigSendType" ENUM  "Cyclic","OnWrite","vector_leerstring","OnChange","vector_leerstring","IfActive","vector_leerstring","NoSigSendType";
BA_DEF_ BO_  "OvtpPushApplication" ENUM  "FALSE","TRUE";
BA_DEF_ BO_  "SCP_FreshnessValueLength" INT 0 512;
BA_DEF_ BO_  "SCP_FreshnessValueTxLength" INT 0 512;
BA_DEF_ BO_  "SCP_AuthInfoTxLength" INT 0 512;
BA_DEF_ BO_  "ProgBWConditional" STRING ;
BA_DEF_ BO_  "NmAsrMessage" ENUM  "No","Yes";
BA_DEF_ BO_  "TpApplType" STRING ;
BA_DEF_ BO_  "DiagState" ENUM  "No","Yes";
BA_DEF_ BO_  "TpTxIndex" INT 0 536870911;
BA_DEF_ BO_  "DiagRequest" ENUM  "No","Yes";
BA_DEF_ BO_  "DiagResponse" ENUM  "No","Yes";
BA_DEF_ BO_  "GenMsgILSupport" ENUM  "No","Yes";
BA_DEF_DEF_  "VFrameFormat" "ExtendedCAN_FD";
BA_DEF_DEF_  "DiagConnection" 0;
BA_DEF_DEF_  "FrameRouting" "";
BA_DEF_DEF_  "FrameGatewayNetwork" "NONE";
BA_DEF_DEF_  "NetworkInitialization" "Yes";
BA_DEF_DEF_  "FrameGatewayId" 0;
BA_DEF_DEF_  "EventRateOfChange" 10000;
BA_DEF_DEF_  "GenMsgStartDelayTime" 0;
BA_DEF_DEF_  "GenMsgNrOfRepetition" 1;
BA_DEF_DEF_  "GenMsgDelayTime" 20;
BA_DEF_DEF_  "GenMsgCycleTime" 0;
BA_DEF_DEF_  "GenMsgSendType" "NoMsgSendType";
BA_DEF_DEF_  "U_U55X_MY2022_Tx" "No";
BA_DEF_DEF_  "U_CD542_MY2021_Tx" "No";
BA_DEF_DEF_  "ECGUsedTxSignal" "No";
BA_DEF_DEF_  "U_T6_MCA_MY2020_Tx" "No";
BA_DEF_DEF_  "U_P702_MY2021_Tx" "No";
BA_DEF_DEF_  "U_CX727_MY2021_Tx" "No";
BA_DEF_DEF_  "U_U55X_MY2022_Rx" "No";
BA_DEF_DEF_  "U_CD542_MY2021_Rx" "No";
BA_DEF_DEF_  "ECGUsedRxSignal" "No";
BA_DEF_DEF_  "U_T6_MCA_MY2020_Rx" "No";
BA_DEF_DEF_  "U_P702_MY2021_Rx" "No";
BA_DEF_DEF_  "U_CX727_MY2021_Rx" "No";
BA_DEF_DEF_  "GenSigStartValue" 0;
BA_DEF_DEF_  "MetaData" "No";
BA_DEF_DEF_  "ContentDependant" "No";
BA_DEF_DEF_  "GenSigStartValueInteger" 0;
BA_DEF_DEF_  "UsedOnPgmDBC" "Yes";
BA_DEF_DEF_  "WakeupSignal" "No";
BA_DEF_DEF_  "GenSigInactiveValue" 0;
BA_DEF_DEF_  "GenSigSendType" "NoSigSendType";
BA_DEF_DEF_  "OvtpPushApplication" "FALSE";
BA_DEF_DEF_  "SCP_FreshnessValueLength" 64;
BA_DEF_DEF_  "SCP_FreshnessValueTxLength" 11;
BA_DEF_DEF_  "SCP_AuthInfoTxLength" 53;
BA_DEF_DEF_  "ProgBWConditional" "NONE";
BA_DEF_DEF_  "NmAsrMessage" "No";
BA_DEF_DEF_  "TpApplType" "";
BA_DEF_DEF_  "DiagState" "No";
BA_DEF_DEF_  "TpTxIndex" 0;
BA_DEF_DEF_  "DiagRequest" "No";
BA_DEF_DEF_  "DiagResponse" "No";
BA_DEF_DEF_  "GenMsgILSupport" "Yes";
BA_ "FrameRouting" BO_ 360 "HS2_CAN,0x168;";
BA_ "FrameGatewayNetwork" BO_ 360 "HS2_CAN";
BA_ "FrameGatewayId" BO_ 360 360;
BA_ "VFrameFormat" BO_ 360 14;
BA_ "FrameRouting" BO_ 331 "FD1_CAN,0x14B;HS1_CAN,0x14B;";
BA_ "VFrameFormat" BO_ 331 14;
BA_ "FrameRouting" BO_ 140 "HS3_CAN,0x8C;";
BA_ "FrameGatewayNetwork" BO_ 140 "HS3_CAN";
BA_ "FrameGatewayId" BO_ 140 140;
BA_ "VFrameFormat" BO_ 140 14;
BA_ "FrameRouting" BO_ 122 "HS1_CAN,0x7A;";
BA_ "FrameGatewayNetwork" BO_ 122 "HS1_CAN";
BA_ "FrameGatewayId" BO_ 122 122;
BA_ "VFrameFormat" BO_ 122 14;
BA_ "FrameRouting" BO_ 93 "HS2_CAN,0x5D;";
BA_ "FrameGatewayNetwork" BO_ 93 "HS2_CAN";
BA_ "FrameGatewayId" BO_ 93 93;
BA_ "VFrameFormat" BO_ 93 14;
BA_ "GenMsgSendType" BO_ 90 5;
BA_ "GenMsgCycleTime" BO_ 90 100;
BA_ "FrameRouting" BO_ 90 "*";
BA_ "FrameGatewayNetwork" BO_ 90 "HS2_CAN";
BA_ "FrameGatewayId" BO_ 90 90;
BA_ "VFrameFormat" BO_ 90 14;
BA_ "FrameRouting" BO_ 1114 "HS3_CAN,0x45A;";
BA_ "FrameGatewayNetwork" BO_ 1114 "HS3_CAN";
BA_ "FrameGatewayId" BO_ 1114 1114;
BA_ "VFrameFormat" BO_ 1114 14;
BA_ "GenMsgSendType" BO_ 1111 5;
BA_ "GenMsgCycleTime" BO_ 1111 50;
BA_ "FrameRouting" BO_ 1111 "*";
BA_ "FrameGatewayNetwork" BO_ 1111 "HS2_CAN";
BA_ "FrameGatewayId" BO_ 1111 1111;
BA_ "VFrameFormat" BO_ 1111 14;
BA_ "GenMsgSendType" BO_ 1106 5;
BA_ "GenMsgCycleTime" BO_ 1106 1000;
BA_ "FrameRouting" BO_ 1106 "*";
BA_ "FrameGatewayNetwork" BO_ 1106 "HS2_CAN";
BA_ "FrameGatewayId" BO_ 1106 1106;
BA_ "VFrameFormat" BO_ 1106 14;
BA_ "GenMsgSendType" BO_ 1091 5;
BA_ "GenMsgCycleTime" BO_ 1091 1000;
BA_ "FrameRouting" BO_ 1091 "*";
BA_ "VFrameFormat" BO_ 1091 14;
BA_ "FrameRouting" BO_ 138 "HS2_CAN,0x8A;";
BA_ "FrameGatewayNetwork" BO_ 138 "HS2_CAN";
BA_ "FrameGatewayId" BO_ 138 138;
BA_ "VFrameFormat" BO_ 138 14;
BA_ "GenMsgSendType" BO_ 131 5;
BA_ "GenMsgCycleTime" BO_ 131 100;
BA_ "FrameRouting" BO_ 131 "*";
BA_ "FrameGatewayNetwork" BO_ 131 "HS2_CAN";
BA_ "FrameGatewayId" BO_ 131 131;
BA_ "VFrameFormat" BO_ 131 14;
BA_ "FrameRouting" BO_ 787 "MS1_CAN,0x313;MS2_CAN,0x313";
BA_ "VFrameFormat" BO_ 787 14;
BA_ "GenMsgDelayTime" BO_ 570 10;
BA_ "GenMsgCycleTime" BO_ 570 20;
BA_ "GenMsgSendType" BO_ 570 0;
BA_ "VFrameFormat" BO_ 570 14;
BA_ "FrameRouting" BO_ 953 "HS1_CAN,0x3B9;";
BA_ "FrameGatewayNetwork" BO_ 953 "HS1_CAN";
BA_ "FrameGatewayId" BO_ 953 953;
BA_ "VFrameFormat" BO_ 953 14;
BA_ "GenMsgCycleTime" BO_ 1101 1000;
BA_ "GenMsgSendType" BO_ 1101 5;
BA_ "VFrameFormat" BO_ 1101 14;
BA_ "FrameRouting" BO_ 1099 "HS1_CAN,0x44B;";
BA_ "FrameGatewayNetwork" BO_ 1099 "HS1_CAN";
BA_ "FrameGatewayId" BO_ 1099 1099;
BA_ "VFrameFormat" BO_ 1099 14;
BA_ "FrameRouting" BO_ 1078 "HS1_CAN,0x436;";
BA_ "FrameGatewayNetwork" BO_ 1078 "HS1_CAN";
BA_ "FrameGatewayId" BO_ 1078 1078;
BA_ "VFrameFormat" BO_ 1078 14;
BA_ "GenMsgCycleTime" BO_ 1052 50;
BA_ "GenMsgSendType" BO_ 1052 0;
BA_ "VFrameFormat" BO_ 1052 14;
BA_ "GenMsgSendType" BO_ 1093 5;
BA_ "GenMsgCycleTime" BO_ 1093 100;
BA_ "FrameRouting" BO_ 1093 "*";
BA_ "FrameGatewayNetwork" BO_ 1093 "HS3_CAN";
BA_ "FrameGatewayId" BO_ 1093 1093;
BA_ "VFrameFormat" BO_ 1093 14;
BA_ "GenMsgCycleTime" BO_ 837 1000;
BA_ "GenMsgSendType" BO_ 837 5;
BA_ "VFrameFormat" BO_ 837 14;
BA_ "FrameRouting" BO_ 792 "HS3_CAN,0x318;";
BA_ "FrameGatewayNetwork" BO_ 792 "HS3_CAN";
BA_ "FrameGatewayId" BO_ 792 792;
BA_ "VFrameFormat" BO_ 792 14;
BA_ "FrameRouting" BO_ 968 "HS3_CAN,0x3C8;";
BA_ "FrameGatewayNetwork" BO_ 968 "HS3_CAN";
BA_ "FrameGatewayId" BO_ 968 968;
BA_ "VFrameFormat" BO_ 968 14;
BA_ "GenMsgSendType" BO_ 819 5;
BA_ "GenMsgCycleTime" BO_ 819 100;
BA_ "FrameRouting" BO_ 819 "*";
BA_ "FrameGatewayNetwork" BO_ 819 "MS1_CAN";
BA_ "FrameGatewayId" BO_ 819 819;
BA_ "VFrameFormat" BO_ 819 14;
BA_ "GenMsgSendType" BO_ 818 5;
BA_ "GenMsgCycleTime" BO_ 818 100;
BA_ "FrameRouting" BO_ 818 "*";
BA_ "FrameGatewayNetwork" BO_ 818 "MS1_CAN";
BA_ "FrameGatewayId" BO_ 818 818;
BA_ "VFrameFormat" BO_ 818 14;
BA_ "FrameRouting" BO_ 806 "MS1_CAN,0x326;";
BA_ "FrameGatewayNetwork" BO_ 806 "MS1_CAN";
BA_ "FrameGatewayId" BO_ 806 806;
BA_ "VFrameFormat" BO_ 806 14;
BA_ "GenMsgSendType" BO_ 765 5;
BA_ "GenMsgCycleTime" BO_ 765 1000;
BA_ "FrameRouting" BO_ 765 "*";
BA_ "FrameGatewayNetwork" BO_ 765 "HS3_CAN";
BA_ "FrameGatewayId" BO_ 765 765;
BA_ "VFrameFormat" BO_ 765 14;
BA_ "FrameRouting" BO_ 518 "HS1_CAN,0x206;";
BA_ "FrameGatewayNetwork" BO_ 518 "HS1_CAN";
BA_ "FrameGatewayId" BO_ 518 518;
BA_ "VFrameFormat" BO_ 518 14;
BA_ "GenMsgSendType" BO_ 559 5;
BA_ "GenMsgCycleTime" BO_ 559 1000;
BA_ "FrameRouting" BO_ 559 "*";
BA_ "FrameGatewayNetwork" BO_ 559 "HS3_CAN";
BA_ "FrameGatewayId" BO_ 559 559;
BA_ "VFrameFormat" BO_ 559 14;
BA_ "GenMsgSendType" BO_ 558 5;
BA_ "GenMsgCycleTime" BO_ 558 1000;
BA_ "FrameRouting" BO_ 558 "*";
BA_ "FrameGatewayNetwork" BO_ 558 "HS3_CAN";
BA_ "FrameGatewayId" BO_ 558 558;
BA_ "VFrameFormat" BO_ 558 14;
BA_ "GenMsgCycleTime" BO_ 934 200;
BA_ "GenMsgSendType" BO_ 934 5;
BA_ "VFrameFormat" BO_ 934 14;
BA_ "FrameRouting" BO_ 825 "HS2_CAN,0x339;";
BA_ "FrameGatewayNetwork" BO_ 825 "HS2_CAN";
BA_ "FrameGatewayId" BO_ 825 825;
BA_ "VFrameFormat" BO_ 825 14;
BA_ "GenMsgSendType" BO_ 1072 5;
BA_ "GenMsgCycleTime" BO_ 1072 100;
BA_ "FrameRouting" BO_ 1072 "*";
BA_ "FrameGatewayNetwork" BO_ 1072 "HS3_CAN";
BA_ "FrameGatewayId" BO_ 1072 1072;
BA_ "VFrameFormat" BO_ 1072 14;
BA_ "GenMsgSendType" BO_ 909 5;
BA_ "GenMsgCycleTime" BO_ 909 1000;
BA_ "FrameRouting" BO_ 909 "*";
BA_ "FrameGatewayNetwork" BO_ 909 "HS1_CAN";
BA_ "FrameGatewayId" BO_ 909 909;
BA_ "VFrameFormat" BO_ 909 14;
BA_ "GenMsgSendType" BO_ 963 5;
BA_ "GenMsgCycleTime" BO_ 963 1000;
BA_ "FrameRouting" BO_ 963 "*";
BA_ "FrameGatewayNetwork" BO_ 963 "HS1_CAN";
BA_ "FrameGatewayId" BO_ 963 963;
BA_ "VFrameFormat" BO_ 963 14;
BA_ "GenMsgSendType" BO_ 145 5;
BA_ "GenMsgCycleTime" BO_ 145 10;
BA_ "FrameRouting" BO_ 145 "*";
BA_ "FrameGatewayNetwork" BO_ 145 "HS2_CAN";
BA_ "FrameGatewayId" BO_ 145 145;
BA_ "VFrameFormat" BO_ 145 14;
BA_ "GenMsgSendType" BO_ 76 5;
BA_ "GenMsgCycleTime" BO_ 76 100;
BA_ "FrameRouting" BO_ 76 "*";
BA_ "FrameGatewayNetwork" BO_ 76 "HS2_CAN";
BA_ "FrameGatewayId" BO_ 76 76;
BA_ "VFrameFormat" BO_ 76 14;
BA_ "FrameRouting" BO_ 65 "HS1_CAN,0x41;";
BA_ "FrameGatewayNetwork" BO_ 65 "HS1_CAN";
BA_ "FrameGatewayId" BO_ 65 65;
BA_ "VFrameFormat" BO_ 65 14;
BA_ "GenMsgSendType" BO_ 1076 5;
BA_ "GenMsgCycleTime" BO_ 1076 100;
BA_ "FrameRouting" BO_ 1076 "*";
BA_ "FrameGatewayNetwork" BO_ 1076 "HS3_CAN";
BA_ "FrameGatewayId" BO_ 1076 1076;
BA_ "VFrameFormat" BO_ 1076 14;
BA_ "FrameRouting" BO_ 836 "MS1_CAN,0x344;";
BA_ "FrameGatewayNetwork" BO_ 836 "MS1_CAN";
BA_ "FrameGatewayId" BO_ 836 836;
BA_ "VFrameFormat" BO_ 836 14;
BA_ "GenMsgSendType" BO_ 862 5;
BA_ "GenMsgCycleTime" BO_ 862 1000;
BA_ "FrameRouting" BO_ 862 "*";
BA_ "FrameGatewayNetwork" BO_ 862 "MS1_CAN";
BA_ "FrameGatewayId" BO_ 862 862;
BA_ "VFrameFormat" BO_ 862 14;
BA_ "FrameRouting" BO_ 931 "HS1_CAN,0x3A3;";
BA_ "FrameGatewayNetwork" BO_ 931 "HS1_CAN";
BA_ "FrameGatewayId" BO_ 931 931;
BA_ "VFrameFormat" BO_ 931 14;
BA_ "GenMsgSendType" BO_ 578 0;
BA_ "GenMsgCycleTime" BO_ 578 40;
BA_ "FrameRouting" BO_ 578 "*";
BA_ "FrameGatewayNetwork" BO_ 578 "HS1_CAN";
BA_ "FrameGatewayId" BO_ 578 578;
BA_ "VFrameFormat" BO_ 578 14;
BA_ "GenMsgSendType" BO_ 947 5;
BA_ "GenMsgCycleTime" BO_ 947 500;
BA_ "FrameRouting" BO_ 947 "*";
BA_ "FrameGatewayNetwork" BO_ 947 "HS1_CAN";
BA_ "FrameGatewayId" BO_ 947 947;
BA_ "VFrameFormat" BO_ 947 14;
BA_ "FrameRouting" BO_ 1084 "HS1_CAN,0x43C;";
BA_ "FrameGatewayNetwork" BO_ 1084 "HS1_CAN";
BA_ "FrameGatewayId" BO_ 1084 1084;
BA_ "VFrameFormat" BO_ 1084 14;
BA_ "GenMsgSendType" BO_ 1068 5;
BA_ "GenMsgCycleTime" BO_ 1068 50;
BA_ "FrameRouting" BO_ 1068 "*";
BA_ "FrameGatewayNetwork" BO_ 1068 "HS1_CAN";
BA_ "FrameGatewayId" BO_ 1068 1068;
BA_ "VFrameFormat" BO_ 1068 14;
BA_ "U_CD542_MY2021_Rx" SG_ 360 GsmSrvcRqd_B_Rq 1;
BA_ "U_CX727_MY2021_Rx" SG_ 360 GsmSrvcRqd_B_Rq 1;
BA_ "ContentDependant" SG_ 360 GsmSrvcRqd_B_Rq 1;
BA_ "ContentDependant" SG_ 360 TrnTrcmPwmSig_D_Actl 1;
BA_ "U_U55X_MY2022_Rx" SG_ 360 TrnGearPwmFalt_B_Actl 1;
BA_ "U_T6_MCA_MY2020_Rx" SG_ 360 TrnGearPwmFalt_B_Actl 1;
BA_ "U_P702_MY2021_Rx" SG_ 360 TrnGearPwmFalt_B_Actl 1;
BA_ "U_CD542_MY2021_Rx" SG_ 360 TrnGearPwmFalt_B_Actl 1;
BA_ "U_CX727_MY2021_Rx" SG_ 360 TrnGearPwmFalt_B_Actl 1;
BA_ "ContentDependant" SG_ 360 TrnGearPwmFalt_B_Actl 1;
BA_ "U_U55X_MY2022_Rx" SG_ 360 GearButtnStuck_B_Actl 1;
BA_ "U_T6_MCA_MY2020_Rx" SG_ 360 GearButtnStuck_B_Actl 1;
BA_ "U_P702_MY2021_Rx" SG_ 360 GearButtnStuck_B_Actl 1;
BA_ "U_CD542_MY2021_Rx" SG_ 360 GearButtnStuck_B_Actl 1;
BA_ "U_CX727_MY2021_Rx" SG_ 360 GearButtnStuck_B_Actl 1;
BA_ "ContentDependant" SG_ 360 GearButtnStuck_B_Actl 1;
BA_ "MetaData" SG_ 331 TrnAout2ActUflt_No_Cnt 1;
BA_ "MetaData" SG_ 331 TrnAout2ActlUflt_No_Cs 1;
BA_ "GenSigStartValue" SG_ 331 TrnAout2_W_ActlUnfilt 65534;
BA_ "GenSigStartValueInteger" SG_ 331 TrnAout2_W_ActlUnfilt 65534;
BA_ "U_CD542_MY2021_Tx" SG_ 331 CmbbEngTqMn_B_ActlHtrn 1;
BA_ "U_CX727_MY2021_Tx" SG_ 331 CmbbEngTqMn_B_ActlHtrn 1;
BA_ "U_CD542_MY2021_Rx" SG_ 331 CmbbEngTqMn_B_ActlHtrn 1;
BA_ "U_CD542_MY2021_Tx" SG_ 331 CmbbDeny_B_ActlHtrn 1;
BA_ "U_CX727_MY2021_Tx" SG_ 331 CmbbDeny_B_ActlHtrn 1;
BA_ "U_CD542_MY2021_Rx" SG_ 331 CmbbDeny_B_ActlHtrn 1;
BA_ "U_CD542_MY2021_Rx" SG_ 122 BattTrac_U_LimLo 1;
BA_ "U_P702_MY2021_Rx" SG_ 122 BattTrac_U_LimLo 1;
BA_ "U_CX727_MY2021_Rx" SG_ 122 BattTrac_U_LimLo 1;
BA_ "GenSigStartValue" SG_ 122 BattTrac_U_LimLo 88;
BA_ "GenSigStartValueInteger" SG_ 122 BattTrac_U_LimLo 88;
BA_ "U_CD542_MY2021_Rx" SG_ 122 BattTrac_U_LimHi 1;
BA_ "U_P702_MY2021_Rx" SG_ 122 BattTrac_U_LimHi 1;
BA_ "U_CX727_MY2021_Rx" SG_ 122 BattTrac_U_LimHi 1;
BA_ "GenSigStartValue" SG_ 122 BattTrac_U_LimHi 163;
BA_ "GenSigStartValueInteger" SG_ 122 BattTrac_U_LimHi 163;
BA_ "U_CD542_MY2021_Rx" SG_ 122 VehStrtInhbt_B_RqBatt 1;
BA_ "U_P702_MY2021_Rx" SG_ 122 VehStrtInhbt_B_RqBatt 1;
BA_ "U_CX727_MY2021_Rx" SG_ 122 VehStrtInhbt_B_RqBatt 1;
BA_ "U_CD542_MY2021_Rx" SG_ 122 BattTracOffFst_D_Actl 1;
BA_ "U_P702_MY2021_Rx" SG_ 122 BattTracOffFst_D_Actl 1;
BA_ "U_CX727_MY2021_Rx" SG_ 122 BattTracOffFst_D_Actl 1;
BA_ "U_CD542_MY2021_Rx" SG_ 122 BattTracOff_B_Actl 1;
BA_ "U_P702_MY2021_Rx" SG_ 122 BattTracOff_B_Actl 1;
BA_ "U_CX727_MY2021_Rx" SG_ 122 BattTracOff_B_Actl 1;
BA_ "U_CD542_MY2021_Rx" SG_ 122 BattTracMil_D_Rq 1;
BA_ "U_CX727_MY2021_Rx" SG_ 122 BattTracMil_D_Rq 1;
BA_ "U_CX727_MY2021_Rx" SG_ 122 BattTracCnnct_B_Cmd 1;
BA_ "U_CD542_MY2021_Rx" SG_ 122 BattTrac_U_Actl 1;
BA_ "U_P702_MY2021_Rx" SG_ 122 BattTrac_U_Actl 1;
BA_ "U_CX727_MY2021_Rx" SG_ 122 BattTrac_U_Actl 1;
BA_ "GenSigStartValue" SG_ 122 BattTrac_U_Actl 1022;
BA_ "GenSigStartValueInteger" SG_ 122 BattTrac_U_Actl 1022;
BA_ "U_CD542_MY2021_Rx" SG_ 122 BattTrac_I_Actl 1;
BA_ "U_P702_MY2021_Rx" SG_ 122 BattTrac_I_Actl 1;
BA_ "U_CX727_MY2021_Rx" SG_ 122 BattTrac_I_Actl 1;
BA_ "GenSigStartValueInteger" SG_ 122 BattTrac_I_Actl 15000;
BA_ "ContentDependant" SG_ 93 TrnTrcmNtmState_D_Actl 1;
BA_ "ContentDependant" SG_ 93 TrnSns2Pos_Pc_Actl 1;
BA_ "ContentDependant" SG_ 93 TrnSns1Pos_Pc_Actl 1;
BA_ "ContentDependant" SG_ 93 TrnSecPrkStat_D_Actl 1;
BA_ "ContentDependant" SG_ 93 TrnNtrlTowCnfm_B_Actl 1;
BA_ "ContentDependant" SG_ 93 TrnGearFinalPos_B_Actl 1;
BA_ "MetaData" SG_ 93 TrnGearCnfm_No_Cs 1;
BA_ "ContentDependant" SG_ 93 TrnGearCnfm_No_Cs 1;
BA_ "MetaData" SG_ 93 TrnGearCnfm_No_Cnt 1;
BA_ "ContentDependant" SG_ 93 TrnGearCnfm_No_Cnt 1;
BA_ "ContentDependant" SG_ 93 TrnGear_D_Actl 1;
BA_ "U_U55X_MY2022_Rx" SG_ 90 TrnGsmNtmState_D_Actl 1;
BA_ "U_T6_MCA_MY2020_Rx" SG_ 90 TrnGsmNtmState_D_Actl 1;
BA_ "U_P702_MY2021_Rx" SG_ 90 TrnGsmNtmState_D_Actl 1;
BA_ "U_CD542_MY2021_Rx" SG_ 90 TrnGsmNtmState_D_Actl 1;
BA_ "U_CX727_MY2021_Rx" SG_ 90 TrnGsmNtmState_D_Actl 1;
BA_ "ContentDependant" SG_ 90 TrnGsmNtmState_D_Actl 1;
BA_ "U_U55X_MY2022_Rx" SG_ 90 DrQltyDrv_D_StatGsm 1;
BA_ "U_P702_MY2021_Rx" SG_ 90 DrQltyDrv_D_StatGsm 1;
BA_ "U_T6_MCA_MY2020_Rx" SG_ 90 DrQltyDrv_D_StatGsm 1;
BA_ "U_CD542_MY2021_Rx" SG_ 90 DrQltyDrv_D_StatGsm 1;
BA_ "U_CX727_MY2021_Rx" SG_ 90 DrQltyDrv_D_StatGsm 1;
BA_ "GenSigStartValue" SG_ 90 DrQltyDrv_D_StatGsm 6;
BA_ "ContentDependant" SG_ 90 DrQltyDrv_D_StatGsm 1;
BA_ "GenSigStartValueInteger" SG_ 90 DrQltyDrv_D_StatGsm 6;
BA_ "U_U55X_MY2022_Rx" SG_ 90 TrnBtsiOvrrd_B_Stat 1;
BA_ "U_P702_MY2021_Rx" SG_ 90 TrnBtsiOvrrd_B_Stat 1;
BA_ "U_T6_MCA_MY2020_Rx" SG_ 90 TrnBtsiOvrrd_B_Stat 1;
BA_ "U_CD542_MY2021_Rx" SG_ 90 TrnBtsiOvrrd_B_Stat 1;
BA_ "U_CX727_MY2021_Rx" SG_ 90 TrnBtsiOvrrd_B_Stat 1;
BA_ "ContentDependant" SG_ 90 TrnBtsiOvrrd_B_Stat 1;
BA_ "U_CD542_MY2021_Rx" SG_ 90 GsmGearMsgTxt_D_Rq 1;
BA_ "U_CX727_MY2021_Rx" SG_ 90 GsmGearMsgTxt_D_Rq 1;
BA_ "U_U55X_MY2022_Rx" SG_ 90 TrnRng_D_RqGsm 1;
BA_ "U_T6_MCA_MY2020_Rx" SG_ 90 TrnRng_D_RqGsm 1;
BA_ "U_P702_MY2021_Rx" SG_ 90 TrnRng_D_RqGsm 1;
BA_ "U_CD542_MY2021_Rx" SG_ 90 TrnRng_D_RqGsm 1;
BA_ "U_CX727_MY2021_Rx" SG_ 90 TrnRng_D_RqGsm 1;
BA_ "GenSigStartValue" SG_ 90 TrnRng_D_RqGsm 14;
BA_ "GenSigStartValueInteger" SG_ 90 TrnRng_D_RqGsm 14;
BA_ "U_U55X_MY2022_Rx" SG_ 90 PrkBrkActv_D_RqGsmGear 1;
BA_ "U_T6_MCA_MY2020_Rx" SG_ 90 PrkBrkActv_D_RqGsmGear 1;
BA_ "U_P702_MY2021_Rx" SG_ 90 PrkBrkActv_D_RqGsmGear 1;
BA_ "U_CD542_MY2021_Rx" SG_ 90 PrkBrkActv_D_RqGsmGear 1;
BA_ "U_CX727_MY2021_Rx" SG_ 90 PrkBrkActv_D_RqGsmGear 1;
BA_ "U_U55X_MY2022_Rx" SG_ 90 TrnValidGearRq_D_Stat 1;
BA_ "U_P702_MY2021_Rx" SG_ 90 TrnValidGearRq_D_Stat 1;
BA_ "U_T6_MCA_MY2020_Rx" SG_ 90 TrnValidGearRq_D_Stat 1;
BA_ "U_CD542_MY2021_Rx" SG_ 90 TrnValidGearRq_D_Stat 1;
BA_ "U_CX727_MY2021_Rx" SG_ 90 TrnValidGearRq_D_Stat 1;
BA_ "ContentDependant" SG_ 90 TrnValidGearRq_D_Stat 1;
BA_ "U_U55X_MY2022_Rx" SG_ 90 TrnGearRqCnt_B_Actl 1;
BA_ "U_P702_MY2021_Rx" SG_ 90 TrnGearRqCnt_B_Actl 1;
BA_ "U_T6_MCA_MY2020_Rx" SG_ 90 TrnGearRqCnt_B_Actl 1;
BA_ "U_CD542_MY2021_Rx" SG_ 90 TrnGearRqCnt_B_Actl 1;
BA_ "U_CX727_MY2021_Rx" SG_ 90 TrnGearRqCnt_B_Actl 1;
BA_ "ContentDependant" SG_ 90 TrnGearRqCnt_B_Actl 1;
BA_ "U_T6_MCA_MY2020_Rx" SG_ 90 TrnGearButtn_U_Actl 1;
BA_ "U_P702_MY2021_Rx" SG_ 90 TrnGearButtn_U_Actl 1;
BA_ "U_CD542_MY2021_Rx" SG_ 90 TrnGearButtn_U_Actl 1;
BA_ "U_CX727_MY2021_Rx" SG_ 90 TrnGearButtn_U_Actl 1;
BA_ "ContentDependant" SG_ 90 TrnGearButtn_U_Actl 1;
BA_ "WakeupSignal" SG_ 90 TrnGearButtn_U_Actl 1;
BA_ "U_U55X_MY2022_Rx" SG_ 90 TrnGearButtn_B_ActlR2 1;
BA_ "U_T6_MCA_MY2020_Rx" SG_ 90 TrnGearButtn_B_ActlR2 1;
BA_ "U_P702_MY2021_Rx" SG_ 90 TrnGearButtn_B_ActlR2 1;
BA_ "U_CD542_MY2021_Rx" SG_ 90 TrnGearButtn_B_ActlR2 1;
BA_ "U_CX727_MY2021_Rx" SG_ 90 TrnGearButtn_B_ActlR2 1;
BA_ "ContentDependant" SG_ 90 TrnGearButtn_B_ActlR2 1;
BA_ "WakeupSignal" SG_ 90 TrnGearButtn_B_ActlR2 1;
BA_ "U_U55X_MY2022_Rx" SG_ 90 TrnGearButtn_B_ActlR1 1;
BA_ "U_T6_MCA_MY2020_Rx" SG_ 90 TrnGearButtn_B_ActlR1 1;
BA_ "U_P702_MY2021_Rx" SG_ 90 TrnGearButtn_B_ActlR1 1;
BA_ "U_CD542_MY2021_Rx" SG_ 90 TrnGearButtn_B_ActlR1 1;
BA_ "U_CX727_MY2021_Rx" SG_ 90 TrnGearButtn_B_ActlR1 1;
BA_ "ContentDependant" SG_ 90 TrnGearButtn_B_ActlR1 1;
BA_ "WakeupSignal" SG_ 90 TrnGearButtn_B_ActlR1 1;
BA_ "U_U55X_MY2022_Rx" SG_ 90 TrnGearButtn_B_ActlR0 1;
BA_ "U_T6_MCA_MY2020_Rx" SG_ 90 TrnGearButtn_B_ActlR0 1;
BA_ "U_P702_MY2021_Rx" SG_ 90 TrnGearButtn_B_ActlR0 1;
BA_ "U_CD542_MY2021_Rx" SG_ 90 TrnGearButtn_B_ActlR0 1;
BA_ "U_CX727_MY2021_Rx" SG_ 90 TrnGearButtn_B_ActlR0 1;
BA_ "ContentDependant" SG_ 90 TrnGearButtn_B_ActlR0 1;
BA_ "WakeupSignal" SG_ 90 TrnGearButtn_B_ActlR0 1;
BA_ "U_U55X_MY2022_Rx" SG_ 90 TrnGearButtn_B_ActlP2 1;
BA_ "U_T6_MCA_MY2020_Rx" SG_ 90 TrnGearButtn_B_ActlP2 1;
BA_ "U_P702_MY2021_Rx" SG_ 90 TrnGearButtn_B_ActlP2 1;
BA_ "U_CD542_MY2021_Rx" SG_ 90 TrnGearButtn_B_ActlP2 1;
BA_ "U_CX727_MY2021_Rx" SG_ 90 TrnGearButtn_B_ActlP2 1;
BA_ "ContentDependant" SG_ 90 TrnGearButtn_B_ActlP2 1;
BA_ "WakeupSignal" SG_ 90 TrnGearButtn_B_ActlP2 1;
BA_ "U_U55X_MY2022_Rx" SG_ 90 TrnGearButtn_B_ActlP1 1;
BA_ "U_T6_MCA_MY2020_Rx" SG_ 90 TrnGearButtn_B_ActlP1 1;
BA_ "U_P702_MY2021_Rx" SG_ 90 TrnGearButtn_B_ActlP1 1;
BA_ "U_CD542_MY2021_Rx" SG_ 90 TrnGearButtn_B_ActlP1 1;
BA_ "U_CX727_MY2021_Rx" SG_ 90 TrnGearButtn_B_ActlP1 1;
BA_ "ContentDependant" SG_ 90 TrnGearButtn_B_ActlP1 1;
BA_ "WakeupSignal" SG_ 90 TrnGearButtn_B_ActlP1 1;
BA_ "U_U55X_MY2022_Rx" SG_ 90 TrnGearButtn_B_ActlP0 1;
BA_ "U_T6_MCA_MY2020_Rx" SG_ 90 TrnGearButtn_B_ActlP0 1;
BA_ "U_P702_MY2021_Rx" SG_ 90 TrnGearButtn_B_ActlP0 1;
BA_ "U_CD542_MY2021_Rx" SG_ 90 TrnGearButtn_B_ActlP0 1;
BA_ "U_CX727_MY2021_Rx" SG_ 90 TrnGearButtn_B_ActlP0 1;
BA_ "ContentDependant" SG_ 90 TrnGearButtn_B_ActlP0 1;
BA_ "WakeupSignal" SG_ 90 TrnGearButtn_B_ActlP0 1;
BA_ "U_U55X_MY2022_Rx" SG_ 90 TrnGearButtn_B_ActlN2 1;
BA_ "U_T6_MCA_MY2020_Rx" SG_ 90 TrnGearButtn_B_ActlN2 1;
BA_ "U_P702_MY2021_Rx" SG_ 90 TrnGearButtn_B_ActlN2 1;
BA_ "U_CD542_MY2021_Rx" SG_ 90 TrnGearButtn_B_ActlN2 1;
BA_ "U_CX727_MY2021_Rx" SG_ 90 TrnGearButtn_B_ActlN2 1;
BA_ "ContentDependant" SG_ 90 TrnGearButtn_B_ActlN2 1;
BA_ "WakeupSignal" SG_ 90 TrnGearButtn_B_ActlN2 1;
BA_ "U_U55X_MY2022_Rx" SG_ 90 TrnGearButtn_B_ActlN1 1;
BA_ "U_T6_MCA_MY2020_Rx" SG_ 90 TrnGearButtn_B_ActlN1 1;
BA_ "U_P702_MY2021_Rx" SG_ 90 TrnGearButtn_B_ActlN1 1;
BA_ "U_CD542_MY2021_Rx" SG_ 90 TrnGearButtn_B_ActlN1 1;
BA_ "U_CX727_MY2021_Rx" SG_ 90 TrnGearButtn_B_ActlN1 1;
BA_ "ContentDependant" SG_ 90 TrnGearButtn_B_ActlN1 1;
BA_ "WakeupSignal" SG_ 90 TrnGearButtn_B_ActlN1 1;
BA_ "U_U55X_MY2022_Rx" SG_ 90 TrnGearButtn_B_ActlN0 1;
BA_ "U_T6_MCA_MY2020_Rx" SG_ 90 TrnGearButtn_B_ActlN0 1;
BA_ "U_P702_MY2021_Rx" SG_ 90 TrnGearButtn_B_ActlN0 1;
BA_ "U_CD542_MY2021_Rx" SG_ 90 TrnGearButtn_B_ActlN0 1;
BA_ "U_CX727_MY2021_Rx" SG_ 90 TrnGearButtn_B_ActlN0 1;
BA_ "ContentDependant" SG_ 90 TrnGearButtn_B_ActlN0 1;
BA_ "WakeupSignal" SG_ 90 TrnGearButtn_B_ActlN0 1;
BA_ "U_U55X_MY2022_Rx" SG_ 90 TrnGearButtn_B_ActlM2 1;
BA_ "U_T6_MCA_MY2020_Rx" SG_ 90 TrnGearButtn_B_ActlM2 1;
BA_ "U_P702_MY2021_Rx" SG_ 90 TrnGearButtn_B_ActlM2 1;
BA_ "U_CD542_MY2021_Rx" SG_ 90 TrnGearButtn_B_ActlM2 1;
BA_ "U_CX727_MY2021_Rx" SG_ 90 TrnGearButtn_B_ActlM2 1;
BA_ "ContentDependant" SG_ 90 TrnGearButtn_B_ActlM2 1;
BA_ "WakeupSignal" SG_ 90 TrnGearButtn_B_ActlM2 1;
BA_ "U_U55X_MY2022_Rx" SG_ 90 TrnGearButtn_B_ActlM1 1;
BA_ "U_T6_MCA_MY2020_Rx" SG_ 90 TrnGearButtn_B_ActlM1 1;
BA_ "U_P702_MY2021_Rx" SG_ 90 TrnGearButtn_B_ActlM1 1;
BA_ "U_CD542_MY2021_Rx" SG_ 90 TrnGearButtn_B_ActlM1 1;
BA_ "U_CX727_MY2021_Rx" SG_ 90 TrnGearButtn_B_ActlM1 1;
BA_ "ContentDependant" SG_ 90 TrnGearButtn_B_ActlM1 1;
BA_ "WakeupSignal" SG_ 90 TrnGearButtn_B_ActlM1 1;
BA_ "U_U55X_MY2022_Rx" SG_ 90 TrnGearButtn_B_ActlM0 1;
BA_ "U_T6_MCA_MY2020_Rx" SG_ 90 TrnGearButtn_B_ActlM0 1;
BA_ "U_P702_MY2021_Rx" SG_ 90 TrnGearButtn_B_ActlM0 1;
BA_ "U_CD542_MY2021_Rx" SG_ 90 TrnGearButtn_B_ActlM0 1;
BA_ "U_CX727_MY2021_Rx" SG_ 90 TrnGearButtn_B_ActlM0 1;
BA_ "ContentDependant" SG_ 90 TrnGearButtn_B_ActlM0 1;
BA_ "WakeupSignal" SG_ 90 TrnGearButtn_B_ActlM0 1;
BA_ "U_U55X_MY2022_Rx" SG_ 90 TrnGearButtn_B_ActlD2 1;
BA_ "U_T6_MCA_MY2020_Rx" SG_ 90 TrnGearButtn_B_ActlD2 1;
BA_ "U_P702_MY2021_Rx" SG_ 90 TrnGearButtn_B_ActlD2 1;
BA_ "U_CD542_MY2021_Rx" SG_ 90 TrnGearButtn_B_ActlD2 1;
BA_ "U_CX727_MY2021_Rx" SG_ 90 TrnGearButtn_B_ActlD2 1;
BA_ "ContentDependant" SG_ 90 TrnGearButtn_B_ActlD2 1;
BA_ "WakeupSignal" SG_ 90 TrnGearButtn_B_ActlD2 1;
BA_ "U_U55X_MY2022_Rx" SG_ 90 TrnGearButtn_B_ActlD1 1;
BA_ "U_T6_MCA_MY2020_Rx" SG_ 90 TrnGearButtn_B_ActlD1 1;
BA_ "U_P702_MY2021_Rx" SG_ 90 TrnGearButtn_B_ActlD1 1;
BA_ "U_CD542_MY2021_Rx" SG_ 90 TrnGearButtn_B_ActlD1 1;
BA_ "U_CX727_MY2021_Rx" SG_ 90 TrnGearButtn_B_ActlD1 1;
BA_ "ContentDependant" SG_ 90 TrnGearButtn_B_ActlD1 1;
BA_ "WakeupSignal" SG_ 90 TrnGearButtn_B_ActlD1 1;
BA_ "U_U55X_MY2022_Rx" SG_ 90 TrnGearButtn_B_ActlD0 1;
BA_ "U_T6_MCA_MY2020_Rx" SG_ 90 TrnGearButtn_B_ActlD0 1;
BA_ "U_P702_MY2021_Rx" SG_ 90 TrnGearButtn_B_ActlD0 1;
BA_ "U_CD542_MY2021_Rx" SG_ 90 TrnGearButtn_B_ActlD0 1;
BA_ "U_CX727_MY2021_Rx" SG_ 90 TrnGearButtn_B_ActlD0 1;
BA_ "ContentDependant" SG_ 90 TrnGearButtn_B_ActlD0 1;
BA_ "WakeupSignal" SG_ 90 TrnGearButtn_B_ActlD0 1;
BA_ "U_U55X_MY2022_Rx" SG_ 90 TrnGear_No_Cs 1;
BA_ "U_T6_MCA_MY2020_Rx" SG_ 90 TrnGear_No_Cs 1;
BA_ "U_CD542_MY2021_Rx" SG_ 90 TrnGear_No_Cs 1;
BA_ "U_P702_MY2021_Rx" SG_ 90 TrnGear_No_Cs 1;
BA_ "U_CX727_MY2021_Rx" SG_ 90 TrnGear_No_Cs 1;
BA_ "MetaData" SG_ 90 TrnGear_No_Cs 1;
BA_ "ContentDependant" SG_ 90 TrnGear_No_Cs 1;
BA_ "U_U55X_MY2022_Rx" SG_ 90 TrnGear_No_Cnt 1;
BA_ "U_T6_MCA_MY2020_Rx" SG_ 90 TrnGear_No_Cnt 1;
BA_ "U_CD542_MY2021_Rx" SG_ 90 TrnGear_No_Cnt 1;
BA_ "U_P702_MY2021_Rx" SG_ 90 TrnGear_No_Cnt 1;
BA_ "U_CX727_MY2021_Rx" SG_ 90 TrnGear_No_Cnt 1;
BA_ "MetaData" SG_ 90 TrnGear_No_Cnt 1;
BA_ "ContentDependant" SG_ 90 TrnGear_No_Cnt 1;
BA_ "U_U55X_MY2022_Rx" SG_ 90 TrnGear_D_RqDrv 1;
BA_ "U_T6_MCA_MY2020_Rx" SG_ 90 TrnGear_D_RqDrv 1;
BA_ "U_CD542_MY2021_Rx" SG_ 90 TrnGear_D_RqDrv 1;
BA_ "U_P702_MY2021_Rx" SG_ 90 TrnGear_D_RqDrv 1;
BA_ "U_CX727_MY2021_Rx" SG_ 90 TrnGear_D_RqDrv 1;
BA_ "ContentDependant" SG_ 90 TrnGear_D_RqDrv 1;
BA_ "WakeupSignal" SG_ 90 TrnGear_D_RqDrv 1;
BA_ "U_U55X_MY2022_Rx" SG_ 90 BrkSwtchPos_B_ActlGsm 1;
BA_ "U_P702_MY2021_Rx" SG_ 90 BrkSwtchPos_B_ActlGsm 1;
BA_ "U_T6_MCA_MY2020_Rx" SG_ 90 BrkSwtchPos_B_ActlGsm 1;
BA_ "U_CD542_MY2021_Rx" SG_ 90 BrkSwtchPos_B_ActlGsm 1;
BA_ "U_CX727_MY2021_Rx" SG_ 90 BrkSwtchPos_B_ActlGsm 1;
BA_ "ContentDependant" SG_ 90 BrkSwtchPos_B_ActlGsm 1;
BA_ "U_U55X_MY2022_Rx" SG_ 1114 TrailCtlSwtch_B_Stat2 1;
BA_ "U_T6_MCA_MY2020_Rx" SG_ 1114 TrailCtlSwtch_B_Stat2 1;
BA_ "U_P702_MY2021_Rx" SG_ 1114 TrailCtlSwtch_B_Stat2 1;
BA_ "U_CD542_MY2021_Rx" SG_ 1111 TrlrYawWActl_D_Qf 1;
BA_ "U_T6_MCA_MY2020_Rx" SG_ 1111 TrlrYawWActl_D_Qf 1;
BA_ "U_P702_MY2021_Rx" SG_ 1111 TrlrYawWActl_D_Qf 1;
BA_ "GenSigStartValue" SG_ 1111 TrlrYawWActl_D_Qf 1;
BA_ "MetaData" SG_ 1111 TrlrYawWActl_D_Qf 1;
BA_ "GenSigStartValueInteger" SG_ 1111 TrlrYawWActl_D_Qf 1;
BA_ "U_CD542_MY2021_Rx" SG_ 1111 TrlrYaw_W_Actl 1;
BA_ "U_T6_MCA_MY2020_Rx" SG_ 1111 TrlrYaw_W_Actl 1;
BA_ "U_P702_MY2021_Rx" SG_ 1111 TrlrYaw_W_Actl 1;
BA_ "GenSigStartValue" SG_ 1111 TrlrYaw_W_Actl 65534;
BA_ "GenSigStartValueInteger" SG_ 1111 TrlrYaw_W_Actl 65534;
BA_ "U_CD542_MY2021_Rx" SG_ 1111 TrlrHitYaw_AnRate_Actl 1;
BA_ "U_T6_MCA_MY2020_Rx" SG_ 1111 TrlrHitYaw_AnRate_Actl 1;
BA_ "U_P702_MY2021_Rx" SG_ 1111 TrlrHitYaw_AnRate_Actl 1;
BA_ "GenSigStartValue" SG_ 1111 TrlrHitYaw_AnRate_Actl 4093;
BA_ "GenSigStartValueInteger" SG_ 1111 TrlrHitYaw_AnRate_Actl 4094;
BA_ "U_CD542_MY2021_Rx" SG_ 1111 TrlrHitchYaw_D_Stat 1;
BA_ "U_T6_MCA_MY2020_Rx" SG_ 1111 TrlrHitchYaw_D_Stat 1;
BA_ "U_P702_MY2021_Rx" SG_ 1111 TrlrHitchYaw_D_Stat 1;
BA_ "U_CD542_MY2021_Rx" SG_ 1111 TrlrHitchYaw_An_Actl 1;
BA_ "U_T6_MCA_MY2020_Rx" SG_ 1111 TrlrHitchYaw_An_Actl 1;
BA_ "U_P702_MY2021_Rx" SG_ 1111 TrlrHitchYaw_An_Actl 1;
BA_ "GenSigStartValue" SG_ 1111 TrlrHitchYaw_An_Actl 4093;
BA_ "GenSigStartValueInteger" SG_ 1111 TrlrHitchYaw_An_Actl 4094;
BA_ "U_P702_MY2021_Rx" SG_ 1106 TrlrSnsId_No_Actl 1;
BA_ "U_CD542_MY2021_Rx" SG_ 1106 TrlrSnsId_No_Actl 1;
BA_ "U_T6_MCA_MY2020_Rx" SG_ 1106 TrlrSnsId_No_Actl 1;
BA_ "ContentDependant" SG_ 1091 PoliceAux4Lamp_B_Rq2 1;
BA_ "ContentDependant" SG_ 1091 PoliceAux3Lamp_B_Rq2 1;
BA_ "ContentDependant" SG_ 1091 PoliceAux2Lamp_B_Rq2 1;
BA_ "ContentDependant" SG_ 1091 PoliceAux1Lamp_B_Rq2 1;
BA_ "U_U55X_MY2022_Rx" SG_ 1091 TrlrLampCnnct_B_Actl 1;
BA_ "U_CX727_MY2021_Rx" SG_ 1091 TrlrLampCnnct_B_Actl 1;
BA_ "U_CD542_MY2021_Rx" SG_ 1091 TrlrLampCnnct_B_Actl 1;
BA_ "U_T6_MCA_MY2020_Rx" SG_ 1091 TrlrLampCnnct_B_Actl 1;
BA_ "U_P702_MY2021_Rx" SG_ 1091 TrlrLampCnnct_B_Actl 1;
BA_ "U_P702_MY2021_Rx" SG_ 138 SteWhlRelCalib_T_Actl 1;
BA_ "U_CD542_MY2021_Rx" SG_ 138 SteWhlRelCalib_An_Sns 1;
BA_ "U_CX727_MY2021_Rx" SG_ 138 SteWhlRelCalib_An_Sns 1;
BA_ "U_P702_MY2021_Rx" SG_ 138 SteWhlRelCalib_An_Sns 1;
BA_ "U_T6_MCA_MY2020_Rx" SG_ 138 SteWhlRelCalib_An_Sns 1;
BA_ "ContentDependant" SG_ 138 SteWhlRelCalib_An_Sns 1;
BA_ "U_P702_MY2021_Rx" SG_ 131 HeadLghtHiCtrl_D_RqAhb 1;
BA_ "U_CX727_MY2021_Rx" SG_ 131 HeadLghtHiCtrl_D_RqAhb 1;
BA_ "WakeupSignal" SG_ 131 HeadLghtHiCtrl_D_RqAhb 1;
BA_ "GenSigStartValue" SG_ 131 WiprFrontSwtch_D_Stat 9;
BA_ "GenSigStartValueInteger" SG_ 131 WiprFrontSwtch_D_Stat 9;
BA_ "U_CD542_MY2021_Rx" SG_ 131 HeadLghtHiOn_B_StatAhb 1;
BA_ "U_T6_MCA_MY2020_Rx" SG_ 131 HeadLghtHiOn_B_StatAhb 1;
BA_ "WakeupSignal" SG_ 131 HeadLghtHiOn_B_StatAhb 1;
BA_ "U_CD542_MY2021_Rx" SG_ 131 HeadLghtHiFlash_D_Actl 1;
BA_ "U_T6_MCA_MY2020_Rx" SG_ 131 HeadLghtHiFlash_D_Actl 1;
BA_ "U_CD542_MY2021_Rx" SG_ 131 TjaButtnOnOffPress 1;
BA_ "U_T6_MCA_MY2020_Rx" SG_ 131 TjaButtnOnOffPress 1;
BA_ "U_CD542_MY2021_Rx" SG_ 131 AccButtnGapTogglePress 1;
BA_ "U_T6_MCA_MY2020_Rx" SG_ 131 AccButtnGapTogglePress 1;
BA_ "U_CX727_MY2021_Rx" SG_ 131 WiprFront_D_Stat 1;
BA_ "U_U55X_MY2022_Rx" SG_ 131 WiprFront_D_Stat 1;
BA_ "U_CD542_MY2021_Rx" SG_ 131 WiprFront_D_Stat 1;
BA_ "U_T6_MCA_MY2020_Rx" SG_ 131 WiprFront_D_Stat 1;
BA_ "U_P702_MY2021_Rx" SG_ 131 WiprFront_D_Stat 1;
BA_ "GenSigStartValue" SG_ 131 WiprFront_D_Stat 15;
BA_ "GenSigStartValueInteger" SG_ 131 WiprFront_D_Stat 15;
BA_ "U_CD542_MY2021_Rx" SG_ 131 TurnLghtSwtch_D_Stat 1;
BA_ "U_T6_MCA_MY2020_Rx" SG_ 131 TurnLghtSwtch_D_Stat 1;
BA_ "U_P702_MY2021_Rx" SG_ 131 TurnLghtSwtch_D_Stat 1;
BA_ "U_CX727_MY2021_Rx" SG_ 131 TurnLghtSwtch_D_Stat 1;
BA_ "WakeupSignal" SG_ 131 TurnLghtSwtch_D_Stat 1;
BA_ "U_P702_MY2021_Rx" SG_ 131 LghtAmb_D_Sns 1;
BA_ "U_CX727_MY2021_Rx" SG_ 131 LghtAmb_D_Sns 1;
BA_ "U_CD542_MY2021_Rx" SG_ 131 LghtAmb_D_Sns 1;
BA_ "U_T6_MCA_MY2020_Rx" SG_ 131 LghtAmb_D_Sns 1;
BA_ "GenSigStartValue" SG_ 131 LghtAmb_D_Sns 7;
BA_ "GenSigStartValueInteger" SG_ 131 LghtAmb_D_Sns 7;
BA_ "U_CD542_MY2021_Rx" SG_ 131 AccButtnGapIncPress 1;
BA_ "U_T6_MCA_MY2020_Rx" SG_ 131 AccButtnGapIncPress 1;
BA_ "U_CD542_MY2021_Rx" SG_ 131 AccButtnGapDecPress 1;
BA_ "U_T6_MCA_MY2020_Rx" SG_ 131 AccButtnGapDecPress 1;
BA_ "U_CX727_MY2021_Rx" SG_ 131 AslButtnOnOffPress 1;
BA_ "U_U55X_MY2022_Rx" SG_ 131 AslButtnOnOffPress 1;
BA_ "U_CD542_MY2021_Rx" SG_ 131 AslButtnOnOffPress 1;
BA_ "U_T6_MCA_MY2020_Rx" SG_ 131 AslButtnOnOffPress 1;
BA_ "U_P702_MY2021_Rx" SG_ 131 AslButtnOnOffPress 1;
BA_ "U_CX727_MY2021_Rx" SG_ 131 AslButtnOnOffCnclPress 1;
BA_ "U_U55X_MY2022_Rx" SG_ 131 AslButtnOnOffCnclPress 1;
BA_ "U_CD542_MY2021_Rx" SG_ 131 AslButtnOnOffCnclPress 1;
BA_ "U_T6_MCA_MY2020_Rx" SG_ 131 AslButtnOnOffCnclPress 1;
BA_ "U_P702_MY2021_Rx" SG_ 131 AslButtnOnOffCnclPress 1;
BA_ "U_CX727_MY2021_Rx" SG_ 131 CcButtnOnPress 1;
BA_ "U_U55X_MY2022_Rx" SG_ 131 CcButtnOnPress 1;
BA_ "U_CD542_MY2021_Rx" SG_ 131 CcButtnOnPress 1;
BA_ "U_T6_MCA_MY2020_Rx" SG_ 131 CcButtnOnPress 1;
BA_ "U_P702_MY2021_Rx" SG_ 131 CcButtnOnPress 1;
BA_ "U_CX727_MY2021_Rx" SG_ 131 CcButtnOnOffPress 1;
BA_ "U_U55X_MY2022_Rx" SG_ 131 CcButtnOnOffPress 1;
BA_ "U_CD542_MY2021_Rx" SG_ 131 CcButtnOnOffPress 1;
BA_ "U_T6_MCA_MY2020_Rx" SG_ 131 CcButtnOnOffPress 1;
BA_ "U_P702_MY2021_Rx" SG_ 131 CcButtnOnOffPress 1;
BA_ "U_CX727_MY2021_Rx" SG_ 131 CcButtnOnOffCnclPress 1;
BA_ "U_U55X_MY2022_Rx" SG_ 131 CcButtnOnOffCnclPress 1;
BA_ "U_CD542_MY2021_Rx" SG_ 131 CcButtnOnOffCnclPress 1;
BA_ "U_T6_MCA_MY2020_Rx" SG_ 131 CcButtnOnOffCnclPress 1;
BA_ "U_P702_MY2021_Rx" SG_ 131 CcButtnOnOffCnclPress 1;
BA_ "U_CX727_MY2021_Rx" SG_ 131 CcButtnOffPress 1;
BA_ "U_U55X_MY2022_Rx" SG_ 131 CcButtnOffPress 1;
BA_ "U_CD542_MY2021_Rx" SG_ 131 CcButtnOffPress 1;
BA_ "U_T6_MCA_MY2020_Rx" SG_ 131 CcButtnOffPress 1;
BA_ "U_P702_MY2021_Rx" SG_ 131 CcButtnOffPress 1;
BA_ "U_CX727_MY2021_Rx" SG_ 131 CcAsllButtnResPress 1;
BA_ "U_U55X_MY2022_Rx" SG_ 131 CcAsllButtnResPress 1;
BA_ "U_CD542_MY2021_Rx" SG_ 131 CcAsllButtnResPress 1;
BA_ "U_T6_MCA_MY2020_Rx" SG_ 131 CcAsllButtnResPress 1;
BA_ "U_P702_MY2021_Rx" SG_ 131 CcAsllButtnResPress 1;
BA_ "U_CD542_MY2021_Rx" SG_ 131 CcAslButtnSetPress 1;
BA_ "U_CX727_MY2021_Rx" SG_ 131 CcAslButtnSetIncPress 1;
BA_ "U_U55X_MY2022_Rx" SG_ 131 CcAslButtnSetIncPress 1;
BA_ "U_CD542_MY2021_Rx" SG_ 131 CcAslButtnSetIncPress 1;
BA_ "U_T6_MCA_MY2020_Rx" SG_ 131 CcAslButtnSetIncPress 1;
BA_ "U_P702_MY2021_Rx" SG_ 131 CcAslButtnSetIncPress 1;
BA_ "U_CX727_MY2021_Rx" SG_ 131 CcAslButtnSetDecPress 1;
BA_ "U_U55X_MY2022_Rx" SG_ 131 CcAslButtnSetDecPress 1;
BA_ "U_CD542_MY2021_Rx" SG_ 131 CcAslButtnSetDecPress 1;
BA_ "U_T6_MCA_MY2020_Rx" SG_ 131 CcAslButtnSetDecPress 1;
BA_ "U_P702_MY2021_Rx" SG_ 131 CcAslButtnSetDecPress 1;
BA_ "U_CX727_MY2021_Rx" SG_ 131 CcAslButtnResIncPress 1;
BA_ "U_U55X_MY2022_Rx" SG_ 131 CcAslButtnResIncPress 1;
BA_ "U_CD542_MY2021_Rx" SG_ 131 CcAslButtnResIncPress 1;
BA_ "U_T6_MCA_MY2020_Rx" SG_ 131 CcAslButtnResIncPress 1;
BA_ "U_P702_MY2021_Rx" SG_ 131 CcAslButtnResIncPress 1;
BA_ "U_U55X_MY2022_Rx" SG_ 131 CcAslButtnResDecPress 1;
BA_ "U_CX727_MY2021_Rx" SG_ 131 CcAslButtnOnPress 1;
BA_ "U_U55X_MY2022_Rx" SG_ 131 CcAslButtnOnPress 1;
BA_ "U_CD542_MY2021_Rx" SG_ 131 CcAslButtnOnPress 1;
BA_ "U_T6_MCA_MY2020_Rx" SG_ 131 CcAslButtnOnPress 1;
BA_ "U_P702_MY2021_Rx" SG_ 131 CcAslButtnOnPress 1;
BA_ "U_CX727_MY2021_Rx" SG_ 131 CcAslButtnIndxIncPress 1;
BA_ "U_U55X_MY2022_Rx" SG_ 131 CcAslButtnIndxIncPress 1;
BA_ "U_CD542_MY2021_Rx" SG_ 131 CcAslButtnIndxIncPress 1;
BA_ "U_T6_MCA_MY2020_Rx" SG_ 131 CcAslButtnIndxIncPress 1;
BA_ "U_P702_MY2021_Rx" SG_ 131 CcAslButtnIndxIncPress 1;
BA_ "U_CX727_MY2021_Rx" SG_ 131 CcAslButtnIndxDecPress 1;
BA_ "U_U55X_MY2022_Rx" SG_ 131 CcAslButtnIndxDecPress 1;
BA_ "U_CD542_MY2021_Rx" SG_ 131 CcAslButtnIndxDecPress 1;
BA_ "U_T6_MCA_MY2020_Rx" SG_ 131 CcAslButtnIndxDecPress 1;
BA_ "U_P702_MY2021_Rx" SG_ 131 CcAslButtnIndxDecPress 1;
BA_ "U_CX727_MY2021_Rx" SG_ 131 CcAslButtnDeny_B_Actl 1;
BA_ "U_U55X_MY2022_Rx" SG_ 131 CcAslButtnDeny_B_Actl 1;
BA_ "U_CD542_MY2021_Rx" SG_ 131 CcAslButtnDeny_B_Actl 1;
BA_ "U_T6_MCA_MY2020_Rx" SG_ 131 CcAslButtnDeny_B_Actl 1;
BA_ "U_P702_MY2021_Rx" SG_ 131 CcAslButtnDeny_B_Actl 1;
BA_ "U_CX727_MY2021_Rx" SG_ 131 CcAslButtnCnclResPress 1;
BA_ "U_U55X_MY2022_Rx" SG_ 131 CcAslButtnCnclResPress 1;
BA_ "U_CD542_MY2021_Rx" SG_ 131 CcAslButtnCnclResPress 1;
BA_ "U_T6_MCA_MY2020_Rx" SG_ 131 CcAslButtnCnclResPress 1;
BA_ "U_P702_MY2021_Rx" SG_ 131 CcAslButtnCnclResPress 1;
BA_ "U_CX727_MY2021_Rx" SG_ 131 CcAslButtnCnclPress 1;
BA_ "U_U55X_MY2022_Rx" SG_ 131 CcAslButtnCnclPress 1;
BA_ "U_CD542_MY2021_Rx" SG_ 131 CcAslButtnCnclPress 1;
BA_ "U_T6_MCA_MY2020_Rx" SG_ 131 CcAslButtnCnclPress 1;
BA_ "U_P702_MY2021_Rx" SG_ 131 CcAslButtnCnclPress 1;
BA_ "U_CD542_MY2021_Rx" SG_ 131 LaSwtchPos_D_Stat 1;
BA_ "U_T6_MCA_MY2020_Rx" SG_ 131 LaSwtchPos_D_Stat 1;
BA_ "WakeupSignal" SG_ 131 HeadLghtHiFlash_D_Stat 1;
BA_ "WakeupSignal" SG_ 787 DrLckCnt_No_ActlTgate 1;
BA_ "WakeupSignal" SG_ 787 DrTgateChime2_D_Rq 1;
BA_ "U_T6_MCA_MY2020_Rx" SG_ 787 DrTGate_D_Rq 1;
BA_ "U_P702_MY2021_Rx" SG_ 787 DrTGate_D_Rq 1;
BA_ "WakeupSignal" SG_ 787 DrTGate_D_Rq 1;
BA_ "WakeupSignal" SG_ 787 PwLftgtIntSw_B_Stat 1;
BA_ "U_T6_MCA_MY2020_Tx" SG_ 570 SuspClkSync_No_Rq 1;
BA_ "U_T6_MCA_MY2020_Tx" SG_ 570 SuspRearRight_L_Actl 1;
BA_ "U_CX727_MY2021_Rx" SG_ 570 SuspRearRight_L_Actl 1;
BA_ "GenSigStartValue" SG_ 570 SuspRearRight_L_Actl 511;
BA_ "GenSigStartValueInteger" SG_ 570 SuspRearRight_L_Actl 511;
BA_ "U_T6_MCA_MY2020_Tx" SG_ 570 SuspFrntRight_L_Actl 1;
BA_ "U_CX727_MY2021_Rx" SG_ 570 SuspFrntRight_L_Actl 1;
BA_ "GenSigStartValue" SG_ 570 SuspFrntRight_L_Actl 511;
BA_ "GenSigStartValueInteger" SG_ 570 SuspFrntRight_L_Actl 511;
BA_ "U_T6_MCA_MY2020_Tx" SG_ 570 SuspRear_L_Prev 1;
BA_ "U_P702_MY2021_Rx" SG_ 570 SuspRear_L_Prev 1;
BA_ "U_CX727_MY2021_Rx" SG_ 570 SuspRear_L_Prev 1;
BA_ "GenSigStartValue" SG_ 570 SuspRear_L_Prev 511;
BA_ "GenSigStartValueInteger" SG_ 570 SuspRear_L_Prev 511;
BA_ "U_T6_MCA_MY2020_Tx" SG_ 570 SuspRear_L_Actl 1;
BA_ "U_P702_MY2021_Rx" SG_ 570 SuspRear_L_Actl 1;
BA_ "U_CX727_MY2021_Rx" SG_ 570 SuspRear_L_Actl 1;
BA_ "GenSigStartValue" SG_ 570 SuspRear_L_Actl 511;
BA_ "GenSigStartValueInteger" SG_ 570 SuspRear_L_Actl 511;
BA_ "U_T6_MCA_MY2020_Tx" SG_ 570 SuspFrnt_L_Prev 1;
BA_ "U_P702_MY2021_Rx" SG_ 570 SuspFrnt_L_Prev 1;
BA_ "U_CX727_MY2021_Rx" SG_ 570 SuspFrnt_L_Prev 1;
BA_ "GenSigStartValue" SG_ 570 SuspFrnt_L_Prev 511;
BA_ "GenSigStartValueInteger" SG_ 570 SuspFrnt_L_Prev 511;
BA_ "U_T6_MCA_MY2020_Tx" SG_ 570 SuspFrnt_L_Actl 1;
BA_ "U_P702_MY2021_Rx" SG_ 570 SuspFrnt_L_Actl 1;
BA_ "U_CX727_MY2021_Rx" SG_ 570 SuspFrnt_L_Actl 1;
BA_ "GenSigStartValue" SG_ 570 SuspFrnt_L_Actl 511;
BA_ "GenSigStartValueInteger" SG_ 570 SuspFrnt_L_Actl 511;
BA_ "GenSigStartValue" SG_ 953 WakeAlarm3_D_Stat 3;
BA_ "GenSigStartValueInteger" SG_ 953 WakeAlarm3_D_Stat 3;
BA_ "GenSigStartValue" SG_ 953 WakeAlarm2_D_Stat 3;
BA_ "GenSigStartValueInteger" SG_ 953 WakeAlarm2_D_Stat 3;
BA_ "U_T6_MCA_MY2020_Rx" SG_ 953 WakeAlarm1_D_Stat 1;
BA_ "U_CD542_MY2021_Rx" SG_ 953 WakeAlarm1_D_Stat 1;
BA_ "U_CX727_MY2021_Rx" SG_ 953 WakeAlarm1_D_Stat 1;
BA_ "U_P702_MY2021_Rx" SG_ 953 WakeAlarm1_D_Stat 1;
BA_ "GenSigStartValue" SG_ 953 WakeAlarm1_D_Stat 3;
BA_ "GenSigStartValueInteger" SG_ 953 WakeAlarm1_D_Stat 3;
BA_ "U_CD542_MY2021_Rx" SG_ 953 WakeAlarm0_D_Stat 1;
BA_ "U_CX727_MY2021_Rx" SG_ 953 WakeAlarm0_D_Stat 1;
BA_ "GenSigStartValue" SG_ 953 WakeAlarm0_D_Stat 3;
BA_ "GenSigStartValueInteger" SG_ 953 WakeAlarm0_D_Stat 3;
BA_ "GenSigStartValue" SG_ 953 BattRgenLoSoc_Pc_LimLo 30;
BA_ "GenSigStartValueInteger" SG_ 953 BattRgenLoSoc_Pc_LimLo 30;
BA_ "U_T6_MCA_MY2020_Rx" SG_ 953 BattRgenLoChrg_D_Rq 1;
BA_ "U_P702_MY2021_Rx" SG_ 953 BattRgenLoChrg_D_Rq 1;
BA_ "U_T6_MCA_MY2020_Rx" SG_ 953 BattRgenLoDChrg_D_Rq 1;
BA_ "U_P702_MY2021_Rx" SG_ 953 BattRgenLoDChrg_D_Rq 1;
BA_ "U_T6_MCA_MY2020_Tx" SG_ 1101 AwdLckLamp_D_Rq 1;
BA_ "GenSigSendType" SG_ 1101 AwdLckLamp_D_Rq 3;
BA_ "U_T6_MCA_MY2020_Tx" SG_ 1101 Ptu_Te_Actl 1;
BA_ "U_T6_MCA_MY2020_Rx" SG_ 1101 Ptu_Te_Actl 1;
BA_ "GenSigStartValueInteger" SG_ 1101 Ptu_Te_Actl 50;
BA_ "U_T6_MCA_MY2020_Tx" SG_ 1101 PtLatchActv_B_RqAwd 1;
BA_ "U_CX727_MY2021_Rx" SG_ 1101 PtLatchActv_B_RqAwd 1;
BA_ "U_T6_MCA_MY2020_Rx" SG_ 1101 PtLatchActv_B_RqAwd 1;
BA_ "GenSigSendType" SG_ 1101 PtLatchActv_B_RqAwd 3;
BA_ "U_T6_MCA_MY2020_Tx" SG_ 1101 PtuFanOn_B_Rq 1;
BA_ "U_T6_MCA_MY2020_Rx" SG_ 1101 PtuFanOn_B_Rq 1;
BA_ "GenSigSendType" SG_ 1101 PtuFanOn_B_Rq 3;
BA_ "GenSigSendType" SG_ 1101 RearDiffLckLamp_D_Rq3 3;
BA_ "U_T6_MCA_MY2020_Rx" SG_ 1099 RearDiff_D_Stat 1;
BA_ "U_U55X_MY2022_Rx" SG_ 1099 RearDiffThrml_D_Stat 1;
BA_ "U_T6_MCA_MY2020_Tx" SG_ 1052 AwdDcnntSlipTrgt_B_Rq 1;
BA_ "U_T6_MCA_MY2020_Rx" SG_ 1052 AwdDcnntSlipTrgt_B_Rq 1;
BA_ "U_T6_MCA_MY2020_Tx" SG_ 1052 AwdCnnct_D_Stat 1;
BA_ "U_T6_MCA_MY2020_Rx" SG_ 1052 AwdCnnct_D_Stat 1;
BA_ "GenSigStartValue" SG_ 1052 AwdCnnct_D_Stat 1;
BA_ "GenSigStartValueInteger" SG_ 1052 AwdCnnct_D_Stat 1;
BA_ "U_CX727_MY2021_Tx" SG_ 1052 AwdLck_Tq_Actl 1;
BA_ "U_T6_MCA_MY2020_Tx" SG_ 1052 AwdLck_Tq_Actl 1;
BA_ "U_T6_MCA_MY2020_Rx" SG_ 1052 AwdLck_Tq_Actl 1;
BA_ "U_CD542_MY2021_Rx" SG_ 1052 AwdLck_Tq_Actl 1;
BA_ "U_CX727_MY2021_Rx" SG_ 1052 AwdLck_Tq_Actl 1;
BA_ "U_P702_MY2021_Rx" SG_ 1052 AwdLck_Tq_Actl 1;
BA_ "U_CX727_MY2021_Tx" SG_ 1052 AwdLckTqNeg_B_Actl 1;
BA_ "U_CD542_MY2021_Rx" SG_ 1052 AwdLckTqNeg_B_Actl 1;
BA_ "U_CX727_MY2021_Rx" SG_ 1052 AwdLckTqNeg_B_Actl 1;
BA_ "U_T6_MCA_MY2020_Rx" SG_ 1093 TrlrBrkDcnnt_B_Actl 1;
BA_ "U_U55X_MY2022_Rx" SG_ 1093 TrlrBrkActCnnct_B_Actl 1;
BA_ "U_CX727_MY2021_Rx" SG_ 1093 TrlrBrkActCnnct_B_Actl 1;
BA_ "U_P702_MY2021_Rx" SG_ 1093 TrlrBrkActCnnct_B_Actl 1;
BA_ "U_CD542_MY2021_Rx" SG_ 1093 TrlrBrkActCnnct_B_Actl 1;
BA_ "U_T6_MCA_MY2020_Rx" SG_ 1093 TrlrBrkActCnnct_B_Actl 1;
BA_ "ContentDependant" SG_ 1093 StopLamp_B_RqTrlrBrk 1;
BA_ "U_CD542_MY2021_Rx" SG_ 1093 TrlrBrkCtl_B_Falt 1;
BA_ "U_T6_MCA_MY2020_Rx" SG_ 1093 TrlrBrkCtl_B_Falt 1;
BA_ "U_CD542_MY2021_Rx" SG_ 1093 TrlrBrkActCirct_B_Falt 1;
BA_ "U_T6_MCA_MY2020_Rx" SG_ 1093 TrlrBrkActCirct_B_Falt 1;
BA_ "U_T6_MCA_MY2020_Tx" SG_ 837 Ccd_B_Falt 1;
BA_ "GenSigSendType" SG_ 837 Ccd_B_Falt 3;
BA_ "GenSigSendType" SG_ 837 SuspVLim_B_Rq 3;
BA_ "U_T6_MCA_MY2020_Tx" SG_ 837 SelDrvMdeSusp_D_Stat 1;
BA_ "U_U55X_MY2022_Rx" SG_ 837 SelDrvMdeSusp_D_Stat 1;
BA_ "U_T6_MCA_MY2020_Rx" SG_ 837 SelDrvMdeSusp_D_Stat 1;
BA_ "U_P702_MY2021_Rx" SG_ 837 SelDrvMdeSusp_D_Stat 1;
BA_ "U_CX727_MY2021_Rx" SG_ 837 SelDrvMdeSusp_D_Stat 1;
BA_ "GenSigSendType" SG_ 837 SelDrvMdeSusp_D_Stat 3;
BA_ "U_T6_MCA_MY2020_Tx" SG_ 837 AdptDrvMdePt_D_Rq 1;
BA_ "U_U55X_MY2022_Rx" SG_ 837 AdptDrvMdePt_D_Rq 1;
BA_ "U_P702_MY2021_Rx" SG_ 837 AdptDrvMdePt_D_Rq 1;
BA_ "U_CX727_MY2021_Rx" SG_ 837 AdptDrvMdePt_D_Rq 1;
BA_ "GenSigSendType" SG_ 837 AdptDrvMdePt_D_Rq 3;
BA_ "U_T6_MCA_MY2020_Tx" SG_ 837 AdptDrvMdeChassis_D_Rq 1;
BA_ "U_U55X_MY2022_Rx" SG_ 837 AdptDrvMdeChassis_D_Rq 1;
BA_ "U_P702_MY2021_Rx" SG_ 837 AdptDrvMdeChassis_D_Rq 1;
BA_ "U_CX727_MY2021_Rx" SG_ 837 AdptDrvMdeChassis_D_Rq 1;
BA_ "GenSigSendType" SG_ 837 AdptDrvMdeChassis_D_Rq 3;
BA_ "GenSigSendType" SG_ 837 AirSprngRateRr_D_Rq 3;
BA_ "GenSigSendType" SG_ 837 AirSprngRateRl_D_Rq 3;
BA_ "GenSigSendType" SG_ 837 SuspType_B_Stat 3;
BA_ "GenSigSendType" SG_ 837 AirSprngRateFr_D_Rq 3;
BA_ "GenSigSendType" SG_ 837 AirSprngRateFl_D_Rq 3;
BA_ "GenSigSendType" SG_ 837 AirSusp_D_Stat 3;
BA_ "GenSigSendType" SG_ 837 AirSuspMsgTxt_D_Rq 3;
BA_ "GenSigSendType" SG_ 837 SuspDrvMde_D_Stat 3;
BA_ "U_T6_MCA_MY2020_Tx" SG_ 837 CcdMsgTxt_D_RqDsply 1;
BA_ "U_P702_MY2021_Rx" SG_ 837 CcdMsgTxt_D_RqDsply 1;
BA_ "U_U55X_MY2022_Rx" SG_ 837 CcdMsgTxt_D_RqDsply 1;
BA_ "GenSigSendType" SG_ 837 CcdMsgTxt_D_RqDsply 3;
BA_ "U_T6_MCA_MY2020_Rx" SG_ 792 FuelRange_L_Dsply 1;
BA_ "U_P702_MY2021_Rx" SG_ 792 FuelRange_L_Dsply 1;
BA_ "ContentDependant" SG_ 792 ElTrip_L_Dsply 1;
BA_ "ContentDependant" SG_ 792 ElLongTerm_L_Dsply 1;
BA_ "U_T6_MCA_MY2020_Rx" SG_ 968 LnchCtl_N_Rq 1;
BA_ "U_T6_MCA_MY2020_Rx" SG_ 968 LnchCtl_D_Rq 1;
BA_ "GenSigStartValue" SG_ 968 CurrentColor_CmdGage 8;
BA_ "GenSigStartValueInteger" SG_ 968 CurrentColor_CmdGage 8;
BA_ "GenSigStartValue" SG_ 968 BlendedColor_CmdGage 2;
BA_ "GenSigStartValueInteger" SG_ 968 BlendedColor_CmdGage 2;
BA_ "GenSigStartValue" SG_ 968 Current_Color_Cmd 8;
BA_ "GenSigStartValueInteger" SG_ 968 Current_Color_Cmd 8;
BA_ "GenSigStartValue" SG_ 968 BlendedColor_Cmd 2;
BA_ "GenSigStartValueInteger" SG_ 968 BlendedColor_Cmd 2;
BA_ "U_P702_MY2021_Rx" SG_ 968 SlMde_D_Rq 1;
BA_ "U_T6_MCA_MY2020_Rx" SG_ 968 SlMde_D_Rq 1;
BA_ "U_CD542_MY2021_Rx" SG_ 968 SlMde_D_Rq 1;
BA_ "GenSigStartValue" SG_ 968 SlMde_D_Rq 2;
BA_ "GenSigStartValueInteger" SG_ 968 SlMde_D_Rq 2;
BA_ "U_P702_MY2021_Rx" SG_ 968 IsaOffst_D_Rq 1;
BA_ "U_T6_MCA_MY2020_Rx" SG_ 968 IsaOffst_D_Rq 1;
BA_ "U_CD542_MY2021_Rx" SG_ 968 IsaOffst_D_Rq 1;
BA_ "GenSigStartValue" SG_ 968 IsaOffst_D_Rq 14;
BA_ "GenSigStartValueInteger" SG_ 968 IsaOffst_D_Rq 14;
BA_ "U_CD542_MY2021_Rx" SG_ 819 WndwUpPsngrRear_D_Falt 1;
BA_ "U_CD542_MY2021_Rx" SG_ 819 WndwUpPsngrFront_D_Falt 1;
BA_ "WakeupSignal" SG_ 819 Memory_3_SwPsngr_Stat 1;
BA_ "WakeupSignal" SG_ 819 Memory_2_SwPsngr_Stat 1;
BA_ "WakeupSignal" SG_ 819 Memory_1_SwPsngr_Stat 1;
BA_ "U_CD542_MY2021_Rx" SG_ 819 BLISLEDStatPassSide 1;
BA_ "U_T6_MCA_MY2020_Rx" SG_ 819 BLISLEDStatPassSide 1;
BA_ "U_U55X_MY2022_Rx" SG_ 819 WndwPsngrSide_D_Stat 1;
BA_ "U_CD542_MY2021_Rx" SG_ 819 WndwPsngrSide_D_Stat 1;
BA_ "U_T6_MCA_MY2020_Rx" SG_ 819 WndwPsngrSide_D_Stat 1;
BA_ "U_P702_MY2021_Rx" SG_ 819 WndwPsngrSide_D_Stat 1;
BA_ "WakeupSignal" SG_ 819 Pasngr_Lock_Sw_Stat 1;
BA_ "MetaData" SG_ 819 Pasngr_Lock_Sw_Cnt 1;
BA_ "WakeupSignal" SG_ 819 Pasngr_Lock_Sw_Cnt 1;
BA_ "WakeupSignal" SG_ 819 ChildLckFdbckRp_B_Stat 1;
BA_ "WakeupSignal" SG_ 819 DrPrsntPsngr_D_Stat 1;
BA_ "WakeupSignal" SG_ 819 DrPrsntRearPsngr_D_Stat 1;
BA_ "U_CD542_MY2021_Rx" SG_ 818 WndwUpDrvRear_D_Falt 1;
BA_ "U_CD542_MY2021_Rx" SG_ 818 WndwUpDrvFront_D_Falt 1;
BA_ "U_CD542_MY2021_Rx" SG_ 818 BLISLEDStatDriverSide 1;
BA_ "U_T6_MCA_MY2020_Rx" SG_ 818 BLISLEDStatDriverSide 1;
BA_ "WakeupSignal" SG_ 818 ChildLckPw_N_Cnt 1;
BA_ "U_U55X_MY2022_Rx" SG_ 818 WndwDrvSide_D_Stat 1;
BA_ "U_CD542_MY2021_Rx" SG_ 818 WndwDrvSide_D_Stat 1;
BA_ "U_T6_MCA_MY2020_Rx" SG_ 818 WndwDrvSide_D_Stat 1;
BA_ "U_P702_MY2021_Rx" SG_ 818 WndwDrvSide_D_Stat 1;
BA_ "WakeupSignal" SG_ 818 KeyCylSwDrvDr_D_Stat 1;
BA_ "WakeupSignal" SG_ 818 Driver_Lock_Sw_Stat 1;
BA_ "MetaData" SG_ 818 Driver_Lock_Sw_Cnt 1;
BA_ "WakeupSignal" SG_ 818 Driver_Lock_Sw_Cnt 1;
BA_ "WakeupSignal" SG_ 818 ChildLckPw_D_Rq 1;
BA_ "WakeupSignal" SG_ 818 ChildLckFdbckRd_B_Stat 1;
BA_ "U_U55X_MY2022_Rx" SG_ 818 DrPrsntDrv_D_Stat 1;
BA_ "U_T6_MCA_MY2020_Rx" SG_ 818 DrPrsntDrv_D_Stat 1;
BA_ "WakeupSignal" SG_ 818 DrPrsntDrv_D_Stat 1;
BA_ "WakeupSignal" SG_ 818 DrPrsntRearDrv_D_Stat 1;
BA_ "GenSigStartValueInteger" SG_ 806 ClimtDeltaLoad_Pw_Actl 32;
BA_ "U_U55X_MY2022_Rx" SG_ 806 StopStrtDrvMde_B_RqBtn 1;
BA_ "U_CD542_MY2021_Rx" SG_ 806 StopStrtDrvMde_B_RqBtn 1;
BA_ "U_T6_MCA_MY2020_Rx" SG_ 806 StopStrtDrvMde_B_RqBtn 1;
BA_ "U_P702_MY2021_Rx" SG_ 806 StopStrtDrvMde_B_RqBtn 1;
BA_ "U_T6_MCA_MY2020_Rx" SG_ 806 HvacHtrCore_Te_Rq 1;
BA_ "U_CD542_MY2021_Rx" SG_ 806 HvacHtrCore_Te_Rq 1;
BA_ "U_P702_MY2021_Rx" SG_ 806 HvacHtrCore_Te_Rq 1;
BA_ "U_CX727_MY2021_Rx" SG_ 806 HvacHtrCore_Te_Rq 1;
BA_ "U_U55X_MY2022_Rx" SG_ 806 ClimtHeat_D_Rq 1;
BA_ "U_T6_MCA_MY2020_Rx" SG_ 806 ClimtHeat_D_Rq 1;
BA_ "U_CD542_MY2021_Rx" SG_ 806 ClimtHeat_D_Rq 1;
BA_ "U_P702_MY2021_Rx" SG_ 806 ClimtHeat_D_Rq 1;
BA_ "U_CX727_MY2021_Rx" SG_ 806 ClimtHeat_D_Rq 1;
BA_ "U_U55X_MY2022_Rx" SG_ 806 ClimtCool_D_Rq 1;
BA_ "U_T6_MCA_MY2020_Rx" SG_ 806 ClimtCool_D_Rq 1;
BA_ "U_CD542_MY2021_Rx" SG_ 806 ClimtCool_D_Rq 1;
BA_ "U_P702_MY2021_Rx" SG_ 806 ClimtCool_D_Rq 1;
BA_ "U_CX727_MY2021_Rx" SG_ 806 ClimtCool_D_Rq 1;
BA_ "U_U55X_MY2022_Rx" SG_ 806 HvacEvap_Te_Rq 1;
BA_ "U_T6_MCA_MY2020_Rx" SG_ 806 HvacEvap_Te_Rq 1;
BA_ "U_CD542_MY2021_Rx" SG_ 806 HvacEvap_Te_Rq 1;
BA_ "U_P702_MY2021_Rx" SG_ 806 HvacEvap_Te_Rq 1;
BA_ "U_CX727_MY2021_Rx" SG_ 806 HvacEvap_Te_Rq 1;
BA_ "GenSigStartValueInteger" SG_ 806 HvacEvap_Te_Rq 400;
BA_ "U_U55X_MY2022_Rx" SG_ 806 HvacEvap_Te_Actl 1;
BA_ "U_T6_MCA_MY2020_Rx" SG_ 806 HvacEvap_Te_Actl 1;
BA_ "U_CD542_MY2021_Rx" SG_ 806 HvacEvap_Te_Actl 1;
BA_ "U_P702_MY2021_Rx" SG_ 806 HvacEvap_Te_Actl 1;
BA_ "U_CX727_MY2021_Rx" SG_ 806 HvacEvap_Te_Actl 1;
BA_ "GenSigStartValueInteger" SG_ 806 HvacEvap_Te_Actl 400;
BA_ "U_U55X_MY2022_Rx" SG_ 806 HvacAirCond_B_Rq 1;
BA_ "U_CD542_MY2021_Rx" SG_ 806 HvacAirCond_B_Rq 1;
BA_ "U_T6_MCA_MY2020_Rx" SG_ 806 HvacAirCond_B_Rq 1;
BA_ "U_P702_MY2021_Rx" SG_ 806 HvacAirCond_B_Rq 1;
BA_ "U_U55X_MY2022_Rx" SG_ 806 HvacEvap_Te_Offst 1;
BA_ "U_CD542_MY2021_Rx" SG_ 806 HvacEvap_Te_Offst 1;
BA_ "U_T6_MCA_MY2020_Rx" SG_ 806 HvacEvap_Te_Offst 1;
BA_ "U_P702_MY2021_Rx" SG_ 806 HvacEvap_Te_Offst 1;
BA_ "GenSigStartValueInteger" SG_ 806 HvacEvap_Te_Offst 400;
BA_ "U_U55X_MY2022_Rx" SG_ 806 ClimtPw_B_Rq 1;
BA_ "U_CD542_MY2021_Rx" SG_ 806 ClimtPw_B_Rq 1;
BA_ "U_T6_MCA_MY2020_Rx" SG_ 806 ClimtPw_B_Rq 1;
BA_ "U_P702_MY2021_Rx" SG_ 806 ClimtPw_B_Rq 1;
BA_ "U_CD542_MY2021_Rx" SG_ 765 BalrSwtch_D_Stat 1;
BA_ "U_T6_MCA_MY2020_Rx" SG_ 765 BalrSwtch_D_Stat 1;
BA_ "GenSigStartValue" SG_ 765 BalrSwtch_D_Stat 1;
BA_ "GenSigStartValueInteger" SG_ 765 BalrSwtch_D_Stat 1;
BA_ "U_CD542_MY2021_Rx" SG_ 765 BalrMde_D_Rq 1;
BA_ "U_T6_MCA_MY2020_Rx" SG_ 765 BalrMde_D_Rq 1;
BA_ "U_T6_MCA_MY2020_Rx" SG_ 765 WaitToStartLamp_D_Falt 1;
BA_ "U_P702_MY2021_Rx" SG_ 765 WaitToStartLamp_D_Falt 1;
BA_ "GenSigStartValue" SG_ 765 WaitToStartLamp_D_Falt 1;
BA_ "GenSigStartValueInteger" SG_ 765 WaitToStartLamp_D_Falt 1;
BA_ "U_CD542_MY2021_Rx" SG_ 765 EsaOn_B_Rq 1;
BA_ "U_T6_MCA_MY2020_Rx" SG_ 765 EsaOn_B_Rq 1;
BA_ "U_P702_MY2021_Rx" SG_ 765 EsaOn_B_Rq 1;
BA_ "U_CX727_MY2021_Rx" SG_ 765 EsaOn_B_Rq 1;
BA_ "GenSigStartValue" SG_ 765 EsaOn_B_Rq 1;
BA_ "GenSigStartValueInteger" SG_ 765 EsaOn_B_Rq 1;
BA_ "U_CD542_MY2021_Rx" SG_ 765 BttOn_B_Rq 1;
BA_ "U_T6_MCA_MY2020_Rx" SG_ 765 BttOn_B_Rq 1;
BA_ "U_CD542_MY2021_Rx" SG_ 765 Btt_L_Actl 1;
BA_ "U_T6_MCA_MY2020_Rx" SG_ 765 Btt_L_Actl 1;
BA_ "GenSigStartValue" SG_ 765 Btt_L_Actl 126;
BA_ "GenSigStartValueInteger" SG_ 765 Btt_L_Actl 126;
BA_ "U_P702_MY2021_Rx" SG_ 765 RearDiffLck_D_RqArb 1;
BA_ "GenSigStartValue" SG_ 765 RearDiffLck_D_RqArb 3;
BA_ "GenSigStartValueInteger" SG_ 765 RearDiffLck_D_RqArb 3;
BA_ "U_P702_MY2021_Rx" SG_ 765 AwdMde_D_RqArb 1;
BA_ "GenSigStartValue" SG_ 765 AwdMde_D_RqArb 5;
BA_ "GenSigStartValueInteger" SG_ 765 AwdMde_D_RqArb 5;
BA_ "U_U55X_MY2022_Rx" SG_ 765 SelDrvMdeTxtReset_B_Rq 1;
BA_ "U_T6_MCA_MY2020_Rx" SG_ 765 SelDrvMdeTxtReset_B_Rq 1;
BA_ "U_P702_MY2021_Rx" SG_ 765 SelDrvMdeTxtReset_B_Rq 1;
BA_ "U_U55X_MY2022_Rx" SG_ 765 AutoTowAllw_D_RqMnu 1;
BA_ "WakeupSignal" SG_ 765 DrvInputRequired_B_Rq 1;
BA_ "U_U55X_MY2022_Rx" SG_ 765 SelDrvMdeDsply_B_Avail 1;
BA_ "U_CD542_MY2021_Rx" SG_ 765 SelDrvMdeDsply_B_Avail 1;
BA_ "U_T6_MCA_MY2020_Rx" SG_ 765 SelDrvMdeDsply_B_Avail 1;
BA_ "U_P702_MY2021_Rx" SG_ 765 SelDrvMdeDsply_B_Avail 1;
BA_ "GenSigStartValue" SG_ 765 EngExhMdeQuiet_D_Rq 2;
BA_ "GenSigStartValueInteger" SG_ 765 EngExhMdeQuiet_D_Rq 2;
BA_ "U_T6_MCA_MY2020_Rx" SG_ 765 AwdRnge_D_ActlIpc 1;
BA_ "U_P702_MY2021_Rx" SG_ 765 AwdRnge_D_ActlIpc 1;
BA_ "GenSigStartValue" SG_ 765 AwdRnge_D_ActlIpc 7;
BA_ "GenSigStartValueInteger" SG_ 765 AwdRnge_D_ActlIpc 7;
BA_ "U_T6_MCA_MY2020_Rx" SG_ 765 BrkLineLck_D_Rq 1;
BA_ "U_T6_MCA_MY2020_Rx" SG_ 765 EdmSailMde_B_RqDrv 1;
BA_ "U_T6_MCA_MY2020_Rx" SG_ 518 RearDiffLck_Tq_Actl2 1;
BA_ "U_P702_MY2021_Rx" SG_ 518 RearDiffLck_Tq_Actl2 1;
BA_ "U_U55X_MY2022_Rx" SG_ 518 RearDiffLck_Tq_Actl2 1;
BA_ "GenSigStartValue" SG_ 518 RearDiffLck_Tq_Actl2 16382;
BA_ "GenSigStartValueInteger" SG_ 518 RearDiffLck_Tq_Actl2 16382;
BA_ "U_CD542_MY2021_Rx" SG_ 559 EhData2_No_Actl 1;
BA_ "U_T6_MCA_MY2020_Rx" SG_ 559 EhData2_No_Actl 1;
BA_ "U_P702_MY2021_Rx" SG_ 559 EhData2_No_Actl 1;
BA_ "U_CD542_MY2021_Rx" SG_ 558 EhData1_No_Actl 1;
BA_ "U_T6_MCA_MY2020_Rx" SG_ 558 EhData1_No_Actl 1;
BA_ "U_P702_MY2021_Rx" SG_ 558 EhData1_No_Actl 1;
BA_ "U_CD542_MY2021_Tx" SG_ 934 CtaAlrtLeft2_D_Stat 1;
BA_ "U_T6_MCA_MY2020_Tx" SG_ 934 CtaAlrtLeft2_D_Stat 1;
BA_ "GenSigSendType" SG_ 934 CtaAlrtLeft2_D_Stat 3;
BA_ "U_CD542_MY2021_Tx" SG_ 934 CtaBrkLeftMsgTxt_B_Rq 1;
BA_ "U_T6_MCA_MY2020_Tx" SG_ 934 CtaBrkLeftMsgTxt_B_Rq 1;
BA_ "GenSigSendType" SG_ 934 CtaBrkLeftMsgTxt_B_Rq 3;
BA_ "U_CD542_MY2021_Tx" SG_ 934 CtaLeftBrkDecel_B_Rq 1;
BA_ "U_T6_MCA_MY2020_Tx" SG_ 934 CtaLeftBrkDecel_B_Rq 1;
BA_ "U_U55X_MY2022_Rx" SG_ 934 CtaLeftBrkDecel_B_Rq 1;
BA_ "U_CD542_MY2021_Rx" SG_ 934 CtaLeftBrkDecel_B_Rq 1;
BA_ "U_T6_MCA_MY2020_Rx" SG_ 934 CtaLeftBrkDecel_B_Rq 1;
BA_ "U_P702_MY2021_Rx" SG_ 934 CtaLeftBrkDecel_B_Rq 1;
BA_ "U_CX727_MY2021_Rx" SG_ 934 CtaLeftBrkDecel_B_Rq 1;
BA_ "GenSigSendType" SG_ 934 CtaLeftBrkDecel_B_Rq 3;
BA_ "U_CD542_MY2021_Tx" SG_ 934 CtaLeftBrkEnbl_B_Rq 1;
BA_ "U_T6_MCA_MY2020_Tx" SG_ 934 CtaLeftBrkEnbl_B_Rq 1;
BA_ "U_U55X_MY2022_Rx" SG_ 934 CtaLeftBrkEnbl_B_Rq 1;
BA_ "U_CD542_MY2021_Rx" SG_ 934 CtaLeftBrkEnbl_B_Rq 1;
BA_ "U_T6_MCA_MY2020_Rx" SG_ 934 CtaLeftBrkEnbl_B_Rq 1;
BA_ "U_P702_MY2021_Rx" SG_ 934 CtaLeftBrkEnbl_B_Rq 1;
BA_ "U_CX727_MY2021_Rx" SG_ 934 CtaLeftBrkEnbl_B_Rq 1;
BA_ "GenSigSendType" SG_ 934 CtaLeftBrkEnbl_B_Rq 3;
BA_ "U_CD542_MY2021_Tx" SG_ 934 Side_Detect_L_Illum 1;
BA_ "U_T6_MCA_MY2020_Tx" SG_ 934 Side_Detect_L_Illum 1;
BA_ "GenSigStartValue" SG_ 934 Side_Detect_L_Illum 100;
BA_ "GenSigStartValueInteger" SG_ 934 Side_Detect_L_Illum 100;
BA_ "U_CD542_MY2021_Tx" SG_ 934 BttLeft_D_Stat 1;
BA_ "U_T6_MCA_MY2020_Tx" SG_ 934 BttLeft_D_Stat 1;
BA_ "GenSigSendType" SG_ 934 BttLeft_D_Stat 3;
BA_ "U_CD542_MY2021_Tx" SG_ 934 BttLeft_D_RqDrv 1;
BA_ "U_T6_MCA_MY2020_Tx" SG_ 934 BttLeft_D_RqDrv 1;
BA_ "GenSigSendType" SG_ 934 BttLeft_D_RqDrv 3;
BA_ "U_CD542_MY2021_Tx" SG_ 934 CtaSnsLeft_D_Stat 1;
BA_ "U_T6_MCA_MY2020_Tx" SG_ 934 CtaSnsLeft_D_Stat 1;
BA_ "GenSigSendType" SG_ 934 CtaSnsLeft_D_Stat 3;
BA_ "U_CD542_MY2021_Tx" SG_ 934 SodDetctLeft_D_Stat 1;
BA_ "U_T6_MCA_MY2020_Tx" SG_ 934 SodDetctLeft_D_Stat 1;
BA_ "GenSigSendType" SG_ 934 SodDetctLeft_D_Stat 3;
BA_ "U_CD542_MY2021_Tx" SG_ 934 CtaLeft_D_Stat 1;
BA_ "U_T6_MCA_MY2020_Tx" SG_ 934 CtaLeft_D_Stat 1;
BA_ "GenSigSendType" SG_ 934 CtaLeft_D_Stat 3;
BA_ "U_CD542_MY2021_Tx" SG_ 934 CtaAlrtLeft_D_Stat 1;
BA_ "U_T6_MCA_MY2020_Tx" SG_ 934 CtaAlrtLeft_D_Stat 1;
BA_ "GenSigSendType" SG_ 934 CtaAlrtLeft_D_Stat 3;
BA_ "U_CD542_MY2021_Tx" SG_ 934 SodLeft_D_Stat 1;
BA_ "U_T6_MCA_MY2020_Tx" SG_ 934 SodLeft_D_Stat 1;
BA_ "GenSigSendType" SG_ 934 SodLeft_D_Stat 3;
BA_ "GenSigStartValue" SG_ 934 SodLeft_D_Stat 2;
BA_ "GenSigStartValueInteger" SG_ 934 SodLeft_D_Stat 2;
BA_ "U_CD542_MY2021_Tx" SG_ 934 SodSnsLeft_D_Stat 1;
BA_ "U_T6_MCA_MY2020_Tx" SG_ 934 SodSnsLeft_D_Stat 1;
BA_ "GenSigSendType" SG_ 934 SodSnsLeft_D_Stat 3;
BA_ "U_CD542_MY2021_Tx" SG_ 934 SodAlrtLeft_D_Stat 1;
BA_ "U_T6_MCA_MY2020_Tx" SG_ 934 SodAlrtLeft_D_Stat 1;
BA_ "GenSigSendType" SG_ 934 SodAlrtLeft_D_Stat 3;
BA_ "U_CD542_MY2021_Tx" SG_ 934 SodWarnLeft_Prd_Rq 1;
BA_ "U_T6_MCA_MY2020_Tx" SG_ 934 SodWarnLeft_Prd_Rq 1;
BA_ "GenSigStartValue" SG_ 934 SodWarnLeft_Prd_Rq 14;
BA_ "GenSigStartValueInteger" SG_ 934 SodWarnLeft_Prd_Rq 14;
BA_ "U_P702_MY2021_Rx" SG_ 825 LscmbbEngTqMn_B_Rq 1;
BA_ "U_P702_MY2021_Rx" SG_ 825 LscmbbDeny_B_Actl 1;
BA_ "U_P702_MY2021_Rx" SG_ 825 LscmbbBrkPrchg_D_Rq 1;
BA_ "U_P702_MY2021_Rx" SG_ 825 LscmbbBrkDecel_No_Cs 1;
BA_ "MetaData" SG_ 825 LscmbbBrkDecel_No_Cs 1;
BA_ "U_P702_MY2021_Rx" SG_ 825 LscmbbBrkDecel_No_Cnt 1;
BA_ "MetaData" SG_ 825 LscmbbBrkDecel_No_Cnt 1;
BA_ "U_P702_MY2021_Rx" SG_ 825 LscmbbBrkDecel_B_Enbl 1;
BA_ "U_P702_MY2021_Rx" SG_ 825 LscmbbBrkDecel_A_Rq 1;
BA_ "GenSigStartValueInteger" SG_ 825 LscmbbBrkDecel_A_Rq 255;
BA_ "U_P702_MY2021_Rx" SG_ 825 LscmbbBaSens_D_Rq 1;
BA_ "U_U55X_MY2022_Rx" SG_ 1072 DrvSlipCtlMde_D_Rq 1;
BA_ "U_CD542_MY2021_Rx" SG_ 1072 DrvSlipCtlMde_D_Rq 1;
BA_ "U_T6_MCA_MY2020_Rx" SG_ 1072 DrvSlipCtlMde_D_Rq 1;
BA_ "U_P702_MY2021_Rx" SG_ 1072 DrvSlipCtlMde_D_Rq 1;
BA_ "U_CX727_MY2021_Rx" SG_ 1072 EngIdlShutDown_B_RqDrv 1;
BA_ "U_U55X_MY2022_Rx" SG_ 1072 EngIdlShutDown_B_RqDrv 1;
BA_ "U_CD542_MY2021_Rx" SG_ 1072 EngIdlShutDown_B_RqDrv 1;
BA_ "U_T6_MCA_MY2020_Rx" SG_ 1072 EngIdlShutDown_B_RqDrv 1;
BA_ "U_P702_MY2021_Rx" SG_ 1072 EngIdlShutDown_B_RqDrv 1;
BA_ "U_U55X_MY2022_Rx" SG_ 1072 HsaMde_D_Rq 1;
BA_ "U_CD542_MY2021_Rx" SG_ 1072 HsaMde_D_Rq 1;
BA_ "U_T6_MCA_MY2020_Rx" SG_ 1072 HsaMde_D_Rq 1;
BA_ "U_CX727_MY2021_Rx" SG_ 1072 HsaMde_D_Rq 1;
BA_ "GenSigStartValue" SG_ 1072 HsaMde_D_Rq 1;
BA_ "GenSigStartValueInteger" SG_ 1072 HsaMde_D_Rq 1;
BA_ "U_U55X_MY2022_Rx" SG_ 1072 StopStrtDrvMde_D_RqMnu 1;
BA_ "U_CD542_MY2021_Rx" SG_ 1072 StopStrtDrvMde_D_RqMnu 1;
BA_ "U_T6_MCA_MY2020_Rx" SG_ 1072 StopStrtDrvMde_D_RqMnu 1;
BA_ "U_P702_MY2021_Rx" SG_ 1072 StopStrtDrvMde_D_RqMnu 1;
BA_ "U_U55X_MY2022_Rx" SG_ 1072 NtrlTowMdeEnbl_B_RqDrv 1;
BA_ "U_P702_MY2021_Rx" SG_ 1072 NtrlTowMdeEnbl_B_RqDrv 1;
BA_ "U_CD542_MY2021_Rx" SG_ 1072 NtrlTowMdeEnbl_B_RqDrv 1;
BA_ "U_CX727_MY2021_Rx" SG_ 1072 NtrlTowMdeEnbl_B_RqDrv 1;
BA_ "U_T6_MCA_MY2020_Rx" SG_ 1072 NtrlTowMdeEnbl_B_RqDrv 1;
BA_ "U_CD542_MY2021_Rx" SG_ 1072 ParkDetect_Stat 1;
BA_ "U_P702_MY2021_Rx" SG_ 1072 ParkDetect_Stat 1;
BA_ "U_U55X_MY2022_Rx" SG_ 1072 FrostWarn_D_Stat 1;
BA_ "U_CD542_MY2021_Rx" SG_ 1072 FrostWarn_D_Stat 1;
BA_ "U_T6_MCA_MY2020_Rx" SG_ 1072 FrostWarn_D_Stat 1;
BA_ "U_P702_MY2021_Rx" SG_ 1072 FrostWarn_D_Stat 1;
BA_ "U_U55X_MY2022_Rx" SG_ 1072 TRLR_SWAY_CONFIG_CMD 1;
BA_ "U_CD542_MY2021_Rx" SG_ 1072 TRLR_SWAY_CONFIG_CMD 1;
BA_ "U_T6_MCA_MY2020_Rx" SG_ 1072 TRLR_SWAY_CONFIG_CMD 1;
BA_ "U_P702_MY2021_Rx" SG_ 1072 TRLR_SWAY_CONFIG_CMD 1;
BA_ "WakeupSignal" SG_ 1072 Power_Liftgate_Mode_Cmd 1;
BA_ "U_CD542_MY2021_Rx" SG_ 1072 AccEnbl_B_RqDrv 1;
BA_ "U_T6_MCA_MY2020_Rx" SG_ 1072 AccEnbl_B_RqDrv 1;
BA_ "GenSigStartValue" SG_ 1072 AccEnbl_B_RqDrv 1;
BA_ "GenSigStartValueInteger" SG_ 1072 AccEnbl_B_RqDrv 1;
BA_ "U_U55X_MY2022_Rx" SG_ 1072 OdometerMasterValue 1;
BA_ "U_P702_MY2021_Rx" SG_ 1072 OdometerMasterValue 1;
BA_ "U_T6_MCA_MY2020_Rx" SG_ 1072 OdometerMasterValue 1;
BA_ "U_CD542_MY2021_Rx" SG_ 1072 OdometerMasterValue 1;
BA_ "U_CX727_MY2021_Rx" SG_ 1072 OdometerMasterValue 1;
BA_ "U_CX727_MY2021_Rx" SG_ 1072 EngOilLife_B_RqReset 1;
BA_ "U_U55X_MY2022_Rx" SG_ 1072 EngOilLife_B_RqReset 1;
BA_ "U_CD542_MY2021_Rx" SG_ 1072 EngOilLife_B_RqReset 1;
BA_ "U_T6_MCA_MY2020_Rx" SG_ 1072 EngOilLife_B_RqReset 1;
BA_ "U_P702_MY2021_Rx" SG_ 1072 EngOilLife_B_RqReset 1;
BA_ "U_CD542_MY2021_Rx" SG_ 1072 AccDeny_B_RqIpc 1;
BA_ "U_T6_MCA_MY2020_Rx" SG_ 1072 AccDeny_B_RqIpc 1;
BA_ "U_U55X_MY2022_Rx" SG_ 1072 ePRNDL_MODE 1;
BA_ "U_T6_MCA_MY2020_Rx" SG_ 1072 ePRNDL_MODE 1;
BA_ "U_P702_MY2021_Rx" SG_ 1072 ePRNDL_MODE 1;
BA_ "U_CD542_MY2021_Rx" SG_ 1072 ePRNDL_MODE 1;
BA_ "U_CX727_MY2021_Rx" SG_ 1072 ePRNDL_MODE 1;
BA_ "WakeupSignal" SG_ 1072 ePRNDL_MODE 1;
BA_ "U_U55X_MY2022_Rx" SG_ 1072 DrvSlipCtlMde_B_Rq2 1;
BA_ "U_T6_MCA_MY2020_Rx" SG_ 1072 DrvSlipCtlMde_B_Rq2 1;
BA_ "U_P702_MY2021_Rx" SG_ 1072 DrvSlipCtlMde_B_Rq2 1;
BA_ "U_CX727_MY2021_Rx" SG_ 1072 MetricActv_B_Actl 1;
BA_ "U_U55X_MY2022_Rx" SG_ 1072 MetricActv_B_Actl 1;
BA_ "U_CD542_MY2021_Rx" SG_ 1072 MetricActv_B_Actl 1;
BA_ "U_T6_MCA_MY2020_Rx" SG_ 1072 MetricActv_B_Actl 1;
BA_ "U_P702_MY2021_Rx" SG_ 1072 MetricActv_B_Actl 1;
BA_ "U_T6_MCA_MY2020_Rx" SG_ 1072 ManRgen_D_Rq 1;
BA_ "U_P702_MY2021_Rx" SG_ 1072 ManRgen_D_Rq 1;
BA_ "WakeupSignal" SG_ 909 IgnPsswrdDsply_B_Rq 1;
BA_ "WakeupSignal" SG_ 909 ElPwPoint_D_Rq 1;
BA_ "U_T6_MCA_MY2020_Rx" SG_ 909 WiprFront_D_Stat2 1;
BA_ "GenSigStartValue" SG_ 909 WiprFront_D_Stat2 15;
BA_ "GenSigStartValueInteger" SG_ 909 WiprFront_D_Stat2 15;
BA_ "U_P702_MY2021_Rx" SG_ 909 HeadLghtHiPrmsn_D_Stat 1;
BA_ "U_CX727_MY2021_Rx" SG_ 909 HeadLghtHiPrmsn_D_Stat 1;
BA_ "U_CD542_MY2021_Rx" SG_ 909 HeadLghtHiPrmsn_D_Stat 1;
BA_ "U_T6_MCA_MY2020_Rx" SG_ 909 HeadLghtHiPrmsn_D_Stat 1;
BA_ "GenSigStartValue" SG_ 909 HeadLghtHiPrmsn_D_Stat 3;
BA_ "GenSigStartValueInteger" SG_ 909 HeadLghtHiPrmsn_D_Stat 3;
BA_ "WakeupSignal" SG_ 909 immoMsgTxt_D_Rq 1;
BA_ "WakeupSignal" SG_ 909 PrsnlDevcChrgEnbl_B_Rq 1;
BA_ "MetaData" SG_ 909 KeyMykeyTot_No_Cnt 1;
BA_ "MetaData" SG_ 909 KeyAdmnTot_No_Cnt 1;
BA_ "WakeupSignal" SG_ 909 HazrdLght_B_Stat 1;
BA_ "U_T6_MCA_MY2020_Rx" SG_ 963 ImpactEvntFdbck_D_Stat 1;
BA_ "WakeupSignal" SG_ 963 ImpactEvntFdbck_D_Stat 1;
BA_ "U_P702_MY2021_Rx" SG_ 963 CrnrLghtRight_Pc_Rq 1;
BA_ "U_CX727_MY2021_Rx" SG_ 963 CrnrLghtRight_Pc_Rq 1;
BA_ "U_P702_MY2021_Rx" SG_ 963 CrnrLghtLeft_Pc_Rq 1;
BA_ "U_CX727_MY2021_Rx" SG_ 963 CrnrLghtLeft_Pc_Rq 1;
BA_ "WakeupSignal" SG_ 963 KeyInIgnWarn_B_Cmd 1;
BA_ "WakeupSignal" SG_ 963 HomeSafeLtChime_B_Rq 1;
BA_ "U_P702_MY2021_Rx" SG_ 963 StopLghtOn_B_Stat 1;
BA_ "U_CX727_MY2021_Rx" SG_ 963 StopLghtOn_B_Stat 1;
BA_ "WakeupSignal" SG_ 963 StopLghtOn_B_Stat 1;
BA_ "WakeupSignal" SG_ 963 PrkLght_D_Stat 1;
BA_ "U_P702_MY2021_Rx" SG_ 963 HeadLghtSwtch_D_Stat 1;
BA_ "U_CX727_MY2021_Rx" SG_ 963 HeadLghtSwtch_D_Stat 1;
BA_ "U_CD542_MY2021_Rx" SG_ 963 HeadLghtSwtch_D_Stat 1;
BA_ "U_T6_MCA_MY2020_Rx" SG_ 963 HeadLghtSwtch_D_Stat 1;
BA_ "GenSigStartValue" SG_ 963 HeadLghtSwtch_D_Stat 2;
BA_ "GenSigStartValueInteger" SG_ 963 HeadLghtSwtch_D_Stat 2;
BA_ "WakeupSignal" SG_ 963 HeadLghtSwtch_D_Stat 1;
BA_ "U_P702_MY2021_Rx" SG_ 963 HeadLampLoFrOn_B_Stat 1;
BA_ "U_CX727_MY2021_Rx" SG_ 963 HeadLampLoFrOn_B_Stat 1;
BA_ "U_CD542_MY2021_Rx" SG_ 963 HeadLampLoFrOn_B_Stat 1;
BA_ "U_T6_MCA_MY2020_Rx" SG_ 963 HeadLampLoFrOn_B_Stat 1;
BA_ "GenSigStartValue" SG_ 963 HeadLampLoFrOn_B_Stat 1;
BA_ "GenSigStartValueInteger" SG_ 963 HeadLampLoFrOn_B_Stat 1;
BA_ "U_P702_MY2021_Rx" SG_ 963 HeadLampLoFlOn_B_Stat 1;
BA_ "U_CX727_MY2021_Rx" SG_ 963 HeadLampLoFlOn_B_Stat 1;
BA_ "U_CD542_MY2021_Rx" SG_ 963 HeadLampLoFlOn_B_Stat 1;
BA_ "U_T6_MCA_MY2020_Rx" SG_ 963 HeadLampLoFlOn_B_Stat 1;
BA_ "GenSigStartValue" SG_ 963 HeadLampLoFlOn_B_Stat 1;
BA_ "GenSigStartValueInteger" SG_ 963 HeadLampLoFlOn_B_Stat 1;
BA_ "U_CX727_MY2021_Rx" SG_ 963 HeadLampLoActv_B_Stat 1;
BA_ "U_U55X_MY2022_Rx" SG_ 963 HeadLampLoActv_B_Stat 1;
BA_ "U_P702_MY2021_Rx" SG_ 963 HeadLampLoActv_B_Stat 1;
BA_ "U_CD542_MY2021_Rx" SG_ 963 HeadLampLoActv_B_Stat 1;
BA_ "U_T6_MCA_MY2020_Rx" SG_ 963 HeadLampLoActv_B_Stat 1;
BA_ "GenSigStartValue" SG_ 963 HeadLampLoActv_B_Stat 1;
BA_ "GenSigStartValueInteger" SG_ 963 HeadLampLoActv_B_Stat 1;
BA_ "WakeupSignal" SG_ 963 Headlamp_On_Wrning_Cmd 1;
BA_ "U_U55X_MY2022_Rx" SG_ 963 HeadLghtHiOn_B_Stat 1;
BA_ "U_CD542_MY2021_Rx" SG_ 963 HeadLghtHiOn_B_Stat 1;
BA_ "U_T6_MCA_MY2020_Rx" SG_ 963 HeadLghtHiOn_B_Stat 1;
BA_ "U_P702_MY2021_Rx" SG_ 963 HeadLghtHiOn_B_Stat 1;
BA_ "WakeupSignal" SG_ 963 HeadLghtHiOn_B_Stat 1;
BA_ "WakeupSignal" SG_ 963 Perimeter_Alarm_Status 1;
BA_ "GenSigStartValue" SG_ 963 Courtesy_BSave_Stat 1;
BA_ "GenSigStartValueInteger" SG_ 963 Courtesy_BSave_Stat 1;
BA_ "WakeupSignal" SG_ 963 Courtesy_BSave_Stat 1;
BA_ "WakeupSignal" SG_ 963 WndwGlbl_D_Cmd 1;
BA_ "WakeupSignal" SG_ 963 PudLamp_D_Rq 1;
BA_ "WakeupSignal" SG_ 963 PerimeterAlarmChimeRq 1;
BA_ "U_U55X_MY2022_Rx" SG_ 145 VehYawWActl_D_Qf 1;
BA_ "U_CD542_MY2021_Rx" SG_ 145 VehYawWActl_D_Qf 1;
BA_ "U_T6_MCA_MY2020_Rx" SG_ 145 VehYawWActl_D_Qf 1;
BA_ "U_P702_MY2021_Rx" SG_ 145 VehYawWActl_D_Qf 1;
BA_ "U_CX727_MY2021_Rx" SG_ 145 VehYawWActl_D_Qf 1;
BA_ "GenSigStartValue" SG_ 145 VehYawWActl_D_Qf 1;
BA_ "MetaData" SG_ 145 VehYawWActl_D_Qf 1;
BA_ "GenSigStartValueInteger" SG_ 145 VehYawWActl_D_Qf 1;
BA_ "U_U55X_MY2022_Rx" SG_ 145 VehRolWActl_D_Qf 1;
BA_ "U_P702_MY2021_Rx" SG_ 145 VehRolWActl_D_Qf 1;
BA_ "U_CX727_MY2021_Rx" SG_ 145 VehRolWActl_D_Qf 1;
BA_ "U_CD542_MY2021_Rx" SG_ 145 VehRolWActl_D_Qf 1;
BA_ "U_T6_MCA_MY2020_Rx" SG_ 145 VehRolWActl_D_Qf 1;
BA_ "GenSigStartValue" SG_ 145 VehRolWActl_D_Qf 1;
BA_ "MetaData" SG_ 145 VehRolWActl_D_Qf 1;
BA_ "GenSigStartValueInteger" SG_ 145 VehRolWActl_D_Qf 1;
BA_ "U_U55X_MY2022_Rx" SG_ 145 VehRollYawW_No_Cs 1;
BA_ "U_P702_MY2021_Rx" SG_ 145 VehRollYawW_No_Cs 1;
BA_ "U_CX727_MY2021_Rx" SG_ 145 VehRollYawW_No_Cs 1;
BA_ "U_CD542_MY2021_Rx" SG_ 145 VehRollYawW_No_Cs 1;
BA_ "U_T6_MCA_MY2020_Rx" SG_ 145 VehRollYawW_No_Cs 1;
BA_ "MetaData" SG_ 145 VehRollYawW_No_Cs 1;
BA_ "U_U55X_MY2022_Rx" SG_ 145 VehRollYaw_No_Cnt 1;
BA_ "U_P702_MY2021_Rx" SG_ 145 VehRollYaw_No_Cnt 1;
BA_ "U_CX727_MY2021_Rx" SG_ 145 VehRollYaw_No_Cnt 1;
BA_ "U_CD542_MY2021_Rx" SG_ 145 VehRollYaw_No_Cnt 1;
BA_ "U_T6_MCA_MY2020_Rx" SG_ 145 VehRollYaw_No_Cnt 1;
BA_ "MetaData" SG_ 145 VehRollYaw_No_Cnt 1;
BA_ "U_U55X_MY2022_Rx" SG_ 145 VehYaw_W_Actl 1;
BA_ "U_P702_MY2021_Rx" SG_ 145 VehYaw_W_Actl 1;
BA_ "U_CX727_MY2021_Rx" SG_ 145 VehYaw_W_Actl 1;
BA_ "U_CD542_MY2021_Rx" SG_ 145 VehYaw_W_Actl 1;
BA_ "U_T6_MCA_MY2020_Rx" SG_ 145 VehYaw_W_Actl 1;
BA_ "GenSigStartValue" SG_ 145 VehYaw_W_Actl 65534;
BA_ "GenSigStartValueInteger" SG_ 145 VehYaw_W_Actl 65534;
BA_ "U_U55X_MY2022_Rx" SG_ 145 VehRol_W_Actl 1;
BA_ "U_P702_MY2021_Rx" SG_ 145 VehRol_W_Actl 1;
BA_ "U_CX727_MY2021_Rx" SG_ 145 VehRol_W_Actl 1;
BA_ "U_CD542_MY2021_Rx" SG_ 145 VehRol_W_Actl 1;
BA_ "U_T6_MCA_MY2020_Rx" SG_ 145 VehRol_W_Actl 1;
BA_ "GenSigStartValue" SG_ 145 VehRol_W_Actl 65534;
BA_ "GenSigStartValueInteger" SG_ 145 VehRol_W_Actl 65534;
BA_ "GenSigStartValue" SG_ 76 PsngrFmidDetct_D_Actl 3;
BA_ "GenSigStartValueInteger" SG_ 76 PsngrFmidDetct_D_Actl 3;
BA_ "U_T6_MCA_MY2020_Rx" SG_ 76 FirstRowBuckleMid 1;
BA_ "GenSigStartValue" SG_ 76 FirstRowBuckleMid 3;
BA_ "GenSigStartValueInteger" SG_ 76 FirstRowBuckleMid 3;
BA_ "GenSigStartValue" SG_ 76 ThirdRowBucklePsngr 3;
BA_ "GenSigStartValueInteger" SG_ 76 ThirdRowBucklePsngr 3;
BA_ "GenSigStartValue" SG_ 76 ThirdRowBuckleMid 3;
BA_ "GenSigStartValueInteger" SG_ 76 ThirdRowBuckleMid 3;
BA_ "GenSigStartValue" SG_ 76 ThirdRowBuckleDriver 3;
BA_ "GenSigStartValueInteger" SG_ 76 ThirdRowBuckleDriver 3;
BA_ "GenSigStartValue" SG_ 76 SecondRowBucklePsngr 3;
BA_ "GenSigStartValueInteger" SG_ 76 SecondRowBucklePsngr 3;
BA_ "GenSigStartValue" SG_ 76 SecondRowBuckleMid 3;
BA_ "GenSigStartValueInteger" SG_ 76 SecondRowBuckleMid 3;
BA_ "GenSigStartValue" SG_ 76 SecondRowBuckleDriver 3;
BA_ "GenSigStartValueInteger" SG_ 76 SecondRowBuckleDriver 3;
BA_ "U_U55X_MY2022_Rx" SG_ 76 FirstRowBuckleDriver 1;
BA_ "U_P702_MY2021_Rx" SG_ 76 FirstRowBuckleDriver 1;
BA_ "U_T6_MCA_MY2020_Rx" SG_ 76 FirstRowBuckleDriver 1;
BA_ "U_CD542_MY2021_Rx" SG_ 76 FirstRowBuckleDriver 1;
BA_ "U_CX727_MY2021_Rx" SG_ 76 FirstRowBuckleDriver 1;
BA_ "GenSigStartValue" SG_ 76 FirstRowBuckleDriver 3;
BA_ "GenSigStartValueInteger" SG_ 76 FirstRowBuckleDriver 3;
BA_ "U_T6_MCA_MY2020_Rx" SG_ 76 FirstRowBucklePsngr 1;
BA_ "GenSigStartValue" SG_ 76 FirstRowBucklePsngr 3;
BA_ "GenSigStartValueInteger" SG_ 76 FirstRowBucklePsngr 3;
BA_ "U_U55X_MY2022_Rx" SG_ 76 RstrnImpactEvntStatus 1;
BA_ "U_T6_MCA_MY2020_Rx" SG_ 76 RstrnImpactEvntStatus 1;
BA_ "U_CD542_MY2021_Rx" SG_ 76 RstrnImpactEvntStatus 1;
BA_ "U_P702_MY2021_Rx" SG_ 76 RstrnImpactEvntStatus 1;
BA_ "U_CX727_MY2021_Rx" SG_ 76 RstrnImpactEvntStatus 1;
BA_ "WakeupSignal" SG_ 76 RstrnImpactEvntStatus 1;
BA_ "GenSigStartValue" SG_ 76 PsngrFrntDetct_D_Actl 3;
BA_ "GenSigStartValueInteger" SG_ 76 PsngrFrntDetct_D_Actl 3;
BA_ "U_CD542_MY2021_Rx" SG_ 76 EDRTriggerEvntSync 1;
BA_ "U_T6_MCA_MY2020_Rx" SG_ 76 EDRTriggerEvntSync 1;
BA_ "GenSigStartValue" SG_ 76 PassRstrnInd_Req 3;
BA_ "GenSigStartValueInteger" SG_ 76 PassRstrnInd_Req 3;
BA_ "U_T6_MCA_MY2020_Rx" SG_ 76 FirstRowBuckle_No_Cs 1;
BA_ "MetaData" SG_ 76 FirstRowBuckle_No_Cs 1;
BA_ "U_T6_MCA_MY2020_Rx" SG_ 76 RCMStatusMsg2_No_Cnt 1;
BA_ "MetaData" SG_ 76 RCMStatusMsg2_No_Cnt 1;
BA_ "U_U55X_MY2022_Rx" SG_ 65 immoControlData_T1 1;
BA_ "U_T6_MCA_MY2020_Rx" SG_ 65 immoControlData_T1 1;
BA_ "U_P702_MY2021_Rx" SG_ 65 immoControlData_T1 1;
BA_ "U_CD542_MY2021_Rx" SG_ 65 immoControlData_T1 1;
BA_ "U_CX727_MY2021_Rx" SG_ 65 immoControlData_T1 1;
BA_ "U_U55X_MY2022_Rx" SG_ 65 immoControlCmd_T1 1;
BA_ "U_T6_MCA_MY2020_Rx" SG_ 65 immoControlCmd_T1 1;
BA_ "U_P702_MY2021_Rx" SG_ 65 immoControlCmd_T1 1;
BA_ "U_CD542_MY2021_Rx" SG_ 65 immoControlCmd_T1 1;
BA_ "U_CX727_MY2021_Rx" SG_ 65 immoControlCmd_T1 1;
BA_ "U_T6_MCA_MY2020_Rx" SG_ 1076 AutoRgen_D_Rq 1;
BA_ "U_P702_MY2021_Rx" SG_ 1076 AutoRgen_D_Rq 1;
BA_ "U_T6_MCA_MY2020_Rx" SG_ 1076 W2S_LAMP_OK 1;
BA_ "GenSigStartValue" SG_ 1076 W2S_LAMP_OK 1;
BA_ "GenSigStartValueInteger" SG_ 1076 W2S_LAMP_OK 1;
BA_ "U_CX727_MY2021_Rx" SG_ 1076 OdoTripRx_B_Actl 1;
BA_ "U_U55X_MY2022_Rx" SG_ 1076 OdoTripRx_B_Actl 1;
BA_ "U_CD542_MY2021_Rx" SG_ 1076 OdoTripRx_B_Actl 1;
BA_ "U_T6_MCA_MY2020_Rx" SG_ 1076 OdoTripRx_B_Actl 1;
BA_ "U_P702_MY2021_Rx" SG_ 1076 OdoTripRx_B_Actl 1;
BA_ "U_CX727_MY2021_Rx" SG_ 1076 Veh_V_CompLimMx 1;
BA_ "U_U55X_MY2022_Rx" SG_ 1076 Veh_V_CompLimMx 1;
BA_ "U_CD542_MY2021_Rx" SG_ 1076 Veh_V_CompLimMx 1;
BA_ "U_T6_MCA_MY2020_Rx" SG_ 1076 Veh_V_CompLimMx 1;
BA_ "U_P702_MY2021_Rx" SG_ 1076 Veh_V_CompLimMx 1;
BA_ "GenSigStartValue" SG_ 1076 Veh_V_CompLimMx 4093;
BA_ "GenSigStartValueInteger" SG_ 1076 Veh_V_CompLimMx 4095;
BA_ "U_U55X_MY2022_Rx" SG_ 1076 DrvSlipCtlMde_B_RqMyKey 1;
BA_ "U_CD542_MY2021_Rx" SG_ 1076 DrvSlipCtlMde_B_RqMyKey 1;
BA_ "U_T6_MCA_MY2020_Rx" SG_ 1076 DrvSlipCtlMde_B_RqMyKey 1;
BA_ "U_CX727_MY2021_Rx" SG_ 1076 DrvSlipCtlMde_B_RqMyKey 1;
BA_ "U_U55X_MY2022_Rx" SG_ 1076 HILL_DESC_SW 1;
BA_ "U_T6_MCA_MY2020_Rx" SG_ 1076 HILL_DESC_SW 1;
BA_ "U_P702_MY2021_Rx" SG_ 1076 HILL_DESC_SW 1;
BA_ "U_CX727_MY2021_Rx" SG_ 1076 FuelLvlPssvSide_No_Raw 1;
BA_ "U_U55X_MY2022_Rx" SG_ 1076 FuelLvlPssvSide_No_Raw 1;
BA_ "U_CD542_MY2021_Rx" SG_ 1076 FuelLvlPssvSide_No_Raw 1;
BA_ "U_T6_MCA_MY2020_Rx" SG_ 1076 FuelLvlPssvSide_No_Raw 1;
BA_ "U_P702_MY2021_Rx" SG_ 1076 FuelLvlPssvSide_No_Raw 1;
BA_ "U_CX727_MY2021_Rx" SG_ 1076 FUEL_SENSOR_NUM 1;
BA_ "U_U55X_MY2022_Rx" SG_ 1076 FUEL_SENSOR_NUM 1;
BA_ "U_CD542_MY2021_Rx" SG_ 1076 FUEL_SENSOR_NUM 1;
BA_ "U_T6_MCA_MY2020_Rx" SG_ 1076 FUEL_SENSOR_NUM 1;
BA_ "U_P702_MY2021_Rx" SG_ 1076 FUEL_SENSOR_NUM 1;
BA_ "U_CX727_MY2021_Rx" SG_ 1076 FuelLvlActvSide_No_Raw 1;
BA_ "U_U55X_MY2022_Rx" SG_ 1076 FuelLvlActvSide_No_Raw 1;
BA_ "U_CD542_MY2021_Rx" SG_ 1076 FuelLvlActvSide_No_Raw 1;
BA_ "U_T6_MCA_MY2020_Rx" SG_ 1076 FuelLvlActvSide_No_Raw 1;
BA_ "U_P702_MY2021_Rx" SG_ 1076 FuelLvlActvSide_No_Raw 1;
BA_ "U_T6_MCA_MY2020_Rx" SG_ 1076 FuelLvl_Pc_Dsply 1;
BA_ "U_P702_MY2021_Rx" SG_ 1076 FuelLvl_Pc_Dsply 1;
BA_ "U_CX727_MY2021_Rx" SG_ 1076 DISPLAY_SPEED_SCALING 1;
BA_ "U_U55X_MY2022_Rx" SG_ 1076 DISPLAY_SPEED_SCALING 1;
BA_ "U_CD542_MY2021_Rx" SG_ 1076 DISPLAY_SPEED_SCALING 1;
BA_ "U_T6_MCA_MY2020_Rx" SG_ 1076 DISPLAY_SPEED_SCALING 1;
BA_ "U_P702_MY2021_Rx" SG_ 1076 DISPLAY_SPEED_SCALING 1;
BA_ "U_CX727_MY2021_Rx" SG_ 1076 DISPLAY_SPEED_OFFSET 1;
BA_ "U_U55X_MY2022_Rx" SG_ 1076 DISPLAY_SPEED_OFFSET 1;
BA_ "U_CD542_MY2021_Rx" SG_ 1076 DISPLAY_SPEED_OFFSET 1;
BA_ "U_T6_MCA_MY2020_Rx" SG_ 1076 DISPLAY_SPEED_OFFSET 1;
BA_ "U_P702_MY2021_Rx" SG_ 1076 DISPLAY_SPEED_OFFSET 1;
BA_ "ContentDependant" SG_ 836 Foh_D_Stat 1;
BA_ "WakeupSignal" SG_ 836 Foh_D_Stat 1;
BA_ "ContentDependant" SG_ 836 FuelFlw_Vl_ActlFoh 1;
BA_ "ContentDependant" SG_ 836 EngClnt_Te_ActlFoh 1;
BA_ "ContentDependant" SG_ 836 FohFalt_D_Stat 1;
BA_ "ContentDependant" SG_ 836 FohEnbl_B_RqDrv 1;
BA_ "ContentDependant" SG_ 836 FohRqRun_B_Rq 1;
BA_ "ContentDependant" SG_ 836 HvacPrecondMode_D_Rq 1;
BA_ "WakeupSignal" SG_ 836 HvacPrecondMode_D_Rq 1;
BA_ "ContentDependant" SG_ 836 HvacPrecondBlwr_D_Rq 1;
BA_ "WakeupSignal" SG_ 836 HvacPrecondBlwr_D_Rq 1;
BA_ "U_CX727_MY2021_Rx" SG_ 862 TwHlGrdAsst_B_RqTrn 1;
BA_ "U_CD542_MY2021_Rx" SG_ 862 ApaSwtch_D_RqDrv 1;
BA_ "U_CX727_MY2021_Rx" SG_ 862 HvacBlwrFront_D_Stat 1;
BA_ "U_U55X_MY2022_Rx" SG_ 862 HvacBlwrFront_D_Stat 1;
BA_ "U_CD542_MY2021_Rx" SG_ 862 HvacBlwrFront_D_Stat 1;
BA_ "U_T6_MCA_MY2020_Rx" SG_ 862 HvacBlwrFront_D_Stat 1;
BA_ "U_P702_MY2021_Rx" SG_ 862 HvacBlwrFront_D_Stat 1;
BA_ "U_CX727_MY2021_Rx" SG_ 862 HvacBlwrRear_D_Stat 1;
BA_ "U_U55X_MY2022_Rx" SG_ 862 HvacBlwrRear_D_Stat 1;
BA_ "U_CD542_MY2021_Rx" SG_ 862 HvacBlwrRear_D_Stat 1;
BA_ "U_T6_MCA_MY2020_Rx" SG_ 862 HvacBlwrRear_D_Stat 1;
BA_ "U_P702_MY2021_Rx" SG_ 862 HvacBlwrRear_D_Stat 1;
BA_ "U_CD542_MY2021_Rx" SG_ 862 CabnAmb_Te_Actl 1;
BA_ "U_P702_MY2021_Rx" SG_ 862 CabnAmb_Te_Actl 1;
BA_ "U_CX727_MY2021_Rx" SG_ 862 CabnAmb_Te_Actl 1;
BA_ "GenSigStartValueInteger" SG_ 862 CabnAmb_Te_Actl 114;
BA_ "U_CX727_MY2021_Rx" SG_ 862 HvacRemoteStrt_N_Rq 1;
BA_ "U_U55X_MY2022_Rx" SG_ 862 HvacRemoteStrt_N_Rq 1;
BA_ "U_CD542_MY2021_Rx" SG_ 862 HvacRemoteStrt_N_Rq 1;
BA_ "U_T6_MCA_MY2020_Rx" SG_ 862 HvacRemoteStrt_N_Rq 1;
BA_ "U_P702_MY2021_Rx" SG_ 862 HvacRemoteStrt_N_Rq 1;
BA_ "U_CD542_MY2021_Rx" SG_ 862 ClimtThrmlLoad_No_Actl 1;
BA_ "U_P702_MY2021_Rx" SG_ 862 ClimtThrmlLoad_No_Actl 1;
BA_ "U_CX727_MY2021_Rx" SG_ 862 ClimtThrmlLoad_No_Actl 1;
BA_ "GenSigStartValue" SG_ 862 ClimtThrmlLoad_No_Actl 255;
BA_ "GenSigStartValueInteger" SG_ 862 ClimtThrmlLoad_No_Actl 255;
BA_ "U_CD542_MY2021_Rx" SG_ 862 HvacRec_Pc_Est 1;
BA_ "U_P702_MY2021_Rx" SG_ 862 HvacRec_Pc_Est 1;
BA_ "U_CX727_MY2021_Rx" SG_ 862 HvacRec_Pc_Est 1;
BA_ "GenSigStartValueInteger" SG_ 862 AutoStpHvacDelta_I_Est 192;
BA_ "U_CD542_MY2021_Rx" SG_ 862 HvacAir_Flw_Est 1;
BA_ "U_P702_MY2021_Rx" SG_ 862 HvacAir_Flw_Est 1;
BA_ "U_CX727_MY2021_Rx" SG_ 862 HvacAir_Flw_Est 1;
BA_ "MetaData" SG_ 862 ApaSwtch_No_Cnt 1;
BA_ "U_U55X_MY2022_Rx" SG_ 931 VehOnSrc_D_Stat 1;
BA_ "U_CD542_MY2021_Rx" SG_ 931 VehOnSrc_D_Stat 1;
BA_ "U_T6_MCA_MY2020_Rx" SG_ 931 VehOnSrc_D_Stat 1;
BA_ "U_P702_MY2021_Rx" SG_ 931 VehOnSrc_D_Stat 1;
BA_ "U_U55X_MY2022_Rx" SG_ 931 StrtrMtrCtlDStat_No_Cs 1;
BA_ "U_CD542_MY2021_Rx" SG_ 931 StrtrMtrCtlDStat_No_Cs 1;
BA_ "U_T6_MCA_MY2020_Rx" SG_ 931 StrtrMtrCtlDStat_No_Cs 1;
BA_ "U_P702_MY2021_Rx" SG_ 931 StrtrMtrCtlDStat_No_Cs 1;
BA_ "MetaData" SG_ 931 StrtrMtrCtlDStat_No_Cs 1;
BA_ "U_U55X_MY2022_Rx" SG_ 931 EngStrtActv_B_Stat 1;
BA_ "U_CD542_MY2021_Rx" SG_ 931 EngStrtActv_B_Stat 1;
BA_ "U_T6_MCA_MY2020_Rx" SG_ 931 EngStrtActv_B_Stat 1;
BA_ "U_P702_MY2021_Rx" SG_ 931 EngStrtActv_B_Stat 1;
BA_ "U_U55X_MY2022_Rx" SG_ 931 EngStrt_B_Rq 1;
BA_ "U_CD542_MY2021_Rx" SG_ 931 EngStrt_B_Rq 1;
BA_ "U_T6_MCA_MY2020_Rx" SG_ 931 EngStrt_B_Rq 1;
BA_ "U_P702_MY2021_Rx" SG_ 931 EngStrt_B_Rq 1;
BA_ "U_U55X_MY2022_Rx" SG_ 931 DrvInCtl_B_Stat 1;
BA_ "U_CD542_MY2021_Rx" SG_ 931 DrvInCtl_B_Stat 1;
BA_ "U_T6_MCA_MY2020_Rx" SG_ 931 DrvInCtl_B_Stat 1;
BA_ "U_P702_MY2021_Rx" SG_ 931 DrvInCtl_B_Stat 1;
BA_ "U_CD542_MY2021_Rx" SG_ 931 PtWakeReas_D_Stat 1;
BA_ "U_P702_MY2021_Rx" SG_ 931 PtWakeReas_D_Stat 1;
BA_ "U_CX727_MY2021_Rx" SG_ 931 CrnkInhbt_No_Cs 1;
BA_ "U_U55X_MY2022_Rx" SG_ 931 CrnkInhbt_No_Cs 1;
BA_ "U_CD542_MY2021_Rx" SG_ 931 CrnkInhbt_No_Cs 1;
BA_ "U_T6_MCA_MY2020_Rx" SG_ 931 CrnkInhbt_No_Cs 1;
BA_ "U_P702_MY2021_Rx" SG_ 931 CrnkInhbt_No_Cs 1;
BA_ "MetaData" SG_ 931 CrnkInhbt_No_Cs 1;
BA_ "ContentDependant" SG_ 931 CrnkInhbt_No_Cs 1;
BA_ "U_CX727_MY2021_Rx" SG_ 931 CrnkInhbt_No_Cnt 1;
BA_ "U_U55X_MY2022_Rx" SG_ 931 CrnkInhbt_No_Cnt 1;
BA_ "U_CD542_MY2021_Rx" SG_ 931 CrnkInhbt_No_Cnt 1;
BA_ "U_T6_MCA_MY2020_Rx" SG_ 931 CrnkInhbt_No_Cnt 1;
BA_ "U_P702_MY2021_Rx" SG_ 931 CrnkInhbt_No_Cnt 1;
BA_ "MetaData" SG_ 931 CrnkInhbt_No_Cnt 1;
BA_ "ContentDependant" SG_ 931 CrnkInhbt_No_Cnt 1;
BA_ "U_CX727_MY2021_Rx" SG_ 931 CrnkInhbt_B_Stat 1;
BA_ "U_U55X_MY2022_Rx" SG_ 931 CrnkInhbt_B_Stat 1;
BA_ "U_CD542_MY2021_Rx" SG_ 931 CrnkInhbt_B_Stat 1;
BA_ "U_T6_MCA_MY2020_Rx" SG_ 931 CrnkInhbt_B_Stat 1;
BA_ "U_P702_MY2021_Rx" SG_ 931 CrnkInhbt_B_Stat 1;
BA_ "GenSigStartValue" SG_ 931 CrnkInhbt_B_Stat 1;
BA_ "GenSigStartValueInteger" SG_ 931 CrnkInhbt_B_Stat 1;
BA_ "U_U55X_MY2022_Rx" SG_ 931 IgnPreOffActv_B_Stat 1;
BA_ "U_CD542_MY2021_Rx" SG_ 931 IgnPreOffActv_B_Stat 1;
BA_ "U_T6_MCA_MY2020_Rx" SG_ 931 IgnPreOffActv_B_Stat 1;
BA_ "U_P702_MY2021_Rx" SG_ 931 IgnPreOffActv_B_Stat 1;
BA_ "U_T6_MCA_MY2020_Rx" SG_ 931 AdvStrt_No_Stat 1;
BA_ "U_U55X_MY2022_Rx" SG_ 931 AdvStrt_No_Stat 1;
BA_ "U_U55X_MY2022_Rx" SG_ 578 PtLatchActv_B_RqBcm 1;
BA_ "U_T6_MCA_MY2020_Rx" SG_ 578 PtLatchActv_B_RqBcm 1;
BA_ "U_P702_MY2021_Rx" SG_ 578 PtLatchActv_B_RqBcm 1;
BA_ "U_CD542_MY2021_Rx" SG_ 578 PtLatchActv_B_RqBcm 1;
BA_ "U_CX727_MY2021_Rx" SG_ 578 PtLatchActv_B_RqBcm 1;
BA_ "U_U55X_MY2022_Rx" SG_ 578 immoSecureIdleMode 1;
BA_ "U_T6_MCA_MY2020_Rx" SG_ 578 immoSecureIdleMode 1;
BA_ "U_P702_MY2021_Rx" SG_ 578 immoSecureIdleMode 1;
BA_ "U_CD542_MY2021_Rx" SG_ 578 immoSecureIdleMode 1;
BA_ "U_CX727_MY2021_Rx" SG_ 578 immoSecureIdleMode 1;
BA_ "U_CD542_MY2021_Rx" SG_ 578 ReFuelSwtchStat_D_Actl 1;
BA_ "U_CX727_MY2021_Rx" SG_ 578 ReFuelSwtchStat_D_Actl 1;
BA_ "WakeupSignal" SG_ 578 ReFuelSwtchStat_D_Actl 1;
BA_ "U_CX727_MY2021_Rx" SG_ 578 FuelPumpPwr_D_Stat 1;
BA_ "U_U55X_MY2022_Rx" SG_ 578 FuelPumpPwr_D_Stat 1;
BA_ "U_CD542_MY2021_Rx" SG_ 578 FuelPumpPwr_D_Stat 1;
BA_ "U_T6_MCA_MY2020_Rx" SG_ 578 FuelPumpPwr_D_Stat 1;
BA_ "U_P702_MY2021_Rx" SG_ 578 FuelPumpPwr_D_Stat 1;
BA_ "U_U55X_MY2022_Rx" SG_ 578 BattULo_U_Actl 1;
BA_ "U_T6_MCA_MY2020_Rx" SG_ 578 BattULo_U_Actl 1;
BA_ "U_CD542_MY2021_Rx" SG_ 578 BattULo_U_Actl 1;
BA_ "U_P702_MY2021_Rx" SG_ 578 BattULo_U_Actl 1;
BA_ "U_CX727_MY2021_Rx" SG_ 578 BattULo_U_Actl 1;
BA_ "GenSigStartValue" SG_ 578 BattULo_U_Actl 255;
BA_ "GenSigStartValueInteger" SG_ 578 BattULo_U_Actl 255;
BA_ "U_CD542_MY2021_Rx" SG_ 578 PrkLckCtlMsgTxt_D_Rq 1;
BA_ "U_CX727_MY2021_Rx" SG_ 578 PrkLckCtlMsgTxt_D_Rq 1;
BA_ "WakeupSignal" SG_ 578 PrkLckCtlMsgTxt_D_Rq 1;
BA_ "WakeupSignal" SG_ 578 PrkLckCtlAvail_T_Stat 1;
BA_ "U_U55X_MY2022_Rx" SG_ 578 BrkTrnShifLck_B_Stat 1;
BA_ "U_T6_MCA_MY2020_Rx" SG_ 578 BrkTrnShifLck_B_Stat 1;
BA_ "U_P702_MY2021_Rx" SG_ 578 BrkTrnShifLck_B_Stat 1;
BA_ "U_CD542_MY2021_Rx" SG_ 578 BrkTrnShifLck_B_Stat 1;
BA_ "U_CX727_MY2021_Rx" SG_ 578 BrkTrnShifLck_B_Stat 1;
BA_ "U_CX727_MY2021_Rx" SG_ 578 DriverCrankingReq 1;
BA_ "U_U55X_MY2022_Rx" SG_ 578 DriverCrankingReq 1;
BA_ "U_CD542_MY2021_Rx" SG_ 578 DriverCrankingReq 1;
BA_ "U_T6_MCA_MY2020_Rx" SG_ 578 DriverCrankingReq 1;
BA_ "U_P702_MY2021_Rx" SG_ 578 DriverCrankingReq 1;
BA_ "U_CX727_MY2021_Rx" SG_ 578 EngOff_T_Actl 1;
BA_ "U_U55X_MY2022_Rx" SG_ 578 EngOff_T_Actl 1;
BA_ "U_CD542_MY2021_Rx" SG_ 578 EngOff_T_Actl 1;
BA_ "U_P702_MY2021_Rx" SG_ 578 EngOff_T_Actl 1;
BA_ "U_T6_MCA_MY2020_Rx" SG_ 578 EngOff_T_Actl 1;
BA_ "U_U55X_MY2022_Rx" SG_ 578 DcacElPw_D_Rq 1;
BA_ "U_CD542_MY2021_Rx" SG_ 578 DcacElPw_D_Rq 1;
BA_ "U_T6_MCA_MY2020_Rx" SG_ 578 DcacElPw_D_Rq 1;
BA_ "U_P702_MY2021_Rx" SG_ 578 DcacElPw_D_Rq 1;
BA_ "U_CX727_MY2021_Rx" SG_ 578 BattULo_I_Actl 1;
BA_ "U_U55X_MY2022_Rx" SG_ 578 BattULo_I_Actl 1;
BA_ "U_CD542_MY2021_Rx" SG_ 578 BattULo_I_Actl 1;
BA_ "U_T6_MCA_MY2020_Rx" SG_ 578 BattULo_I_Actl 1;
BA_ "U_P702_MY2021_Rx" SG_ 578 BattULo_I_Actl 1;
BA_ "GenSigStartValue" SG_ 578 BattULo_I_Actl 16383;
BA_ "GenSigStartValueInteger" SG_ 578 BattULo_I_Actl 16383;
BA_ "WakeupSignal" SG_ 947 DimmingLvlEvnt_No_Actl 1;
BA_ "U_U55X_MY2022_Rx" SG_ 947 DrStatDrvErrCnt_B_Stat 1;
BA_ "U_CD542_MY2021_Rx" SG_ 947 DrStatDrvErrCnt_B_Stat 1;
BA_ "U_T6_MCA_MY2020_Rx" SG_ 947 DrStatDrvErrCnt_B_Stat 1;
BA_ "U_P702_MY2021_Rx" SG_ 947 DrStatDrvErrCnt_B_Stat 1;
BA_ "U_P702_MY2021_Rx" SG_ 947 TurnLghtRight_D_Rq 1;
BA_ "U_CX727_MY2021_Rx" SG_ 947 TurnLghtRight_D_Rq 1;
BA_ "U_CD542_MY2021_Rx" SG_ 947 TurnLghtRight_D_Rq 1;
BA_ "U_T6_MCA_MY2020_Rx" SG_ 947 TurnLghtRight_D_Rq 1;
BA_ "WakeupSignal" SG_ 947 TurnLghtRight_D_Rq 1;
BA_ "U_P702_MY2021_Rx" SG_ 947 FogLghtRearOn_B_Stat 1;
BA_ "U_CX727_MY2021_Rx" SG_ 947 FogLghtRearOn_B_Stat 1;
BA_ "U_CD542_MY2021_Rx" SG_ 947 FogLghtRearOn_B_Stat 1;
BA_ "U_T6_MCA_MY2020_Rx" SG_ 947 FogLghtRearOn_B_Stat 1;
BA_ "WakeupSignal" SG_ 947 Backlit_LED_Status 1;
BA_ "U_P702_MY2021_Rx" SG_ 947 TurnLghtLeft_D_Rq 1;
BA_ "U_CX727_MY2021_Rx" SG_ 947 TurnLghtLeft_D_Rq 1;
BA_ "U_CD542_MY2021_Rx" SG_ 947 TurnLghtLeft_D_Rq 1;
BA_ "U_T6_MCA_MY2020_Rx" SG_ 947 TurnLghtLeft_D_Rq 1;
BA_ "WakeupSignal" SG_ 947 TurnLghtLeft_D_Rq 1;
BA_ "U_P702_MY2021_Rx" SG_ 947 FogLghtFrontOn_B_Stat 1;
BA_ "U_CX727_MY2021_Rx" SG_ 947 FogLghtFrontOn_B_Stat 1;
BA_ "U_CD542_MY2021_Rx" SG_ 947 FogLghtFrontOn_B_Stat 1;
BA_ "U_T6_MCA_MY2020_Rx" SG_ 947 FogLghtFrontOn_B_Stat 1;
BA_ "U_CX727_MY2021_Rx" SG_ 947 IgnKeyType_D_Actl 1;
BA_ "U_U55X_MY2022_Rx" SG_ 947 IgnKeyType_D_Actl 1;
BA_ "U_CD542_MY2021_Rx" SG_ 947 IgnKeyType_D_Actl 1;
BA_ "U_T6_MCA_MY2020_Rx" SG_ 947 IgnKeyType_D_Actl 1;
BA_ "U_P702_MY2021_Rx" SG_ 947 IgnKeyType_D_Actl 1;
BA_ "GenSigStartValue" SG_ 947 IgnKeyType_D_Actl 14;
BA_ "GenSigStartValueInteger" SG_ 947 IgnKeyType_D_Actl 14;
BA_ "U_CD542_MY2021_Rx" SG_ 947 Parklamp_Status 1;
BA_ "U_T6_MCA_MY2020_Rx" SG_ 947 Parklamp_Status 1;
BA_ "GenSigStartValue" SG_ 947 Parklamp_Status 1;
BA_ "GenSigStartValueInteger" SG_ 947 Parklamp_Status 1;
BA_ "WakeupSignal" SG_ 947 Parklamp_Status 1;
BA_ "U_P702_MY2021_Rx" SG_ 947 Litval 1;
BA_ "U_CX727_MY2021_Rx" SG_ 947 Litval 1;
BA_ "U_CD542_MY2021_Rx" SG_ 947 Litval 1;
BA_ "U_T6_MCA_MY2020_Rx" SG_ 947 Litval 1;
BA_ "WakeupSignal" SG_ 947 Litval 1;
BA_ "U_U55X_MY2022_Rx" SG_ 947 Key_In_Ignition_Stat 1;
BA_ "U_CD542_MY2021_Rx" SG_ 947 Key_In_Ignition_Stat 1;
BA_ "U_T6_MCA_MY2020_Rx" SG_ 947 Key_In_Ignition_Stat 1;
BA_ "U_P702_MY2021_Rx" SG_ 947 Key_In_Ignition_Stat 1;
BA_ "U_CX727_MY2021_Rx" SG_ 947 Key_In_Ignition_Stat 1;
BA_ "WakeupSignal" SG_ 947 Key_In_Ignition_Stat 1;
BA_ "U_U55X_MY2022_Rx" SG_ 947 Ignition_Status 1;
BA_ "U_CD542_MY2021_Rx" SG_ 947 Ignition_Status 1;
BA_ "U_P702_MY2021_Rx" SG_ 947 Ignition_Status 1;
BA_ "U_CX727_MY2021_Rx" SG_ 947 Ignition_Status 1;
BA_ "U_T6_MCA_MY2020_Rx" SG_ 947 Ignition_Status 1;
BA_ "WakeupSignal" SG_ 947 Ignition_Status 1;
BA_ "U_CD542_MY2021_Rx" SG_ 947 Dimming_Lvl 1;
BA_ "U_T6_MCA_MY2020_Rx" SG_ 947 Dimming_Lvl 1;
BA_ "GenSigStartValue" SG_ 947 Dimming_Lvl 12;
BA_ "GenSigStartValueInteger" SG_ 947 Dimming_Lvl 12;
BA_ "WakeupSignal" SG_ 947 Dimming_Lvl 1;
BA_ "U_U55X_MY2022_Rx" SG_ 947 Day_Night_Status 1;
BA_ "U_CD542_MY2021_Rx" SG_ 947 Day_Night_Status 1;
BA_ "U_P702_MY2021_Rx" SG_ 947 Day_Night_Status 1;
BA_ "U_T6_MCA_MY2020_Rx" SG_ 947 Day_Night_Status 1;
BA_ "WakeupSignal" SG_ 947 Day_Night_Status 1;
BA_ "U_CD542_MY2021_Rx" SG_ 947 Remote_Start_Status 1;
BA_ "U_T6_MCA_MY2020_Rx" SG_ 947 Remote_Start_Status 1;
BA_ "WakeupSignal" SG_ 947 Remote_Start_Status 1;
BA_ "U_CD542_MY2021_Rx" SG_ 947 DrStatTgate_B_Actl 1;
BA_ "U_T6_MCA_MY2020_Rx" SG_ 947 DrStatTgate_B_Actl 1;
BA_ "WakeupSignal" SG_ 947 DrStatTgate_B_Actl 1;
BA_ "U_U55X_MY2022_Rx" SG_ 947 DrStatRr_B_Actl 1;
BA_ "U_P702_MY2021_Rx" SG_ 947 DrStatRr_B_Actl 1;
BA_ "U_CD542_MY2021_Rx" SG_ 947 DrStatRr_B_Actl 1;
BA_ "U_T6_MCA_MY2020_Rx" SG_ 947 DrStatRr_B_Actl 1;
BA_ "WakeupSignal" SG_ 947 DrStatRr_B_Actl 1;
BA_ "U_U55X_MY2022_Rx" SG_ 947 DrStatRl_B_Actl 1;
BA_ "U_P702_MY2021_Rx" SG_ 947 DrStatRl_B_Actl 1;
BA_ "U_CD542_MY2021_Rx" SG_ 947 DrStatRl_B_Actl 1;
BA_ "U_T6_MCA_MY2020_Rx" SG_ 947 DrStatRl_B_Actl 1;
BA_ "WakeupSignal" SG_ 947 DrStatRl_B_Actl 1;
BA_ "U_U55X_MY2022_Rx" SG_ 947 DrStatPsngr_B_Actl 1;
BA_ "U_P702_MY2021_Rx" SG_ 947 DrStatPsngr_B_Actl 1;
BA_ "U_CD542_MY2021_Rx" SG_ 947 DrStatPsngr_B_Actl 1;
BA_ "U_T6_MCA_MY2020_Rx" SG_ 947 DrStatPsngr_B_Actl 1;
BA_ "WakeupSignal" SG_ 947 DrStatPsngr_B_Actl 1;
BA_ "U_CD542_MY2021_Rx" SG_ 947 DrStatInnrTgate_B_Actl 1;
BA_ "U_T6_MCA_MY2020_Rx" SG_ 947 DrStatInnrTgate_B_Actl 1;
BA_ "WakeupSignal" SG_ 947 DrStatInnrTgate_B_Actl 1;
BA_ "WakeupSignal" SG_ 947 DrStatHood_B_Actl 1;
BA_ "U_CX727_MY2021_Rx" SG_ 947 DrStatDrv_B_Actl 1;
BA_ "U_U55X_MY2022_Rx" SG_ 947 DrStatDrv_B_Actl 1;
BA_ "U_CD542_MY2021_Rx" SG_ 947 DrStatDrv_B_Actl 1;
BA_ "U_T6_MCA_MY2020_Rx" SG_ 947 DrStatDrv_B_Actl 1;
BA_ "U_P702_MY2021_Rx" SG_ 947 DrStatDrv_B_Actl 1;
BA_ "WakeupSignal" SG_ 947 DrStatDrv_B_Actl 1;
BA_ "U_U55X_MY2022_Rx" SG_ 947 PrkBrkActv_B_Actl 1;
BA_ "U_P702_MY2021_Rx" SG_ 947 PrkBrkActv_B_Actl 1;
BA_ "U_T6_MCA_MY2020_Rx" SG_ 947 PrkBrkActv_B_Actl 1;
BA_ "U_CD542_MY2021_Rx" SG_ 947 PrkBrkActv_B_Actl 1;
BA_ "U_CX727_MY2021_Rx" SG_ 947 PrkBrkActv_B_Actl 1;
BA_ "ContentDependant" SG_ 947 PrkBrkActv_B_Actl 1;
BA_ "WakeupSignal" SG_ 947 PrkBrkActv_B_Actl 1;
BA_ "U_U55X_MY2022_Rx" SG_ 947 LifeCycMde_D_Actl 1;
BA_ "U_T6_MCA_MY2020_Rx" SG_ 947 LifeCycMde_D_Actl 1;
BA_ "U_CD542_MY2021_Rx" SG_ 947 LifeCycMde_D_Actl 1;
BA_ "U_P702_MY2021_Rx" SG_ 947 LifeCycMde_D_Actl 1;
BA_ "U_CX727_MY2021_Rx" SG_ 947 LifeCycMde_D_Actl 1;
BA_ "WakeupSignal" SG_ 947 Delay_Accy 1;
BA_ "GenSigStartValue" SG_ 947 CrashEvnt_D_Stat 3;
BA_ "GenSigStartValueInteger" SG_ 947 CrashEvnt_D_Stat 3;
BA_ "WakeupSignal" SG_ 947 CrashEvnt_D_Stat 1;
BA_ "U_CX727_MY2021_Rx" SG_ 1084 BattULoChrg_URate_RqMx 1;
BA_ "U_U55X_MY2022_Rx" SG_ 1084 BattULoChrg_URate_RqMx 1;
BA_ "U_CD542_MY2021_Rx" SG_ 1084 BattULoChrg_URate_RqMx 1;
BA_ "U_T6_MCA_MY2020_Rx" SG_ 1084 BattULoChrg_URate_RqMx 1;
BA_ "U_P702_MY2021_Rx" SG_ 1084 BattULoChrg_URate_RqMx 1;
BA_ "GenSigStartValue" SG_ 1084 BattULoChrg_URate_RqMx 5;
BA_ "GenSigStartValueInteger" SG_ 1084 BattULoChrg_URate_RqMx 5;
BA_ "U_U55X_MY2022_Rx" SG_ 1084 BattULoChrg_U_RqMx 1;
BA_ "U_CD542_MY2021_Rx" SG_ 1084 BattULoChrg_U_RqMx 1;
BA_ "U_T6_MCA_MY2020_Rx" SG_ 1084 BattULoChrg_U_RqMx 1;
BA_ "U_P702_MY2021_Rx" SG_ 1084 BattULoChrg_U_RqMx 1;
BA_ "GenSigStartValue" SG_ 1084 BattULoChrg_U_RqMx 34;
BA_ "GenSigStartValueInteger" SG_ 1084 BattULoChrg_U_RqMx 34;
BA_ "U_U55X_MY2022_Rx" SG_ 1084 BattULoChrg_U_RqMn 1;
BA_ "U_CD542_MY2021_Rx" SG_ 1084 BattULoChrg_U_RqMn 1;
BA_ "U_T6_MCA_MY2020_Rx" SG_ 1084 BattULoChrg_U_RqMn 1;
BA_ "U_P702_MY2021_Rx" SG_ 1084 BattULoChrg_U_RqMn 1;
BA_ "U_U55X_MY2022_Rx" SG_ 1084 BattULoState_D_Qlty 1;
BA_ "U_CD542_MY2021_Rx" SG_ 1084 BattULoState_D_Qlty 1;
BA_ "U_T6_MCA_MY2020_Rx" SG_ 1084 BattULoState_D_Qlty 1;
BA_ "U_P702_MY2021_Rx" SG_ 1084 BattULoState_D_Qlty 1;
BA_ "U_U55X_MY2022_Rx" SG_ 1084 BSFault 1;
BA_ "U_CD542_MY2021_Rx" SG_ 1084 BSFault 1;
BA_ "U_T6_MCA_MY2020_Rx" SG_ 1084 BSFault 1;
BA_ "U_P702_MY2021_Rx" SG_ 1084 BSFault 1;
BA_ "U_CX727_MY2021_Rx" SG_ 1084 BattULo2_Te_Actl 1;
BA_ "U_U55X_MY2022_Rx" SG_ 1084 BattULo2_Te_Actl 1;
BA_ "U_CD542_MY2021_Rx" SG_ 1084 BattULo2_Te_Actl 1;
BA_ "U_T6_MCA_MY2020_Rx" SG_ 1084 BattULo2_Te_Actl 1;
BA_ "U_P702_MY2021_Rx" SG_ 1084 BattULo2_Te_Actl 1;
BA_ "GenSigStartValue" SG_ 1084 BattULo2_Te_Actl 127;
BA_ "GenSigStartValueInteger" SG_ 1084 BattULo2_Te_Actl 127;
BA_ "U_CX727_MY2021_Rx" SG_ 1084 BSBattSOC 1;
BA_ "U_U55X_MY2022_Rx" SG_ 1084 BSBattSOC 1;
BA_ "U_CD542_MY2021_Rx" SG_ 1084 BSBattSOC 1;
BA_ "U_T6_MCA_MY2020_Rx" SG_ 1084 BSBattSOC 1;
BA_ "U_P702_MY2021_Rx" SG_ 1084 BSBattSOC 1;
BA_ "U_U55X_MY2022_Rx" SG_ 1084 BSBattQDeltaRideAh 1;
BA_ "U_CD542_MY2021_Rx" SG_ 1084 BSBattQDeltaRideAh 1;
BA_ "U_T6_MCA_MY2020_Rx" SG_ 1084 BSBattQDeltaRideAh 1;
BA_ "U_P702_MY2021_Rx" SG_ 1084 BSBattQDeltaRideAh 1;
BA_ "GenSigStartValueInteger" SG_ 1084 BSBattQDeltaRideAh 12800;
BA_ "U_U55X_MY2022_Rx" SG_ 1084 BSBattQCapAh 1;
BA_ "U_CD542_MY2021_Rx" SG_ 1084 BSBattQCapAh 1;
BA_ "U_T6_MCA_MY2020_Rx" SG_ 1084 BSBattQCapAh 1;
BA_ "U_P702_MY2021_Rx" SG_ 1084 BSBattQCapAh 1;
BA_ "U_U55X_MY2022_Rx" SG_ 1068 EngStrtInhbt_B_RqBatt 1;
BA_ "U_CD542_MY2021_Rx" SG_ 1068 EngStrtInhbt_B_RqBatt 1;
BA_ "U_T6_MCA_MY2020_Rx" SG_ 1068 EngStrtInhbt_B_RqBatt 1;
BA_ "U_P702_MY2021_Rx" SG_ 1068 EngStrtInhbt_B_RqBatt 1;
BA_ "U_U55X_MY2022_Rx" SG_ 1068 BattULoChrg_D_Rq 1;
BA_ "U_CD542_MY2021_Rx" SG_ 1068 BattULoChrg_D_Rq 1;
BA_ "U_T6_MCA_MY2020_Rx" SG_ 1068 BattULoChrg_D_Rq 1;
BA_ "U_P702_MY2021_Rx" SG_ 1068 BattULoChrg_D_Rq 1;
BA_ "U_CD542_MY2021_Rx" SG_ 1068 PwSysULoFalt_D_Stat 1;
BA_ "U_CX727_MY2021_Rx" SG_ 1068 PwSysULoFalt_D_Stat 1;
BA_ "WakeupSignal" SG_ 1068 PwSysULoFalt_D_Stat 1;
BA_ "U_CX727_MY2021_Rx" SG_ 1068 Shed_Feature_Group_ID 1;
BA_ "U_U55X_MY2022_Rx" SG_ 1068 Shed_Feature_Group_ID 1;
BA_ "U_P702_MY2021_Rx" SG_ 1068 Shed_Feature_Group_ID 1;
BA_ "U_CD542_MY2021_Rx" SG_ 1068 Shed_Feature_Group_ID 1;
BA_ "U_T6_MCA_MY2020_Rx" SG_ 1068 Shed_Feature_Group_ID 1;
BA_ "WakeupSignal" SG_ 1068 Shed_Feature_Group_ID 1;
BA_ "U_CX727_MY2021_Rx" SG_ 1068 Shed_Level_Req 1;
BA_ "U_U55X_MY2022_Rx" SG_ 1068 Shed_Level_Req 1;
BA_ "U_P702_MY2021_Rx" SG_ 1068 Shed_Level_Req 1;
BA_ "U_CD542_MY2021_Rx" SG_ 1068 Shed_Level_Req 1;
BA_ "U_T6_MCA_MY2020_Rx" SG_ 1068 Shed_Level_Req 1;
BA_ "WakeupSignal" SG_ 1068 Shed_Level_Req 1;
BA_ "U_CD542_MY2021_Rx" SG_ 1068 BattULoSrvc_T_Actl 1;
BA_ "U_CX727_MY2021_Rx" SG_ 1068 BattULoSrvc_T_Actl 1;
BA_ "U_U55X_MY2022_Rx" SG_ 1068 ULoRgenTestMde_B_Rq 1;
BA_ "U_CD542_MY2021_Rx" SG_ 1068 ULoRgenTestMde_B_Rq 1;
BA_ "U_T6_MCA_MY2020_Rx" SG_ 1068 ULoRgenTestMde_B_Rq 1;
BA_ "U_P702_MY2021_Rx" SG_ 1068 ULoRgenTestMde_B_Rq 1;
BA_ "U_U55X_MY2022_Rx" SG_ 1068 ChargeMode 1;
BA_ "U_CD542_MY2021_Rx" SG_ 1068 ChargeMode 1;
BA_ "U_T6_MCA_MY2020_Rx" SG_ 1068 ChargeMode 1;
BA_ "U_P702_MY2021_Rx" SG_ 1068 ChargeMode 1;
BA_ "U_T6_MCA_MY2020_Rx" SG_ 1068 PeriodicElLoad_B_Stat 1;
BA_ "U_P702_MY2021_Rx" SG_ 1068 PeriodicElLoad_B_Stat 1;
VAL_ 360 GsmSrvcRqd_B_Rq 1 "Yes" 0 "No" ;
VAL_ 360 TrnTrcmPwmSig_D_Actl 15 "Faulty" 14 "NoDataExists" 13 "NotUsed5" 12 "NotUsed4" 11 "NotUsed3" 10 "NotUsed2" 9 "NotUsed1" 8 "Default_To_Park" 7 "Neutral_Tow" 6 "Car_Wash_Mode" 5 "Manual" 4 "Drive" 3 "Neutral" 2 "Reverse" 1 "Park" 0 "No_Gear" ;
VAL_ 360 TrnGearPwmFalt_B_Actl 1 "Yes" 0 "No" ;
VAL_ 360 GearButtnStuck_B_Actl 1 "Yes" 0 "No" ;
VAL_ 331 TrnAout2_W_ActlUnfilt 65535 "Fault" 65534 "NoDataExists" ;
VAL_ 331 CmbbEngTqMn_B_ActlHtrn 1 "Active" 0 "Inactive" ;
VAL_ 331 CmbbDeny_B_ActlHtrn 1 "Yes" 0 "No" ;
VAL_ 140 CcAslButtnIndxIncPress2 1 "Button_Pressed" 0 "Button_Not_Pressed" ;
VAL_ 140 SteWhlSwtchMde_D_Stat 3 "NotUsed_2" 2 "NotUsed_1" 1 "Dialog" 0 "Domain" ;
VAL_ 140 CcAslButtnIndxDecPress2 1 "Button_Pressed" 0 "Button_Not_Pressed" ;
VAL_ 140 CcAslButtnResIncPress3 1 "Pressed" 0 "Not pressed" ;
VAL_ 140 CcButtnOnPress3 1 "Pressed" 0 "Not pressed" ;
VAL_ 140 CcButtnOnOffPress3 1 "Pressed" 0 "Not pressed" ;
VAL_ 140 CcButtnOnOffCnclPress3 1 "Pressed" 0 "Not pressed" ;
VAL_ 140 CcButtnOffPress3 1 "Pressed" 0 "Not pressed" ;
VAL_ 140 CcAsllButtnResPress3 1 "Pressed" 0 "Not pressed" ;
VAL_ 140 CcAslButtnSetPress3 1 "Pressed" 0 "Not pressed" ;
VAL_ 140 CcAslButtnSetIncPress3 1 "Pressed" 0 "Not pressed" ;
VAL_ 140 CcAslButtnSetDecPress3 1 "Pressed" 0 "Not pressed" ;
VAL_ 140 CcAslButtnResDecPress3 1 "Pressed" 0 "Not pressed" ;
VAL_ 140 CcAslButtnOnPress3 1 "Pressed" 0 "Not pressed" ;
VAL_ 140 CcAslButtnOnOffCncl3 1 "Pressed" 0 "Not pressed" ;
VAL_ 140 CcAslButtnDeny_B_Actl3 1 "Pressed" 0 "Not pressed" ;
VAL_ 140 CcAslButtnCnclPress3 1 "Pressed" 0 "Not pressed" ;
VAL_ 140 AslButtnOnOffPress3 1 "Pressed" 0 "Not pressed" ;
VAL_ 140 AslButtnOnOffCnclPress2 1 "Pressed" 0 "Not pressed" ;
VAL_ 140 CcAslButtnOffCnclPress2 1 "Button_Pressed" 0 "Button_Not_Pressed" ;
VAL_ 140 CcAslButtnCnclResPress2 1 "Button_Pressed" 0 "Button_Not_Pressed" ;
VAL_ 122 VehStrtInhbt_B_RqBatt 1 "Yes" 0 "No" ;
VAL_ 122 BattTracOffFst_D_Actl 3 "Unexpected_Contactor_Open" 2 "Restraints_Impact_Event" 1 "Interlock_Open" 0 "Normal" ;
VAL_ 122 BattTracOff_B_Actl 1 "Yes" 0 "No" ;
VAL_ 122 BattTracMil_D_Rq 3 "Not_Used" 2 "Flash" 1 "On" 0 "Off" ;
VAL_ 122 BattTracCnnct_B_Cmd 1 "Close" 0 "Open" ;
VAL_ 122 BattTrac_U_Actl 1023 "Fault" 1022 "Unknown" ;
VAL_ 122 BattTrac_I_Actl 32767 "Fault" 32766 "Unknown" ;
VAL_ 93 TrnTrcmNtmState_D_Actl 3 "Faulty" 2 "Neutral_Tow_Mode" 1 "Car_Wash_Mode" 0 "None" ;
VAL_ 93 TrnSns2Pos_Pc_Actl 1023 "Fault" ;
VAL_ 93 TrnSns1Pos_Pc_Actl 1023 "Fault" ;
VAL_ 93 TrnSecPrkStat_D_Actl 7 "Faulty" 6 "Fault_Released" 5 "Fault_Latched" 4 "Recouple_in_Progress" 3 "Mechanism_Released" 2 "RTP_in_Progress" 1 "Pending" 0 "Latched" ;
VAL_ 93 TrnNtrlTowCnfm_B_Actl 1 "Yes" 0 "No" ;
VAL_ 93 TrnGearFinalPos_B_Actl 1 "Yes" 0 "No" ;
VAL_ 93 TrnGear_D_Actl 7 "Fault" 6 "NotUsed" 5 "Manual" 4 "Drive" 3 "Neutral" 2 "Reverse" 1 "Park" 0 "Transition_State" ;
VAL_ 90 TrnGsmNtmState_D_Actl 3 "Faulty" 2 "Neutral_Tow_Mode" 1 "Car_Wash_Mode" 0 "None" ;
VAL_ 90 DrQltyDrv_D_StatGsm 7 "Faulty" 6 "NoDataExists" 5 "NotUsed2" 4 "NotUsed1" 3 "ClosedDegraded" 2 "OpenDegraded" 1 "ClosedOkay" 0 "OpenOkay" ;
VAL_ 90 TrnBtsiOvrrd_B_Stat 1 "Override" 0 "Null" ;
VAL_ 90 GsmGearMsgTxt_D_Rq 3 "Message3" 2 "Message2" 1 "Message1" 0 "NoMessage" ;
VAL_ 90 TrnRng_D_RqGsm 15 "Fault" 14 "UnknownPosition" 13 "Undefined_2" 12 "Undefined_1" 11 "_6" 10 "_5" 9 "_4" 8 "_3" 7 "_2" 6 "_1" 5 "Low" 4 "Sport_DriveSport" 3 "Drive" 2 "Neutral" 1 "Reverse" 0 "Park" ;
VAL_ 90 PrkBrkActv_D_RqGsmGear 3 "NotUsed" 2 "RequestParkBrakeEngage" 1 "NoRequest" 0 "Null" ;
VAL_ 90 TrnValidGearRq_D_Stat 3 "Valid_Request" 2 "Valid_Degraded_Request" 1 "Invalid_Request" 0 "No_Request" ;
VAL_ 90 TrnGearButtn_U_Actl 255 "Fault" ;
VAL_ 90 TrnGearButtn_B_ActlR2 1 "Yes" 0 "No" ;
VAL_ 90 TrnGearButtn_B_ActlR1 1 "Yes" 0 "No" ;
VAL_ 90 TrnGearButtn_B_ActlR0 1 "Yes" 0 "No" ;
VAL_ 90 TrnGearButtn_B_ActlP2 1 "Yes" 0 "No" ;
VAL_ 90 TrnGearButtn_B_ActlP1 1 "Yes" 0 "No" ;
VAL_ 90 TrnGearButtn_B_ActlP0 1 "Yes" 0 "No" ;
VAL_ 90 TrnGearButtn_B_ActlN2 1 "Yes" 0 "No" ;
VAL_ 90 TrnGearButtn_B_ActlN1 1 "Yes" 0 "No" ;
VAL_ 90 TrnGearButtn_B_ActlN0 1 "Yes" 0 "No" ;
VAL_ 90 TrnGearButtn_B_ActlM2 1 "Yes" 0 "No" ;
VAL_ 90 TrnGearButtn_B_ActlM1 1 "Yes" 0 "No" ;
VAL_ 90 TrnGearButtn_B_ActlM0 1 "Yes" 0 "No" ;
VAL_ 90 TrnGearButtn_B_ActlD2 1 "Yes" 0 "No" ;
VAL_ 90 TrnGearButtn_B_ActlD1 1 "Yes" 0 "No" ;
VAL_ 90 TrnGearButtn_B_ActlD0 1 "Yes" 0 "No" ;
VAL_ 90 TrnGear_D_RqDrv 31 "Fault" 30 "NotUsed_25" 29 "NotUsed_24" 28 "NotUsed_23" 27 "NotUsed_22" 26 "Return_to_Park" 25 "NotUsed_20" 24 "NotUsed_19" 23 "NotUsed_18" 22 "NotUsed_17" 21 "Return_To_Park" 20 "NotUsed_15" 19 "NotUsed_14" 18 "NotUsed_13" 17 "NotUsed_12" 16 "Manual" 15 "Not_Used11" 14 "Not_Used10" 13 "NotUsed_9" 12 "NotUsed_8" 11 "NotUsed_7" 10 "NotUsed_6" 9 "NotUsed_5" 8 "Drive" 7 "NotUsed_4" 6 "NotUsed_3" 5 "NotUsed_2" 4 "Neutral" 3 "NotUsed_1" 2 "Reverse" 1 "Park" 0 "No_Gear" ;
VAL_ 90 BrkSwtchPos_B_ActlGsm 1 "Yes" 0 "No" ;
VAL_ 1114 TrailCtlSwtch_B_Stat2 1 "Pressed" 0 "Not_Pressed" ;
VAL_ 1114 TrlBrkInitOut_D_Rq 3 "Heavy" 2 "Medium" 1 "Light" 0 "Null" ;
VAL_ 1111 TrlrYawWActl_D_Qf 3 "OK" 2 "Not_Within_Specifications" 1 "No_Data_Exists" 0 "Faulty" ;
VAL_ 1111 TrlrYaw_W_Actl 65535 "Faulty" 65534 "NoDataExists" ;
VAL_ 1111 TrlrHitYaw_AnRate_Actl 4095 "Fault" 4094 "NoDataExists" ;
VAL_ 1111 TrlrHitchYaw_D_Stat 15 "Faulty" 14 "NotUsed_4" 13 "NotUsed_3" 12 "NotUsed_2" 11 "NotUsed_1" 10 "FaultyYrsuConnection" 9 "FaultyYrsu" 8 "HiConfdLrndAngle" 7 "LowConfdLrndAngle" 6 "HiConfdAngleMem" 5 "LowConfdAngleMem" 4 "InitNoTadAngle" 3 "InitInputs" 2 "TadTrlrDataOutOfRange" 1 "TadNotWithinSpecification" 0 "NoConnectionWithYrsu" ;
VAL_ 1111 TrlrHitchYaw_An_Actl 4095 "Faulty" 4094 "NoDataExists" ;
VAL_ 1106 TrlrSnsId_No_Actl -1 "Faulty_FFFFFFFFFFFF" -2 "NoDataExists_FFFFFFFFFFFE" ;
VAL_ 1091 CamraRearOn_D2_Stat2 7 "Faulty" 6 "NotUsed_3" 5 "NotUsed_2" 4 "NotUsed_1" 3 "Decommission" 2 "Activate" 1 "Deactivate" 0 "Null" ;
VAL_ 1091 PoliceAux4Lamp_B_Rq2 1 "On" 0 "Off" ;
VAL_ 1091 PoliceAux3Lamp_B_Rq2 1 "On" 0 "Off" ;
VAL_ 1091 PoliceAux2Lamp_B_Rq2 1 "On" 0 "Off" ;
VAL_ 1091 PoliceAux1Lamp_B_Rq2 1 "On" 0 "Off" ;
VAL_ 1091 TowBarMsgTxt_D_Rq 7 "NotUsed3" 6 "NotUsed2" 5 "NotUsed1" 4 "TowBar_Ext_No_Trlr" 3 "Error_Dealer_Fix" 2 "Start_Engine_Swivel" 1 "Check_Tow_Bar" 0 "Null" ;
VAL_ 1091 ParkLampTrlrOut_B_Stat 1 "Out" 0 "Null" ;
VAL_ 1091 TrlrLampCtl_D_Stat 3 "NotUsed" 2 "TrlrLampCnnctDrvFailure" 1 "TrlrLampNotCnnctDrvFailure" 0 "Null" ;
VAL_ 1091 TrlrBattChrg_D_Stat 3 "Reverse" 2 "Normal" 1 "Low" 0 "Null" ;
VAL_ 1091 StopLampTrlrOut_B_Stat 1 "Out" 0 "Null" ;
VAL_ 1091 TurnLampTrlrRr_B_Stat 1 "Out" 0 "Null" ;
VAL_ 1091 TurnLampTrlrRl_B_Stat 1 "Out" 0 "Null" ;
VAL_ 1091 TrlrLampCnnct_B_Actl 1 "Yes" 0 "No" ;
VAL_ 1091 TrlrAlarmSpprt_D_Stat 3 "SupportedByBrakesAndLights" 2 "SupportedByLights" 1 "SupportedByBrakes" 0 "NotSupported" ;
VAL_ 138 SteWhlRelCalib_An_Sns 32767 "Fault" 32766 "NoDataExists" ;
VAL_ 131 HeadLghtHiCtrl_D_RqAhb 7 "NotUsed2" 6 "NotUsed1" 5 "Auto_HiBeam" 4 "Auto_LoBeam" 3 "Flash" 2 "Man_HiBeam" 1 "Man_LoBeam" 0 "Null" ;
VAL_ 131 AhbStat_B_Dsply 1 "On" 0 "Off" ;
VAL_ 131 WiprFrontSwtch_D_Stat 15 "NotUsed6" 14 "NotUsed5" 13 "NotUsed4" 12 "NotUsed3" 11 "NotUsed2" 10 "NotUsed1" 9 "PositionNotDetermined" 8 "High" 7 "Low" 6 "Position6" 5 "Position5" 4 "Position4" 3 "Position3" 2 "Position2" 1 "Position1" 0 "Off" ;
VAL_ 131 HeadLghtHiOn_B_StatAhb 1 "On" 0 "Off" ;
VAL_ 131 HeadLghtHiFlash_D_Actl 3 "NotUsed" 2 "High" 1 "Flash_to_Pass" 0 "Null" ;
VAL_ 131 TjaButtnOnOffPress 1 "Pressed" 0 "Not_Pressed" ;
VAL_ 131 AccButtnGapTogglePress 1 "Pressed" 0 "Not_Pressed" ;
VAL_ 131 WiprFront_D_Stat 15 "NO_DATA_EXISTS" 14 "STALLED" 13 "RESERVED" 12 "AUTO_ADJUST" 11 "COURTESYWIPE" 10 "AUTO_HIGH" 9 "AUTO_LOW" 8 "WASH" 7 "MIST_FLICK" 6 "MAN_HIGH" 5 "MAN_LOW" 4 "MAN_INT_ON" 3 "MAN_INT_OFF" 2 "OFF_MOVING" 1 "AUTO_OFF" 0 "OFF" ;
VAL_ 131 TurnLghtSwtch_D_Stat 3 "Unused_Treat_As_Off" 2 "Right" 1 "Left" 0 "Off" ;
VAL_ 131 LghtAmb_D_Sns 7 "No_Data_Exists" 6 "Unused2" 5 "Unused1" 4 "Tunnel_Off" 3 "Tunnel_On" 2 "Twilight" 1 "Light" 0 "Dark" ;
VAL_ 131 AccButtnGapIncPress 1 "Button_Pressed" 0 "Button_Not_Pressed" ;
VAL_ 131 AccButtnGapDecPress 1 "Button_Pressed" 0 "Button_Not_Pressed" ;
VAL_ 131 AslButtnOnOffPress 1 "Button_Pressed" 0 "Button_Not_Pressed" ;
VAL_ 131 AslButtnOnOffCnclPress 1 "Button_Pressed" 0 "Button_Not_Pressed" ;
VAL_ 131 CcButtnOnPress 1 "Button_Pressed" 0 "Button_Not_Pressed" ;
VAL_ 131 CcButtnOnOffPress 1 "Button_Pressed" 0 "Button_Not_Pressed" ;
VAL_ 131 CcButtnOnOffCnclPress 1 "Button_Pressed" 0 "Button_Not_Pressed" ;
VAL_ 131 CcButtnOffPress 1 "Button_Pressed" 0 "Button_Not_Pressed" ;
VAL_ 131 CcAsllButtnResPress 1 "Button_Pressed" 0 "Button_Not_Pressed" ;
VAL_ 131 CcAslButtnSetPress 1 "Button_Pressed" 0 "Button_Not_Pressed" ;
VAL_ 131 CcAslButtnSetIncPress 1 "Button_Pressed" 0 "Button_Not_Pressed" ;
VAL_ 131 CcAslButtnSetDecPress 1 "Button_Pressed" 0 "Button_Not_Pressed" ;
VAL_ 131 CcAslButtnResIncPress 1 "Button_Pressed" 0 "Button_Not_Pressed" ;
VAL_ 131 CcAslButtnResDecPress 1 "Button_Pressed" 0 "Button_Not_Pressed" ;
VAL_ 131 CcAslButtnOnPress 1 "Button_Pressed" 0 "Button_Not_Pressed" ;
VAL_ 131 CcAslButtnOnOffCncl 1 "Button_Pressed" 0 "Button_Not_Pressed" ;
VAL_ 131 CcAslButtnOffCnclPress 1 "Button_Pressed" 0 "Button_Not_Pressed" ;
VAL_ 131 CcAslButtnIndxIncPress 1 "Button_Pressed" 0 "Button_Not_Pressed" ;
VAL_ 131 CcAslButtnIndxDecPress 1 "Button_Pressed" 0 "Button_Not_Pressed" ;
VAL_ 131 CcAslButtnDeny_B_Actl 1 "Yes" 0 "No" ;
VAL_ 131 CcAslButtnCnclResPress 1 "Button_Pressed" 0 "Button_Not_Pressed" ;
VAL_ 131 CcAslButtnCnclPress 1 "Button_Pressed" 0 "Button_Not_Pressed" ;
VAL_ 131 LaSwtchPos_D_Stat 3 "Fault" 2 "Unused" 1 "Pressed" 0 "Open" ;
VAL_ 131 HeadLghtHiFlash_D_Stat 3 "NotUsed" 2 "High" 1 "Flash_to_Pass" 0 "Null" ;
VAL_ 787 DrTgateChime2_D_Rq 7 "NotUsed3" 6 "NotUsed2" 5 "NotUsed1" 4 "Long_Repeated" 3 "Fast" 2 "Short" 1 "Long" 0 "Off" ;
VAL_ 787 DrTGate_D_Rq 3 "NotUsed" 2 "Closing" 1 "Opening" 0 "Not_Moving" ;
VAL_ 787 PwLftgtIntSw_B_Stat 1 "Pressed" 0 "Null" ;
VAL_ 787 Power_Liftgate_Mode_Stt 2 "Unused" 3 "Not_Supported" 1 "Enabled" 0 "Disabled" ;
VAL_ 787 PwTgateMsgTxt_B_Rq 1 "DisplayMessage" 0 "NoMessage" ;
VAL_ 787 PwTgateLamp_B_Rq 1 "On" 0 "Off" ;
VAL_ 570 SuspClkSync_No_Rq 255 "Faulty" 254 "NoDataExists" ;
VAL_ 570 SuspRearRight_L_Actl 511 "Faulty" ;
VAL_ 570 SuspFrntRight_L_Actl 511 "Faulty" ;
VAL_ 570 SuspRear_L_Prev 511 "Fault" ;
VAL_ 570 SuspRear_L_Actl 511 "Fault" ;
VAL_ 570 SuspFrnt_L_Prev 511 "Fault" ;
VAL_ 570 SuspFrnt_L_Actl 511 "Fault" ;
VAL_ 953 PaakMyKeySearch_D_Stat 7 "PhoneErased" 6 "LockButtonTimeOut" 5 "PressLockButton" 4 "ConfirmHmi" 3 "MyKeyPaakFound" 2 "StandardPaakFound" 1 "NoValidPaakFound" 0 "Null" ;
VAL_ 953 BattULoChrgHyb_D_Stat 7 "NotUsed_4" 6 "NotUsed_3" 5 "NotUsed_2" 4 "NotUsed_1" 3 "VehicleServiceRequired" 2 "EvRangeLossDueToLoadActive" 1 "BatteryServiceRequired" 0 "Null" ;
VAL_ 953 BattULoChrgHyb_B_Rq 1 "True" 0 "False" ;
VAL_ 953 ChrgCordLck_B_Stat 1 "Unlock" 0 "Null" ;
VAL_ 953 WakeAlarm3_D_Stat 3 "PublisherReset" 2 "Wake" 1 "AlarmRunning" 0 "AlarmOff" ;
VAL_ 953 WakeAlarm2_D_Stat 3 "PublisherReset" 2 "Wake" 1 "AlarmRunning" 0 "AlarmOff" ;
VAL_ 953 WakeAlarm1_D_Stat 3 "PublisherReset" 2 "Wake" 1 "AlarmRunning" 0 "AlarmOff" ;
VAL_ 953 WakeAlarm0_D_Stat 3 "PublisherReset" 2 "Wake" 1 "AlarmRunning" 0 "AlarmOff" ;
VAL_ 953 BattRgenLoChrg_D_Rq 3 "DoNotCare" 2 "Retain" 1 "Closed" 0 "Open" ;
VAL_ 953 BattRgenLoDChrg_D_Rq 3 "DoNotCare" 2 "Retain" 1 "Closed" 0 "Open" ;
VAL_ 1101 AwdLckLamp_D_Rq 3 "Triggered" 2 "Flash" 1 "On" 0 "Off" ;
VAL_ 1101 PtLatchActv_B_RqAwd 1 "Yes" 0 "No" ;
VAL_ 1101 PtuFanOn_B_Rq 1 "On" 0 "Off" ;
VAL_ 1101 RearDiffLckLamp_D_Rq3 3 "Triggered" 2 "Flash" 1 "On" 0 "Off" ;
VAL_ 1099 RearDiff_D_Stat 15 "NotUsed_7" 14 "NotUsed_6" 13 "NotUsed_5" 12 "NotUsed_4" 11 "NotUsed_3" 10 "NotUsed_2" 9 "NotUsed_1" 8 "TorqueReqNotHonored" 7 "MissingSignal" 6 "ModuleFault" 5 "HydroTempSensorFault" 4 "ClutchPressSensorFault" 3 "AccumPressSensorFault" 2 "ControlValveFault" 1 "MotorFault" 0 "Normal" ;
VAL_ 1099 RearDiffThrml_D_Stat 3 "NotUsed_1" 2 "AboveThermalLimit" 1 "ThermalLimit" 0 "Normal" ;
VAL_ 1099 RearDiffSrvcRqd_B_Rq 1 "On" 0 "Off" ;
VAL_ 1078 UStabLvl2OvrTe_B_Stat 1 "Yes" 0 "No" ;
VAL_ 1078 UStabLvl2Ovrld_B_Stat 1 "Yes" 0 "No" ;
VAL_ 1078 UStabLvl2_D_Stat 3 "Fault" 2 "Active" 1 "Ready" 0 "Not_Ready" ;
VAL_ 1052 AwdDcnntSlipTrgt_B_Rq 1 "Request" 0 "NoRequest" ;
VAL_ 1052 AwdCnnct_D_Stat 3 "Connecting" 2 "Disconnecting" 1 "Connected" 0 "Disconnected" ;
VAL_ 1052 AwdRight_Tq_Rq 4095 "Fault" 4094 "Unknown" ;
VAL_ 1052 AwdRight_Tq_Est 4095 "Fault" 4094 "Unknown" ;
VAL_ 1052 AwdLeft_Tq_Rq 4095 "Fault" 4094 "Unknown" ;
VAL_ 1052 AwdLeft_Tq_Est 4095 "Fault" 4094 "Unknown" ;
VAL_ 1052 AwdLck_Tq_Actl 4095 "Fault" 4094 "Unknown" ;
VAL_ 1052 AwdLckTqNeg_B_Actl 1 "Active" 0 "Inactive" ;
VAL_ 1093 TrlBrkInitOut_D_Stat 3 "Heavy" 2 "Medium" 1 "Light" 0 "Null" ;
VAL_ 1093 TrlrBrkMde_D_Actl 1 "Electric_Over_Hydraulic" 0 "Electric" ;
VAL_ 1093 TrlrBrkDsply_B_Rq 1 "Yes" 0 "No" ;
VAL_ 1093 TrlrBrkDcnnt_B_Actl 1 "Yes" 0 "No" ;
VAL_ 1093 TrlrBrkActCnnct_B_Actl 1 "Yes" 0 "No" ;
VAL_ 1093 StopLamp_B_RqTrlrBrk 1 "Yes" 0 "No" ;
VAL_ 1093 TrlrBrkCtl_B_Falt 1 "Yes" 0 "No" ;
VAL_ 1093 TrlrBrkActCirct_B_Falt 1 "Yes" 0 "No" ;
VAL_ 837 Ccd_B_Falt 1 "Yes" 0 "No" ;
VAL_ 837 SuspVLim_B_Rq 1 "True" 0 "False" ;
VAL_ 837 SelDrvMdeSusp_D_Stat 3 "Faulty" 2 "TemporarilyNotAvailable" 1 "Available" 0 "NotAvailable" ;
VAL_ 837 AdptDrvMdePt_D_Rq 7 "Faulty" 6 "NotUsed3" 5 "NotUsed2" 4 "NotUsed1" 3 "Powertrain2Sport" 2 "Powertrain2Normal" 1 "Powertrain2Comfort" 0 "AdaptiveNotActive" ;
VAL_ 837 AdptDrvMdeChassis_D_Rq 7 "Faulty" 6 "NotUsed3" 5 "NotUsed2" 4 "NotUsed1" 3 "Chassis2Sport" 2 "Chassis2Normal" 1 "Chassis2Comfort" 0 "AdaptiveNotActive" ;
VAL_ 837 AirSprngRateRr_D_Rq 3 "NoRequest" 2 "Firm" 1 "Medium" 0 "Soft" ;
VAL_ 837 AirSprngRateRl_D_Rq 3 "NoRequest" 2 "Firm" 1 "Medium" 0 "Soft" ;
VAL_ 837 SuspType_B_Stat 1 "Magnetic" 0 "NonMagnetic" ;
VAL_ 837 AirSprngRateFr_D_Rq 3 "NoRequest" 2 "Firm" 1 "Medium" 0 "Soft" ;
VAL_ 837 AirSprngRateFl_D_Rq 3 "NoRequest" 2 "Firm" 1 "Medium" 0 "Soft" ;
VAL_ 837 AirSusp_D_Stat 3 "NotUsed" 2 "On" 1 "Off" 0 "Null" ;
VAL_ 837 AirSuspMsgTxt_D_Rq 3 "NotUsed" 2 "Faulty" 1 "Override" 0 "NoMessage" ;
VAL_ 837 SuspDrvMde_D_Stat 7 "Faulty" 6 "NotUsed2" 5 "NotUsed1" 4 "Drag" 3 "Track" 2 "Snow_Wet" 1 "Sport" 0 "Normal" ;
VAL_ 837 CcdMsgTxt_D_RqDsply 15 "Unused8" 14 "Unused7" 13 "Unused6" 12 "Unused5" 11 "Unused4" 10 "Unused3" 9 "Unused2" 8 "StationaryMode" 7 "Mode_Change_Unavailable" 6 "CCD_Temporarily_Off" 5 "CCD_Service_Required" 4 "Faulty" 3 "Sport" 2 "Normal" 1 "Comfort" 0 "No_Mode_Selected" ;
VAL_ 792 ElTrip_L_Dsply 65535 "Fault" 65534 "No_Data_Exists" ;
VAL_ 792 ElLongTerm_L_Dsply 16777215 "Fault" 16777214 "No_Data_Exists" ;
VAL_ 968 RvltnMatchAllw_D_Rq 3 "RevolutionMatchDisabled" 2 "RevolutionMatchEnabled" 1 "ChangeWithDriveMode" 0 "NoSelection" ;
VAL_ 968 BrkDrvMde_D_Rq 7 "Faulty" 6 "RockCrawl" 5 "Baja" 4 "DragOrMudAndSand" 3 "Track" 2 "Snow_Wet" 1 "Sport" 0 "Normal" ;
VAL_ 968 LnchCtl_D_Rq 3 "NotUsed2" 2 "NotUsed1" 1 "LC_On" 0 "LC_Off" ;
VAL_ 968 CurrentColor_CmdGage 15 "NotUsed7" 14 "NotUsed6" 13 "NotUsed5" 12 "NotUsed4" 11 "NotUsed3" 10 "NotUsed2" 9 "NotUsed1" 8 "Null" 7 "Color7" 6 "Color6" 5 "Color5" 4 "Color4" 3 "Color3" 2 "Color2" 1 "Color1" 0 "Off" ;
VAL_ 968 BlendedColor_CmdGage 3 "NotUsed" 2 "Null" 1 "On" 0 "Off" ;
VAL_ 968 BlendColorRed_CmdGage 15 "NotUsed10" 14 "NotUsed9" 13 "NotUsed8" 12 "NotUsed7" 11 "NotUsed6" 10 "NotUsed5" 9 "NotUsed4" 8 "NotUsed3" 7 "NotUsed2" 6 "NotUsed1" 5 "_5" 4 "_4" 3 "_3" 2 "_2" 1 "_1" 0 "Null" ;
VAL_ 968 BlendColorGrn_CmdGage 15 "NotUsed10" 14 "NotUsed9" 13 "NotUsed8" 12 "NotUsed7" 11 "NotUsed6" 10 "NotUsed5" 9 "NotUsed4" 8 "NotUsed3" 7 "NotUsed2" 6 "NotUsed1" 5 "_5" 4 "_4" 3 "_3" 2 "_2" 1 "_1" 0 "Null" ;
VAL_ 968 BlendColorBlue_CmdGage 15 "NotUsed10" 14 "NotUsed9" 13 "NotUsed8" 12 "NotUsed7" 11 "NotUsed6" 10 "NotUsed5" 9 "NotUsed4" 8 "NotUsed3" 7 "NotUsed2" 6 "NotUsed1" 5 "_5" 4 "_4" 3 "_3" 2 "_2" 1 "_1" 0 "Null" ;
VAL_ 968 Dimming_Level_Cmd 3 "Low" 2 "Not_Used" 1 "High" 0 "Null" ;
VAL_ 968 Current_Color_Cmd 15 "NotUsed7" 14 "NotUsed6" 13 "NotUsed5" 12 "NotUsed4" 11 "NotUsed3" 10 "NotUsed2" 9 "NotUsed1" 8 "Null" 7 "Color7" 6 "Color6" 5 "Color5" 4 "Color4" 3 "Color3" 2 "Color2" 1 "Color1" 0 "Off" ;
VAL_ 968 BlendedColorRed_Cmd 15 "NotUsed10" 14 "NotUsed9" 13 "NotUsed8" 12 "NotUsed7" 11 "NotUsed6" 10 "NotUsed5" 9 "NotUsed4" 8 "NotUsed3" 7 "NotUsed2" 6 "NotUsed1" 5 "_5" 4 "_4" 3 "_3" 2 "_2" 1 "_1" 0 "Null" ;
VAL_ 968 BlendedColorGreen_Cmd 15 "NotUsed10" 14 "NotUsed9" 13 "NotUsed8" 12 "NotUsed7" 11 "NotUsed6" 10 "NotUsed5" 9 "NotUsed4" 8 "NotUsed3" 7 "NotUsed2" 6 "NotUsed1" 5 "_5" 4 "_4" 3 "_3" 2 "_2" 1 "_1" 0 "Null" ;
VAL_ 968 BlendedColorBlue_Cmd 15 "NotUsed10" 14 "NotUsed9" 13 "NotUsed8" 12 "NotUsed7" 11 "NotUsed6" 10 "NotUsed5" 9 "NotUsed4" 8 "NotUsed3" 7 "NotUsed2" 6 "NotUsed1" 5 "_5" 4 "_4" 3 "_3" 2 "_2" 1 "_1" 0 "Null" ;
VAL_ 968 BlendedColor_Cmd 3 "NotUsed" 2 "Null" 1 "On" 0 "Off" ;
VAL_ 968 SuspDrvMde_D_Rq 7 "Faulty" 6 "NotUsed2" 5 "NotUsed1" 4 "Drag" 3 "Track" 2 "Snow_Wet" 1 "Sport" 0 "Normal" ;
VAL_ 968 SlMde_D_Rq 3 "IsaNotConfigured" 2 "Manual_Mode" 1 "Auto_Mode" 0 "Null" ;
VAL_ 968 IsaOffst_D_Rq 15 "Faulty" 14 "Null" 13 "Thirteen" 12 "Twelve" 11 "Eleven" 10 "Ten" 9 "Nine" 8 "Eight" 7 "Seven" 6 "Six" 5 "Five" 4 "Four" 3 "Three" 2 "Two" 1 "One" 0 "Zero" ;
VAL_ 819 WndwUpPsngrRear_D_Falt 3 "NotUsed" 2 "Fault" 1 "NoFault" 0 "Null" ;
VAL_ 819 WndwUpPsngrFront_D_Falt 3 "NotUsed" 2 "Fault" 1 "NoFault" 0 "Null" ;
VAL_ 819 Memory_3_SwPsngr_Stat 1 "Pressed" 0 "Null" ;
VAL_ 819 Memory_2_SwPsngr_Stat 1 "Pressed" 0 "Null" ;
VAL_ 819 Memory_1_SwPsngr_Stat 1 "Pressed" 0 "Null" ;
VAL_ 819 BLISLEDStatPassSide 3 "Fault" 2 "Unused" 1 "On" 0 "Off" ;
VAL_ 819 WndwPsngrSide_D_Stat 3 "BothWindow_Operating" 2 "RearWindow_Operating" 1 "FrontWindow_Operating" 0 "NoWindows_Operating" ;
VAL_ 819 Pasngr_Lock_Sw_Stat 3 "Invalid" 2 "Unlock" 1 "Lock" 0 "Null" ;
VAL_ 819 ChildLckFdbckRp_B_Stat 1 "Locked" 0 "Unlock" ;
VAL_ 819 DrPrsntPsngr_D_Stat 3 "Faulty" 2 "Present" 1 "NotPresent" 0 "NotDetermined" ;
VAL_ 819 DrPsngrMsgTxt_B_Rq 1 "Yes" 0 "No" ;
VAL_ 819 DrPrsntRearPsngr_D_Stat 3 "Faulty" 2 "Present" 1 "NotPresent" 0 "NotDetermined" ;
VAL_ 818 WndwUpDrvRear_D_Falt 3 "NotUsed" 2 "Fault" 1 "NoFault" 0 "Null" ;
VAL_ 818 WndwUpDrvFront_D_Falt 3 "NotUsed" 2 "Fault" 1 "NoFault" 0 "Null" ;
VAL_ 818 BLISLEDStatDriverSide 3 "Fault" 2 "Unused" 1 "On" 0 "Off" ;
VAL_ 818 WndwDrvSide_D_Stat 3 "BothWindow_Operating" 2 "RearWindow_Operating" 1 "FrontWindow_Operating" 0 "NoWindows_Operating" ;
VAL_ 818 KeyCylSwDrvDr_D_Stat 3 "NotUsed" 2 "Unlock" 1 "Lock" 0 "Null" ;
VAL_ 818 Driver_Lock_Sw_Stat 3 "Invalid" 2 "Unlock" 1 "Lock" 0 "Null" ;
VAL_ 818 ChildLckPw_D_Rq 1 "Active" 0 "Null" ;
VAL_ 818 ChildLckFdbckRd_B_Stat 1 "Locked" 0 "Unlock" ;
VAL_ 818 RvrseMirrorChime_B_Rq 1 "Yes" 0 "No" ;
VAL_ 818 DrvSpotLight_B_Stat 1 "Active" 0 "Inactive" ;
VAL_ 818 DrPrsntDrv_D_Stat 3 "Faulty" 2 "Present" 1 "NotPresent" 0 "NotDetermined" ;
VAL_ 818 DrPrsntRearDrv_D_Stat 3 "Faulty" 2 "Present" 1 "NotPresent" 0 "NotDetermined" ;
VAL_ 818 DrDrvMsgTxt_B_Rq 1 "Yes" 0 "No" ;
VAL_ 806 ClimtCoolRear_B_Rq 1 "On" 0 "Off" ;
VAL_ 806 ClimtHeatRear_D_Rq 7 "NotUsed4" 6 "NotUsed3" 5 "HtrCoreClntFlwOnly" 4 "PtcHtrTestMde" 3 "Defrost_Defog" 2 "FastTempPullDownHeatingReq" 1 "OpportunisticHeatingReq" 0 "NoHeatingRequest" ;
VAL_ 806 SnowPlowMde_B_Enbl 1 "Enable" 0 "Disable" ;
VAL_ 806 ClimtDeltaLoad_Pw_Actl 63 "Faulty" 62 "NoDataExists" ;
VAL_ 806 StopStrtDrvMde_B_RqBtn 1 "Pressed" 0 "Not_Pressed" ;
VAL_ 806 HtrCorePump_B_Rq 1 "On" 0 "Off" ;
VAL_ 806 ClimtHeat_D_Rq 7 "NotUsed4" 6 "NotUsed3" 5 "HtrCoreClntFlwOnly" 4 "PtcHtrTestMde" 3 "Defrost_Defog" 2 "FastTempPullDownHeatingReq" 1 "OpportunisticHeatingReq" 0 "NoHeatingRequest" ;
VAL_ 806 ClimtCool_D_Rq 7 "NotUsed4" 6 "NotUsed3" 5 "NotUsed2" 4 "ElACTestMde" 3 "Defrost_Defog" 2 "FastTempPullDownCoolReq" 1 "OpportunisticCoolingReq" 0 "NoCoolingRequest" ;
VAL_ 806 HvacEvap_Te_Actl 1023 "Fault" ;
VAL_ 806 HvacAirCond_B_Rq 1 "Yes" 0 "No" ;
VAL_ 806 ClimtPw_B_Rq 1 "Yes" 0 "No" ;
VAL_ 806 WndwFrontHeat_B_Stat 1 "On" 0 "Off" ;
VAL_ 765 BalrSwtch_D_Stat 3 "NotUsed" 2 "Pressed" 1 "NotPressed" 0 "Null" ;
VAL_ 765 BalrMde_D_Rq 3 "High" 2 "Medium" 1 "Low" 0 "Null" ;
VAL_ 765 RstrnOnPsngr_D_RqMnu 15 "Faulty" 14 "NotUsed_11" 13 "NotUsed_10" 12 "ConfiguredOff" 11 "NotUsed_9" 10 "On" 9 "NotUsed_8" 8 "NotUsed_7" 7 "NotUsed_6" 6 "NotUsed_5" 5 "Off" 4 "NotUsed_4" 3 "NotUsed_3" 2 "NotUsed_2" 1 "NotUsed_1" 0 "NoAction" ;
VAL_ 765 WaitToStartLamp_D_Falt 3 "NotUsed" 2 "Wait_to_start_lamp_failed" 1 "Diagnosis_not_ready" 0 "Wait_to_start_lamp_OK" ;
VAL_ 765 EsaOn_B_Rq 1 "On" 0 "Off" ;
VAL_ 765 BttOn_B_Rq 1 "On" 0 "Off" ;
VAL_ 765 Btt_L_Actl 127 "Faulty" 126 "NoDataExists" ;
VAL_ 765 RearDiffLck_D_RqArb 3 "Faulty" 2 "NotUsed" 1 "On" 0 "Off" ;
VAL_ 765 AwdMde_D_RqArb 7 "Faulty" 6 "NotUsed2" 5 "NoRequest" 4 "Neutral" 3 "FourByFourLow" 2 "FourByFourHigh" 1 "FourByFourAuto" 0 "FourByTwo" ;
VAL_ 765 SelDrvMdeTxtReset_B_Rq 1 "Yes" 0 "No" ;
VAL_ 765 AutoTowAllw_D_RqMnu 3 "TowHaulCommandedOn" 2 "AutoTowHaulEnabled" 1 "AutoTowHaulDisabled" 0 "NoSelection" ;
VAL_ 765 DrvInputRequired_B_Rq 1 "Yes" 0 "No" ;
VAL_ 765 SelDrvMdeDsply_B_Avail 1 "Available" 0 "NotAvailable" ;
VAL_ 765 EngExhMdeQuiet_D_Rq 3 "Faulty" 2 "QuietExhaust" 1 "LoudExhaust" 0 "Null" ;
VAL_ 765 AirSusp_D_RqDrv 3 "NotUsed" 2 "On" 1 "Off" 0 "NoModeSelected" ;
VAL_ 765 Mc_VehUntTrpCoUsrSel_St 0 "TripComputer_metric" 1 "TripComputer_imperial" ;
VAL_ 765 Mc_VehUnitTempUsrSel_St 0 "Temperature_deg_c" 1 "Temperature_deg_f" ;
VAL_ 765 Mc_VehDayNightUsrSel_St 2 "Night" 1 "Day" 0 "Invalid" ;
VAL_ 765 Mc_VehTimeFrmtUsrSel_St 2 "24h_mode" 1 "12h_mode" 0 "Invalid" ;
VAL_ 765 Mc_VehThemeUsrSel_St 2 "Theme_2" 1 "Theme_1" 0 "Invalid" ;
VAL_ 765 Mc_VehLangUsrSel_St 32 "Indian_English" 31 "Thai" 30 "Slovak" 29 "Arabic" 28 "Cantonese" 27 "Mandarin_Chinese" 26 "Korean" 25 "Japanese_Kanji" 24 "Japanese_Katakana" 23 "Braz_Portuguese" 22 "EU_Portuguese" 21 "Finish" 20 "Norwegian" 19 "Danish" 18 "Swedish" 17 "Hungarian" 16 "Greek" 15 "Czech" 14 "Polish" 13 "Flemish" 12 "Dutch" 11 "Russian" 10 "Turkish" 9 "Mex_Spanish" 8 "EU_Spanish" 7 "Cana_French" 6 "EU_French" 5 "Italian" 4 "German" 3 "NA_English" 2 "UK_English" 1 "Unknown" 0 "Invalid" ;
VAL_ 765 AwdRnge_D_ActlIpc 7 "Unknown" 6 "High_Range_2wd" 5 "High_Range_Auto" 4 "High_Range_Locked" 3 "Neutral" 2 "Low_Range_2wd" 1 "Low_Range_Auto" 0 "Low_Range_Locked" ;
VAL_ 765 AwdDrvMde_D_Rq 7 "Faulty" 6 "NotAvailable" 5 "RockCrawl" 4 "Baja" 3 "MudAndSand" 2 "Weather" 1 "Sport" 0 "Normal" ;
VAL_ 765 EngExhMdeQuiet_D2_Rq 7 "NotUsed_3" 6 "NotUsed_2" 5 "NotUsed_1" 4 "Track" 3 "Sport" 2 "Normal" 1 "Stealth" 0 "Null" ;
VAL_ 765 BrkLineLck_D_Rq 3 "Off" 2 "Engage" 1 "Initiate" 0 "NoRequest" ;
VAL_ 765 EdmSailMde_B_RqDrv 1 "On" 0 "Off" ;
VAL_ 765 Running_Board_Cmd 3 "Unused" 2 "Manually_Deployed" 1 "All_Enabled" 0 "All_Disabled" ;
VAL_ 518 RearDiffLck_Tq_Actl2 16383 "Faulty" 16382 "NoDataExists" ;
VAL_ 934 CtaAlrtLeft2_D_Stat 7 "NotUsed3" 6 "NotUsed2" 5 "NotUsed1" 4 "AlertZone4" 3 "AlertZone3" 2 "AlertZone2" 1 "AlertZone1" 0 "Off" ;
VAL_ 934 CtaBrkLeftMsgTxt_B_Rq 1 "Enable" 0 "Disable" ;
VAL_ 934 CtaLeftBrkDecel_B_Rq 1 "Enable" 0 "Disable" ;
VAL_ 934 CtaLeftBrkEnbl_B_Rq 1 "Enable" 0 "Disable" ;
VAL_ 934 BttLeft_D_Stat 7 "NotUsed" 6 "Disabled" 5 "Off" 4 "OffTemp" 3 "NotConnected" 2 "Pending" 1 "Connected" 0 "NotDetermined" ;
VAL_ 934 BttLeft_D_RqDrv 3 "NotUsed" 2 "Request" 1 "NoRequest" 0 "Null" ;
VAL_ 934 CtaSnsLeft_D_Stat 3 "Invalid" 2 "System_Failure" 1 "Blocked" 0 "Clear" ;
VAL_ 934 SodDetctLeft_D_Stat 4 "Sensor_Blocked" 3 "Sensor_Fault" 2 "Flash_On" 1 "Alert_On" 0 "AlertOff_FlashOff_SensrClr" ;
VAL_ 934 CtaLeft_D_Stat 7 "NotUsed_3" 6 "NotUsed_2" 5 "NotUsed_1" 4 "Invalid" 3 "Disabled" 2 "On" 1 "Trailer_Tow_Off" 0 "Off" ;
VAL_ 934 CtaAlrtLeft_D_Stat 1 "On" 0 "Off" ;
VAL_ 934 SodLeft_D_Stat 7 "NotUsed_3" 6 "NotUsed_2" 5 "NotUsed_1" 4 "Invalid" 3 "Disabled" 2 "On" 1 "Trailer_Tow_Off" 0 "Off" ;
VAL_ 934 SodSnsLeft_D_Stat 3 "Second_Warning_Audio" 2 "System_Failure" 1 "Blocked" 0 "Clear" ;
VAL_ 934 SodAlrtLeft_D_Stat 3 "Bulb_Proveout" 2 "Flash" 1 "On" 0 "Off" ;
VAL_ 825 WndwFrontHeat_B_Rq 1 "On" 0 "Off" ;
VAL_ 825 FdsmTrgRight_B_Actl 1 "Object_in_Right_Lobe" 0 "No_Object" ;
VAL_ 825 FdsmTrgLeft_B_Actl 1 "Object_in_Left_Lobe" 0 "No_Object" ;
VAL_ 825 FdsmTrgCntr_B_Actl 1 "Object_in_Center_Lobe" 0 "No_Object" ;
VAL_ 825 LscmbbSrvcRqd_B_Rq 1 "Yes" 0 "No" ;
VAL_ 825 LscmbbPostEvnt_B_Dsply 1 "Yes" 0 "No" ;
VAL_ 825 LscmbbEngTqMn_B_Rq 1 "Engine_Braking" 0 "No_Engine_Braking" ;
VAL_ 825 LscmbbMsgTxt_D_Rq 1 "Yes" 0 "No" ;
VAL_ 825 LscmbbDeny_B_Actl 1 "Denied" 0 "Allowed" ;
VAL_ 825 LscmbbBrkPrchg_D_Rq 3 "NotUsed" 2 "Level2_PreCharge" 1 "Level1_PreCharge" 0 "No_Precharge" ;
VAL_ 825 LscmbbBrkDecel_B_Enbl 1 "ConductLSCMbBDecelReq" 0 "DoNotConductLSCMbBDecelReq" ;
VAL_ 825 LscmbbBlck_B_Actl 1 "Yes" 0 "No" ;
VAL_ 825 LscmbbBaSens_D_Rq 3 "Level3_EBA" 2 "Level2_EBA" 1 "Level1_EBA" 0 "Norman_EBA" ;
VAL_ 1072 PtDrvMde_D_Rq 15 "Faulty" 14 "NotUsed11" 13 "NotUsed10" 12 "NotUsed9" 11 "NotUsed8" 10 "NotUsed7" 9 "NotUsed6" 8 "NotUsed5" 7 "Drag" 6 "Rock" 5 "Baja" 4 "Sand" 3 "TowHaulGradeAssist" 2 "SnowWet" 1 "Sport" 0 "Normal" ;
VAL_ 1072 DrvSlipCtlMde_D_Rq 3 "App_Specific_Off_Mode_3" 2 "App_Specific_Off_Mode_2" 1 "App_Specific_Off_Mode_1" 0 "Default_Mode" ;
VAL_ 1072 EngIdlShutDown_B_RqDrv 1 "Inhibit" 0 "No_Inibit" ;
VAL_ 1072 DrvPerfMde_D_Rq 3 "Sport" 2 "Normal" 1 "NotUsed" 0 "NoModeSelected" ;
VAL_ 1072 HsaMde_D_Rq 3 "Undefined" 2 "Manual" 1 "Automatic" 0 "Off" ;
VAL_ 1072 StopStrtDrvMde_D_RqMnu 3 "NotUsed2" 2 "NotUsed1" 1 "StopStart_Deselected" 0 "StopStart_Selected" ;
VAL_ 1072 NtrlTowMdeEnbl_B_RqDrv 1 "Yes" 0 "No" ;
VAL_ 1072 LscmbbStat_B_Actl 1 "On" 0 "Off" ;
VAL_ 1072 BulbChkActv_B_Stat 1 "Active" 0 "Inactive" ;
VAL_ 1072 ParkDetect_Stat 1 "Park" 0 "Not_Park" ;
VAL_ 1072 ReducedGuard_D_Rq 3 "NotUsed" 2 "On" 1 "Off" 0 "Null" ;
VAL_ 1072 FrostWarn_D_Stat 3 "NotUsed" 2 "On_Amber" 1 "On_Red" 0 "Off" ;
VAL_ 1072 TrlrBrkMde_D_Rq 1 "ElectricOverHydraulic" 0 "Electric" ;
VAL_ 1072 TRLR_SWAY_CONFIG_CMD 1 "On" 0 "Off" ;
VAL_ 1072 TRAILER_BRAKE_CONFIG 1 "Yes" 0 "No" ;
VAL_ 1072 Power_Liftgate_Mode_Cmd 1 "Enable" 0 "Disable" ;
VAL_ 1072 AccEnbl_B_RqDrv 1 "Adaptive_Cruise" 0 "Normal_Cruise" ;
VAL_ 1072 OdometerMasterValue 16777215 "Invalid" ;
VAL_ 1072 EngOilLife_B_RqReset 1 "Yes" 0 "No" ;
VAL_ 1072 MetricActvTe_B_Actl 1 "Active" 0 "Inactive" ;
VAL_ 1072 AccDeny_B_RqIpc 1 "Yes" 0 "No" ;
VAL_ 1072 ePRNDL_MODE 1 "On" 0 "Off" ;
VAL_ 1072 PrkLckCtlEnbl_D_RqIpc 3 "Rq_Towing" 2 "Rq_Enable" 1 "Rq_Disable" 0 "Null" ;
VAL_ 1072 DrvSlipCtlMde_B_Rq2 1 "Pressed" 0 "Not_Pressed" ;
VAL_ 1072 MetricActv_B_Actl 1 "Active" 0 "Inactive" ;
VAL_ 1072 KeyTypeChngMykey_D_Rq 3 "Search_PE_BackupSlot" 2 "Clear_All_MyKeys" 1 "Request_New_MyKey" 0 "None" ;
VAL_ 1072 ManRgen_D_Rq 3 "NotUsed2" 2 "NotUsed1" 1 "CustInitManExhFilterClean" 0 "No_Customer_Request" ;
VAL_ 1072 Fda_B_Stat 1 "On" 0 "Off" ;
VAL_ 1072 HaDsplyCpblty_B_Stat 1 "Available" 0 "NotAvailable" ;
VAL_ 909 IgnPsswrdDsply_B_Rq 1 "Active" 0 "Inactive" ;
VAL_ 909 ElPwPoint_D_Rq 3 "On" 2 "Off2" 1 "Off1" 0 "Null" ;
VAL_ 909 PoliceIdlMde_D_Stat 15 "NotUsed_7" 14 "NotUsed_6" 13 "NotUsed_5" 12 "NotUsed_4" 11 "NotUsed_3" 10 "NotUsed_2" 9 "PepsActive" 8 "Decommissioned" 7 "ActiveFault" 6 "ArmFault" 5 "PrearmedFault" 4 "OffFault" 3 "Active" 2 "Arm" 1 "Prearmed" 0 "Off" ;
VAL_ 909 DrLatchMsgTxt_D_Rq 7 "Message7" 6 "Message6" 5 "Message5" 4 "Message4" 3 "Message3" 2 "Message2" 1 "Message1" 0 "NoMessage" ;
VAL_ 909 WiprFront_D_Stat2 15 "NO_DATA_EXISTS" 14 "STALLED" 13 "NotUsed" 12 "AUTO_ADJUST" 11 "COURTESYWIPE" 10 "AUTO_HIGH" 9 "AUTO_LOW" 8 "WASH" 7 "MIST_FLICK" 6 "MAN_HIGH" 5 "MAN_LOW" 4 "MAN_INT_ON" 3 "MAN_INT_OFF" 2 "OFF_MOVING" 1 "AUTO_OFF" 0 "OFF" ;
VAL_ 909 SecurityMsgTxt_D_Rq 3 "Message3" 2 "Message2" 1 "Message1" 0 "NoMessage" ;
VAL_ 909 PrmtrAlrmEvnt_D_Stat 15 "Diag_Tamper" 14 "Trailer" 13 "Shock_Sensor" 12 "Post_Crash" 11 "Panic" 10 "Intrusion" 9 "Inclination" 8 "Ign_Tamper" 7 "LG_Door" 6 "Decklid" 5 "Hood" 4 "PR_Door" 3 "PF_Door" 2 "DR_Door" 1 "DF_Door" 0 "Null" ;
VAL_ 909 TurnLghtSwtch_D_Stat2 3 "NotUsed" 2 "Right" 1 "Left" 0 "Off" ;
VAL_ 909 HeadLghtHiPrmsn_D_Stat 3 "CancelAndSuppress" 2 "Cancel" 1 "Hold" 0 "AllowChange" ;
VAL_ 909 SteWhlLckMsgTxt_D_Rq 3 "NotUsed" 2 "Message_2" 1 "Message_1" 0 "No_Message" ;
VAL_ 909 immoMsgTxt_D_Rq 15 "Immo_Msg_15" 14 "Immo_Msg_14" 13 "Immo_Msg_13" 12 "Immo_Msg_12" 11 "Immo_Msg_11" 10 "Immo_Msg_10" 9 "Immo_Msg_9" 8 "Immo_Msg_8" 7 "Immo_Msg_7" 6 "Immo_Msg_6" 5 "Immo_Msg_5" 4 "Immo_Msg_4" 3 "Immo_Msg_3" 2 "Immo_Msg_2" 1 "Immo_Msg_1" 0 "Immo_Msg_0_Null" ;
VAL_ 909 PrsnlDevcChrgEnbl_B_Rq 1 "Active" 0 "Inactive" ;
VAL_ 909 TracKeyMde_D_Stat 3 "NotUsed" 2 "NotActive" 1 "Active" 0 "ModeNotDetermined" ;
VAL_ 909 PEBackupSlot_Stats 3 "No_Valid_FOB_In_Slot" 2 "MyKey_FOB_In_Slot" 1 "Standard_FOB_In_Slot" 0 "Null" ;
VAL_ 909 KeyMykeyTot_No_Cnt 13 "Thirteen" 12 "Twelve" 11 "Eleven" 10 "Ten" 9 "Nine" 8 "Eight" 7 "Seven" 6 "Six" 5 "Five" 4 "Four" 3 "Three" 2 "Two" 1 "One" 0 "Zero" 15 "Invalid" 14 "Unlimited" ;
VAL_ 909 KeyAdmnTot_No_Cnt 13 "Thirteen" 12 "Twelve" 11 "Eleven" 10 "Ten" 9 "Nine" 8 "Eight" 7 "Seven" 6 "Six" 5 "Five" 4 "Four" 3 "Three" 2 "Two" 1 "One" 0 "Zero" 15 "Invalid" 14 "Unlimited" ;
VAL_ 909 HazrdLght_B_Stat 1 "On" 0 "Off" ;
VAL_ 963 Illuminated_Entry_Stat 3 "Invalid" 2 "Unknown" 1 "On" 0 "Off" ;
VAL_ 963 Dr_Courtesy_Light_Stat 3 "Invalid" 2 "Unknown" 1 "On" 0 "Off" ;
VAL_ 963 Courtesy_Delay_Status 3 "Invalid" 2 "Unknown" 1 "On" 0 "Off" ;
VAL_ 963 ImpactEvntFdbck_D_Stat 3 "NotUsed" 2 "EventComplete" 1 "EventInProgress" 0 "Normal" ;
VAL_ 963 WrlssAcsyChrgInhbt_B_Rq 1 "Yes" 0 "No" ;
VAL_ 963 PudLampPsngr_D_Rq 3 "Ramp_Down" 2 "Ramp_Up" 1 "On" 0 "Off" ;
VAL_ 963 HeadLampLoOut_B_Stat 1 "Out" 0 "Null" ;
VAL_ 963 HeadLghtHiFdbck_D_Stat 3 "NotUsed" 2 "Cancel" 1 "Hold" 0 "Allow_Change" ;
VAL_ 963 PudLampDrv_D_Rq 3 "Ramp_Down" 2 "Ramp_Up" 1 "On" 0 "Off" ;
VAL_ 963 TrnNotInPrkChime_B_Rq 1 "On" 0 "Off" ;
VAL_ 963 PrkLightChime_B_Rq 1 "On" 0 "Off" ;
VAL_ 963 KeyInIgnWarn_B_Cmd 1 "On" 0 "Off" ;
VAL_ 963 HomeSafeLtChime_B_Rq 1 "On" 0 "Off" ;
VAL_ 963 StopLghtOn_B_Stat 1 "On" 0 "Off" ;
VAL_ 963 RvrseLghtOn_B_Stat 1 "On" 0 "Off" ;
VAL_ 963 PrkLght_D_Stat 3 "Park_Both" 2 "Park_Right" 1 "Park_Left" 0 "Off" ;
VAL_ 963 HeadLghtSwtch_D_Stat 3 "Autolamp" 2 "Headlamp" 1 "Parklamp" 0 "Off" ;
VAL_ 963 HeadLampLoFrOn_B_Stat 1 "Low" 0 "Not_Low" ;
VAL_ 963 HeadLampLoFlOn_B_Stat 1 "Low" 0 "Not_Low" ;
VAL_ 963 HeadLampLoActv_B_Stat 1 "On" 0 "Off" ;
VAL_ 963 Headlamp_On_Wrning_Cmd 1 "On" 0 "Off" ;
VAL_ 963 Park_Brake_Chime_Rqst 1 "On" 0 "Off" ;
VAL_ 963 HeadLghtHiOn_B_Stat 1 "On" 0 "Off" ;
VAL_ 963 BrkWarnInd_B_Rq 1 "On" 0 "Off" ;
VAL_ 963 Brk_Fluid_Lvl_Low 3 "Invalid" 2 "Unknown" 1 "Low" 0 "OK" ;
VAL_ 963 ReducedGuard_D_Stat 3 "NotUsed" 2 "Alarm_On" 1 "Alarm_Off_Previously_On" 0 "Alarm_Off" ;
VAL_ 963 Perimeter_Alarm_Status 3 "Activated" 2 "Armed" 1 "Prearmed" 0 "Disarmed" ;
VAL_ 963 Courtesy_BSave_Stat 3 "Invalid" 2 "Unknown" 1 "No_Effect" 0 "Off" ;
VAL_ 963 DrTgateLck_D_Stat 3 "NotUsed" 2 "Unlock" 1 "Lock" 0 "Null" ;
VAL_ 963 WndwGlbl_D_Cmd 7 "NotUsed3" 6 "NotUsed2" 5 "NotUsed1" 4 "GLEARN" 3 "GCLOSE" 2 "GOPEN" 1 "GSTOP" 0 "Null" ;
VAL_ 963 PudLamp_D_Rq 3 "RAMP_DOWN" 2 "RAMP_UP" 1 "ON" 0 "OFF" ;
VAL_ 963 PerimeterAlarmChimeRq 1 "On" 0 "Off" ;
VAL_ 963 DayRnngLampOn_B_Stat 1 "On" 0 "Off" ;
VAL_ 145 VehYawWActl_D_Qf 3 "OK" 2 "Not_Within_Specifications" 1 "No_Data_Exists" 0 "Faulty" ;
VAL_ 145 VehRolWActl_D_Qf 3 "OK" 2 "Not_Within_Specifications" 1 "No_Data_Exists" 0 "Faulty" ;
VAL_ 145 VehYaw_W_Actl 65535 "Faulty" 65534 "NoDataExists" ;
VAL_ 145 VehRol_W_Actl 65535 "Faulty" 65534 "NoDataExists" ;
VAL_ 76 RstrnPsngrOn_D_Stat 15 "Faulty" 14 "NotUsed_11" 13 "NotUsed_10" 12 "ConfiguredOff" 11 "NotUsed_9" 10 "On" 9 "NotUsed_8" 8 "NotUsed_7" 7 "NotUsed_6" 6 "NotUsed_5" 5 "Off" 4 "NotUsed_4" 3 "NotUsed_3" 2 "NotUsed_2" 1 "NotUsed_1" 0 "NoAction" ;
VAL_ 76 PsngrFmidDetct_D_Actl 3 "Unknown" 2 "Empty" 1 "Occupied" 0 "Fault" ;
VAL_ 76 FirstRowBuckleMid 3 "Unknown" 2 "Unbelted" 1 "Belted" 0 "Faulty" ;
VAL_ 76 ThirdRowBucklePsngr 3 "Unknown" 2 "Unbelted" 1 "Belted" 0 "Faulty" ;
VAL_ 76 ThirdRowBuckleMid 3 "Unknown" 2 "Unbelted" 1 "Belted" 0 "Faulty" ;
VAL_ 76 ThirdRowBuckleDriver 3 "Unknown" 2 "Unbelted" 1 "Belted" 0 "Faulty" ;
VAL_ 76 SecondRowBucklePsngr 3 "Unknown" 2 "Unbelted" 1 "Belted" 0 "Faulty" ;
VAL_ 76 SecondRowBuckleMid 3 "Unknown" 2 "Unbelted" 1 "Belted" 0 "Faulty" ;
VAL_ 76 SecondRowBuckleDriver 3 "Unknown" 2 "Unbelted" 1 "Belted" 0 "Faulty" ;
VAL_ 76 FirstRowBuckleDriver 3 "Unknown" 2 "Unbelted" 1 "Belted" 0 "Faulty" ;
VAL_ 76 RILReq 3 "Not_Used" 2 "Plant_Mode" 1 "On" 0 "Off" ;
VAL_ 76 FirstRowBucklePsngr 3 "Unknown" 2 "Unbelted" 1 "Belted" 0 "Faulty" ;
VAL_ 76 RstrnImpactEvntStatus 7 "Invalid" 6 "Not_Used_4" 5 "Threshold_2_Exceeded" 4 "Not_Used_3" 3 "Threshold_1_Exceeded" 2 "Not_Used_2" 1 "Not_Used_1" 0 "Normal" ;
VAL_ 76 PsngrFrntDetct_D_Actl 3 "Unknown" 2 "Empty" 0 "Faulty" 1 "Occupied" ;
VAL_ 76 EDRTriggerEvntSync 1 "Threshold_Exceeded" 0 "Normal" ;
VAL_ 76 PassRstrnInd_Req 3 "ABOnNotIllum_OffNotIllum" 2 "AirbagOnNot_Illum_OffIllum" 1 "AirbagOn_Illum_OffNotIllum" 0 "AirbagOn_Illum_Off_Illum" ;
VAL_ 65 immoControlCmd_T1 0 "IDLE" 1 "MOTIVE_START_RQST" 2 "NONMOTIVE_START_RQST" 3 "RQST_TARGET1_IDBLOCK1" 4 "RQST_TARGET1_IDBLOCK2" 5 "LIMITEDMOTIVE_START_RQST" 6 "ECHO_TARGET1_IDBLOCK2" 7 "SHUTDOWN" ;
VAL_ 1076 AutoRgen_D_Rq 3 "NotUsed" 2 "AutExhFilterCleanOFF" 1 "AutExhFilterCleanON" 0 "No_Mode_Selected" ;
VAL_ 1076 W2S_LAMP_OK 1 "Yes" 0 "No" ;
VAL_ 1076 OdoTripRx_B_Actl 1 "Yes" 0 "No" ;
VAL_ 1076 DrvSlipCtlMde_B_RqMyKey 1 "On" 0 "Off" ;
VAL_ 1076 FuelLvlWarn_D_Actl 3 "NotUsed" 2 "VeryLow" 1 "Low" 0 "OK" ;
VAL_ 1076 DieslFuelBio_B_ActlDrv 1 "Biodiesel_User" 0 "Non_Biodiesel_User" ;
VAL_ 1076 FuelSecndActv_B_Actl 1 "Yes" 0 "No" ;
VAL_ 1076 HILL_DESC_SW 1 "On" 0 "Off" ;
VAL_ 1076 FUEL_SENSOR_NUM 1 "Dual_Sensors" 0 "Single_Sensor" ;
VAL_ 1076 TirePReset_B_Rq 1 "Reset" 0 "Null" ;
VAL_ 836 Foh_D_Stat 7 "Unused3" 6 "Unused2" 5 "Unused1" 4 "Stopping" 3 "Running" 2 "Starting" 1 "Prestart" 0 "Off" ;
VAL_ 836 EngClnt_Te_ActlFoh 255 "Fault" ;
VAL_ 836 FohFalt_D_Stat 15 "NotUsed4" 14 "NotUsed3" 13 "NotUsed2" 12 "NotUsed1" 11 "FuelTypeDoesNotMatchFOH" 10 "Lifecycle_ModeNotSet" 9 "AuxElectricCoolantPumpInop" 8 "TimeDelayAvoidExcessCycl" 7 "Fuel_Level_OutofRange" 6 "External_Fault" 5 "Internal_Fault" 4 "Voltage_limitation" 3 "Impact_Event" 2 "CoolantTemp_OutofRange" 1 "AmbientTemp_OutofRange" 0 "No_Disable" ;
VAL_ 836 FohEnbl_B_RqDrv 1 "On" 0 "Off" ;
VAL_ 836 FohRqRun_B_Rq 1 "SubmitRequest_toRun" 0 "DoesNotSubmitRequest_toRun" ;
VAL_ 836 HvacPrecondMode_D_Rq 15 "NotUsed4" 14 "NotUsed3" 13 "NotUsed2" 12 "NotUsed1" 11 "Last_User_Settings" 10 "Auto" 9 "Max_Defrost" 8 "Windshield_Panel_Floor" 7 "Windshield_Panel" 6 "Windshield" 5 "Windshield_Floor" 4 "Floor" 3 "Panel_Floor" 2 "Panel" 1 "MAX_AC" 0 "Off" ;
VAL_ 836 HvacPrecondBlwr_D_Rq 15 "NotUsed6" 14 "NotUsed5" 13 "NotUsed4" 12 "NotUsed3" 11 "NotUsed2" 10 "NotUsed1" 9 "Last_User_Setting" 8 "Auto" 7 "Speed7" 6 "Speed6" 5 "Speed5" 4 "Speed4" 3 "Speed3" 2 "Speed2" 1 "Speed1" 0 "Off" ;
VAL_ 862 EcoMde_D_RqDrv 3 "Faulty" 2 "On" 1 "Off" 0 "Null" ;
VAL_ 862 TwHlGrdAsst_B_RqTrn 1 "On" 0 "Off" ;
VAL_ 862 ApaSwtch_D_RqDrv 3 "NotUsed2" 2 "NotUsed1" 1 "Pressed" 0 "Not_Pressed" ;
VAL_ 862 HvacBlwrFront_D_Stat 31 "Not_Used" 20 "Full_On" 19 "95_Percent" 18 "90_Percent" 17 "85_Percent" 16 "80_Percent" 15 "75_Percent" 14 "70_Percent" 13 "65_Percent" 12 "60_Percent" 11 "55_Percent" 10 "50_Percent" 9 "45_Percent" 8 "40_Percent" 7 "35_Percent" 6 "30_Percent" 5 "25_Percent" 4 "20_Percent" 3 "15_Percent" 2 "10_Percent" 1 "5_Percent" 0 "Off" ;
VAL_ 862 HvacBlwrRear_D_Stat 31 "Not_Used" 20 "Full_On" 19 "95_Percent" 18 "90_Percent" 17 "85_Percent" 16 "80_Percent" 15 "75_Percent" 14 "70_Percent" 13 "65_Percent" 12 "60_Percent" 11 "55_Percent" 10 "50_Percent" 9 "45_Percent" 8 "40_Percent" 7 "35_Percent" 6 "30_Percent" 5 "25_Percent" 4 "20_Percent" 3 "15_Percent" 2 "10_Percent" 1 "5_Percent" 0 "Off" ;
VAL_ 862 CabnAmb_Te_Actl 255 "Fault" ;
VAL_ 862 ClimtThrmlLoad_No_Actl 255 "Fault" ;
VAL_ 862 CamraDefog_B_Actl 1 "On" 0 "Off" ;
VAL_ 862 AutoStpHvacDelta_I_Est 255 "Fault" ;
VAL_ 931 VehOnSrc_D_Stat 15 "NotUsed_11" 14 "NotUsed_10" 13 "NotUsed_9" 12 "NotUsed_8" 11 "NotUsed_7" 10 "NotUsed_6" 9 "NotUsed_5" 8 "NotUsed_4" 7 "SecureIdle" 6 "FleetVehicleInhibit" 5 "StolenVehicleInhibit" 4 "OverTheAir" 3 "RemoteParkAssist" 2 "RemoteStart" 1 "Manual" 0 "Off" ;
VAL_ 931 EngStrtActv_B_Stat 1 "Active" 0 "Inactive" ;
VAL_ 931 EngStrt_B_Rq 1 "Request" 0 "NoRequest" ;
VAL_ 931 DrvInCtl_B_Stat 1 "Yes" 0 "No" ;
VAL_ 931 PtWakeReas_D_Stat 15 "NotUsed_9" 14 "NotUsed_8" 13 "NotUsed_7" 12 "NotUsed_6" 11 "NotUsed_5" 10 "NotUsed_4" 9 "NotUsed_3" 8 "NotUsed_2" 7 "NotUsed_1" 6 "ElapsedTime" 5 "ThirdPartyWakeup" 4 "DoorAjar" 3 "EarlyWake" 2 "NonMotiveStart" 1 "MotiveStart" 0 "Null" ;
VAL_ 931 CrnkInhbt_B_Stat 1 "Inhibit" 0 "NoInhibit" ;
VAL_ 931 IgnPreOffActv_B_Stat 1 "Active" 0 "Inactive" ;
VAL_ 578 PtLatchActv_B_RqBcm 1 "On" 0 "Off" ;
VAL_ 578 immoSecureIdleMode 3 "NotUsed2" 2 "NotUsed1" 1 "Active" 0 "Inactive" ;
VAL_ 578 ReFuelSwtchStat_D_Actl 3 "NotUsed2" 2 "NotUsed1" 1 "On" 0 "Off" ;
VAL_ 578 FuelPumpPwr_D_Stat 7 "NotUsed3" 6 "NotUsed2" 5 "NotUsed1" 4 "Power_Off_Default" 3 "Power_Off_Command" 2 "Power_Off_Service" 1 "Power_Off_Impact" 0 "Power_On" ;
VAL_ 578 BattULo_U_Actl 255 "Fault" ;
VAL_ 578 PrkLckCtl_B_Enbl 1 "Enable" 0 "Disable" ;
VAL_ 578 PrkLckCtlMsgTxt_D_Rq 3 "BTSI_DI_3" 2 "BTSI_DI_2" 1 "BTSI_DI_1" 0 "Null_BTSI_DI" ;
VAL_ 578 BrkTrnShifLck_B_Stat 1 "Shift" 0 "NoShift" ;
VAL_ 578 PrkLckCtlUnlck_D_Stat 3 "Trans_And_Steer_Unlckd" 2 "Steering_Unlckd" 1 "Transmission_Unlckd" 0 "Null" ;
VAL_ 578 PrkLckCtlTow_B_Enbl 1 "Enable" 0 "Disable" ;
VAL_ 578 DriverCrankingReq 1 "Crank_Request" 0 "No_Crank_Request" ;
VAL_ 578 EngOff_T_Actl 65535 "Invalid" ;
VAL_ 578 DcacElPw_D_Rq 3 "NotUsed" 2 "AC_HighPower_Requested" 1 "AC_LowPower_Requested" 0 "AC_Power_NotRequested" ;
VAL_ 578 BattULo_I_Actl 16383 "Fault" ;
VAL_ 947 ValetMode_D_Mem 1 "On" 0 "Off" ;
VAL_ 947 DrStatDrvErrCnt_B_Stat 1 "Yes" 0 "No" ;
VAL_ 947 TurnLghtRight_D_Rq 3 "Seq" 2 "On" 1 "Off" 0 "Null" ;
VAL_ 947 TurnLghtRightOn_B_Stat 1 "On" 0 "Off" ;
VAL_ 947 TurnLghtLeftOn_B_Stat 1 "On" 0 "Off" ;
VAL_ 947 FogLghtRearOn_B_Stat 1 "On" 0 "Off" ;
VAL_ 947 Backlit_LED_Status 15 "Unused3" 14 "Unused2" 13 "Unused1" 12 "Night_12" 11 "Night_11" 10 "Night_10" 9 "Night_9" 8 "Night_8" 7 "Night_7" 6 "Night_6" 5 "Night_5" 4 "Night_4" 3 "Night_3" 2 "Night_2" 1 "Night_1" 0 "Off" ;
VAL_ 947 TurnLghtLeft_D_Rq 3 "Seq" 2 "On" 1 "Off" 0 "Null" ;
VAL_ 947 FogLghtFrontOn_B_Stat 1 "On" 0 "Off" ;
VAL_ 947 IgnKeyType_D_Actl 15 "Invalid" 14 "Unknown" 3 "Key_Not_Prgrm_Read_Failure" 2 "Key_In_Ign_My_Key" 1 "Key_In_Ign_Standard_Key" 0 "Key_Read_In_Progress" ;
VAL_ 947 Parklamp_Status 3 "Invalid" 2 "Unknown" 1 "On" 0 "Off" ;
VAL_ 947 Litval 255 "Invalid" 254 "Unknown" 5 "Day" 4 "Twilight_4" 3 "Twilight_3" 2 "Twilight_2" 1 "Twilight_1" 0 "Night" ;
VAL_ 947 Key_In_Ignition_Stat 1 "In" 0 "Out" ;
VAL_ 947 Ignition_Status 0 "Unknown" 1 "Off" 15 "Invalid" 8 "Start" 4 "Run" 2 "Accessory" ;
VAL_ 947 Dimming_Lvl 255 "Invalid" 254 "Unknown" 18 "Day_6" 17 "Day_5" 16 "Day_4" 15 "Day_3" 14 "Day_2" 13 "Day_1" 12 "Night_12" 11 "Night_11" 10 "Night_10" 9 "Night_9" 8 "Night_8" 7 "Night_7" 6 "Night_6" 5 "Night_5" 4 "Night_4" 3 "Night_3" 2 "Night_2" 1 "Night_1" 0 "Off" ;
VAL_ 947 Day_Night_Status 3 "NotUsed" 2 "Night" 1 "Day" 0 "Null" ;
VAL_ 947 Remote_Start_Status 3 "Invalid" 2 "Unknown" 1 "Remote" 0 "Null" ;
VAL_ 947 DrStatTgate_B_Actl 1 "Ajar" 0 "Closed" ;
VAL_ 947 DrStatRr_B_Actl 1 "Ajar" 0 "Closed" ;
VAL_ 947 DrStatRl_B_Actl 1 "Ajar" 0 "Closed" ;
VAL_ 947 DrStatPsngr_B_Actl 1 "Ajar" 0 "Closed" ;
VAL_ 947 DrStatInnrTgate_B_Actl 1 "Ajar" 0 "Closed" ;
VAL_ 947 DrStatHood_B_Actl 1 "Ajar" 0 "Closed" ;
VAL_ 947 DrStatDrv_B_Actl 1 "Ajar" 0 "Closed" ;
VAL_ 947 PrkBrkActv_B_Actl 1 "Active" 0 "Inactive" ;
VAL_ 947 LifeCycMde_D_Actl 3 "Transport" 2 "NotUsed" 1 "Factory" 0 "Normal" ;
VAL_ 947 Delay_Accy 1 "On" 0 "Off" ;
VAL_ 947 CrashEvnt_D_Stat 3 "Invalid" 2 "Fuel_Cutoff_Event" 1 "Deploy_Event" 0 "No_Event" ;
VAL_ 947 FuelPmpInhbt_B_Stat 1 "Inhibit" 0 "No_Inibit" ;
VAL_ 947 BodySrvcRqd_B_Rq 1 "Yes" 0 "No" ;
VAL_ 1084 BattULoState_D_Qlty 3 "OK" 2 "Not_Within_Specifications" 1 "Eval_In_Progress" 0 "Fault" ;
VAL_ 1084 BSFault 1 "Fault" 0 "No_Fault" ;
VAL_ 1084 BattULo2_Te_Actl 127 "Fault" ;
VAL_ 1068 EngStrtInhbt_B_RqBatt 1 "Start_Inhibit" 0 "Dont_Care" ;
VAL_ 1068 BattULoChrg_D_Rq 3 "Low_Battery_Temperature" 2 "Charging_Requested" 1 "Chrg_Requested_HighCurrent" 0 "No_Request" ;
VAL_ 1068 PwSysULoFalt_D_Stat 15 "Not_Used_6" 14 "LowBatterySOC" 13 "PSS_Shed2_Contin" 12 "Not_Used_4" 11 "Not_Used_3" 10 "Not_Used_2" 9 "BattMonitoringSensorFault" 8 "LowBattVoltDuringPwSrcOn" 7 "LowBatt2_PowerSaveMode" 6 "LowBatt1_Warning" 5 "Overvoltage" 4 "Fault_NoOutput" 3 "Fault_ReducedOutput" 2 "Fault_Nonspecific" 1 "Cluster_Proveout" 0 "No_Fault" ;
VAL_ 1068 Shed_T_Eng_Off_B 1 "Active" 0 "Inactive" ;
VAL_ 1068 Shed_Feature_Group_ID 16 "PtcHeater" 30 "NotUsed_7" 29 "NotUsed_6" 28 "NotUsed_5" 27 "NotUsed_4" 26 "NotUsed_3" 25 "NotUsed_2" 24 "NotUsed_1" 23 "Dcac" 22 "UpFitter_6" 21 "UpFitter_5" 20 "UpFitter_4" 19 "UpFitter_3" 18 "UpFitter_2" 17 "UpFitter_1" 14 "HtdMirr" 13 "HvacRearBlwr_Third" 12 "HvacRearBlwr_Second" 11 "HvacRearBlwr_First" 31 "All LSHED1 Features" 10 "Htd_Windscrn" 9 "SpltHtdBcklight_HtdMirr" 8 "HtdBcklight_HtdMirr" 7 "HtdCoolSeat_FrtDriver" 6 "HtdCoolSeat_FrtPass" 5 "HtdCoolSeat_RearPass" 4 "HtdCoolSeat_RearDriver" 3 "SmartTrlrTowBattCharge" 2 "Htd_StrWhl" 1 "Htd_Washer_Fluid" 0 "No_LSHED1_Features" 15 "Engine_Coolant_Fan" ;
VAL_ 1068 Shed_Drain_Eng_Off_B 1 "Active" 0 "Inactive" ;
VAL_ 1068 Shed_Level_Req 7 "SHED3" 6 "Loads_On" 5 "SHED_ENG_OFF" 4 "SOON_ENG_OFF" 3 "SHED2_CONTIN" 2 "SHED2_TRANS" 1 "SHED1" 0 "NO_SHED" ;
VAL_ 1068 ULoRgenTestMde_B_Rq 1 "Request" 0 "NoRequest" ;
VAL_ 1068 ChargeMode 7 "Undefined_2" 6 "Undefined_1" 5 "Battery_Identify" 4 "Battery_Refresh" 3 "SlowRegenAllowNoDischarge" 2 "Fast_Regen_Allowed" 1 "Slow_Regen_Allowed" 0 "Conventional_Charging" ;
VAL_ 1068 IdleSpeedIncrease_El 1 "Yes" 0 "No" ;
VAL_ 1068 Batt_Lo_SoC_B 1 "Active" 0 "Inactive" ;
VAL_ 1068 PeriodicElLoad_B_Stat 1 "Active" 0 "Inactive" ;
VAL_ 1068 Batt_Crit_SoC_B 1 "Active" 0 "Inactive" ;
SIG_GROUP_ 145 SG_Yaw_Data_FD1 1 : VehYawWActl_D_Qf VehRolWActl_D_Qf VehRollYawW_No_Cs VehRollYaw_No_Cnt VehRol_W_Actl VehYaw_W_Actl;
SIG_GROUP_ 76 SG_RCMStatusMessage2_FD1 1 : FirstRowBuckleMid FirstRowBuckleDriver FirstRowBucklePsngr RCMStatusMsg2_No_Cnt FirstRowBuckle_No_Cs;
